VERSION ""

NS_ :

BS_:

BU_: FRM ADC CRFL CRFR CRRL CRRR AVP APA

BO_ 3221225472 VECTOR__INDEPENDENT_SIG_MSG: 0 Vector__XXX
 SG_ CRRL_KeepAwakePwrMode : 0|1@0+ (1,0) [0|1] "" Vector__XXX
 SG_ CRRL_KeepAwakeReasDiag : 0|1@0+ (1,0) [0|1] "" Vector__XXX
 SG_ CRRL_KeepAwakeReasLocalFunReq : 0|5@0+ (1,0) [0|31] "" Vector__XXX
 SG_ CRRL_KeepAwakeSta : 0|1@0+ (1,0) [0|1] "" Vector__XXX
 SG_ CRRR_WakeupReas : 0|8@0+ (1,0) [0|255] "" Vector__XXX
 SG_ CRRR_KeepAwakePwrMode : 0|1@0+ (1,0) [0|1] "" Vector__XXX
 SG_ CRRR_KeepAwakeReasDiag : 0|1@0+ (1,0) [0|1] "" Vector__XXX
 SG_ CRRR_KeepAwakeReasLocalFunReq : 0|5@0+ (1,0) [0|31] "" Vector__XXX
 SG_ CRRR_KeepAwakeSta : 0|1@0+ (1,0) [0|1] "" Vector__XXX
 SG_ AVP_WakeupReas : 0|8@0+ (1,0) [0|255] "" Vector__XXX
 SG_ AVP_KeepAwakePwrMode : 0|1@0+ (1,0) [0|1] "" Vector__XXX
 SG_ AVP_KeepAwakeReasDiag : 0|1@0+ (1,0) [0|1] "" Vector__XXX
 SG_ AVP_KeepAwakeReasLocalFunReq : 0|5@0+ (1,0) [0|31] "" Vector__XXX
 SG_ AVP_KeepAwakeSta : 0|1@0+ (1,0) [0|1] "" Vector__XXX
 SG_ Diag_PhyReq_FRM_Data0 : 0|64@0+ (1,0) [0|0] "" Vector__XXX
 SG_ Diag_PhyReq_FRM_Data1 : 0|64@0+ (1,0) [0|0] "" Vector__XXX
 SG_ Diag_PhyReq_FRM_Data2 : 0|64@0+ (1,0) [0|0] "" Vector__XXX
 SG_ Diag_PhyReq_FRM_Data3 : 0|64@0+ (1,0) [0|0] "" Vector__XXX
 SG_ Diag_PhyReq_FRM_Data4 : 0|64@0+ (1,0) [0|0] "" Vector__XXX
 SG_ Diag_PhyReq_FRM_Data5 : 0|64@0+ (1,0) [0|0] "" Vector__XXX
 SG_ Diag_PhyReq_FRM_Data6 : 0|64@0+ (1,0) [0|0] "" Vector__XXX
 SG_ Diag_PhyReq_FRM_Data7 : 0|64@0+ (1,0) [0|0] "" Vector__XXX
 SG_ Diag_PhyReq_FCM_Data0 : 0|64@0+ (1,0) [0|0] "" Vector__XXX
 SG_ Diag_PhyReq_FCM_Data1 : 0|64@0+ (1,0) [0|0] "" Vector__XXX
 SG_ Diag_PhyReq_FCM_Data2 : 0|64@0+ (1,0) [0|0] "" Vector__XXX
 SG_ Diag_PhyReq_FCM_Data3 : 0|64@0+ (1,0) [0|0] "" Vector__XXX
 SG_ Diag_PhyReq_FCM_Data4 : 0|64@0+ (1,0) [0|0] "" Vector__XXX
 SG_ Diag_PhyReq_FCM_Data5 : 0|64@0+ (1,0) [0|0] "" Vector__XXX
 SG_ Diag_PhyReq_FCM_Data6 : 0|64@0+ (1,0) [0|0] "" Vector__XXX
 SG_ Diag_PhyReq_FCM_Data7 : 0|64@0+ (1,0) [0|0] "" Vector__XXX
 SG_ Diag_PhyReq_APA_Data0 : 0|64@0+ (1,0) [0|0] "" Vector__XXX
 SG_ Diag_PhyReq_APA_Data1 : 0|64@0+ (1,0) [0|0] "" Vector__XXX
 SG_ Diag_PhyReq_APA_Data2 : 0|64@0+ (1,0) [0|0] "" Vector__XXX
 SG_ Diag_PhyReq_APA_Data3 : 0|64@0+ (1,0) [0|0] "" Vector__XXX
 SG_ Diag_PhyReq_APA_Data4 : 0|64@0+ (1,0) [0|0] "" Vector__XXX
 SG_ Diag_PhyReq_APA_Data5 : 0|64@0+ (1,0) [0|0] "" Vector__XXX
 SG_ Diag_PhyReq_APA_Data6 : 0|64@0+ (1,0) [0|0] "" Vector__XXX
 SG_ Diag_PhyReq_APA_Data7 : 0|64@0+ (1,0) [0|0] "" Vector__XXX
 SG_ Diag_PhyReq_AVP_Data0 : 0|64@0+ (1,0) [0|0] "" Vector__XXX
 SG_ Diag_PhyReq_AVP_Data1 : 0|64@0+ (1,0) [0|0] "" Vector__XXX
 SG_ Diag_PhyReq_AVP_Data2 : 0|64@0+ (1,0) [0|0] "" Vector__XXX
 SG_ Diag_PhyReq_AVP_Data3 : 0|64@0+ (1,0) [0|0] "" Vector__XXX
 SG_ Diag_PhyReq_AVP_Data4 : 0|64@0+ (1,0) [0|0] "" Vector__XXX
 SG_ Diag_PhyReq_AVP_Data5 : 0|64@0+ (1,0) [0|0] "" Vector__XXX
 SG_ Diag_PhyReq_AVP_Data6 : 0|64@0+ (1,0) [0|0] "" Vector__XXX
 SG_ Diag_PhyReq_AVP_Data7 : 0|64@0+ (1,0) [0|0] "" Vector__XXX
 SG_ Diag_PhyReq_ADC_Data0 : 0|64@0+ (1,0) [0|0] "" Vector__XXX
 SG_ Diag_PhyReq_ADC_Data1 : 0|64@0+ (1,0) [0|0] "" Vector__XXX
 SG_ Diag_PhyReq_ADC_Data2 : 0|64@0+ (1,0) [0|0] "" Vector__XXX
 SG_ Diag_PhyReq_ADC_Data3 : 0|64@0+ (1,0) [0|0] "" Vector__XXX
 SG_ Diag_PhyReq_ADC_Data4 : 0|64@0+ (1,0) [0|0] "" Vector__XXX
 SG_ Diag_PhyReq_ADC_Data5 : 0|64@0+ (1,0) [0|0] "" Vector__XXX
 SG_ Diag_PhyReq_ADC_Data6 : 0|64@0+ (1,0) [0|0] "" Vector__XXX
 SG_ Diag_PhyReq_ADC_Data7 : 0|64@0+ (1,0) [0|0] "" Vector__XXX
 SG_ Diag_PhyReq_CRFL_Data0 : 0|64@0+ (1,0) [0|0] "" Vector__XXX
 SG_ Diag_PhyReq_CRFL_Data1 : 0|64@0+ (1,0) [0|0] "" Vector__XXX
 SG_ Diag_PhyReq_CRFL_Data2 : 0|64@0+ (1,0) [0|0] "" Vector__XXX
 SG_ Diag_PhyReq_CRFL_Data3 : 0|64@0+ (1,0) [0|0] "" Vector__XXX
 SG_ Diag_PhyReq_CRFL_Data4 : 0|64@0+ (1,0) [0|0] "" Vector__XXX
 SG_ Diag_PhyReq_CRFL_Data5 : 0|64@0+ (1,0) [0|0] "" Vector__XXX
 SG_ Diag_PhyReq_CRFL_Data6 : 0|64@0+ (1,0) [0|0] "" Vector__XXX
 SG_ Diag_PhyReq_CRFL_Data7 : 0|64@0+ (1,0) [0|0] "" Vector__XXX
 SG_ Diag_PhyReq_CRFR_Data0 : 0|64@0+ (1,0) [0|0] "" Vector__XXX
 SG_ Diag_PhyReq_CRFR_Data1 : 0|64@0+ (1,0) [0|0] "" Vector__XXX
 SG_ Diag_PhyReq_CRFR_Data2 : 0|64@0+ (1,0) [0|0] "" Vector__XXX
 SG_ Diag_PhyReq_CRFR_Data3 : 0|64@0+ (1,0) [0|0] "" Vector__XXX
 SG_ Diag_PhyReq_CRFR_Data4 : 0|64@0+ (1,0) [0|0] "" Vector__XXX
 SG_ Diag_PhyReq_CRFR_Data5 : 0|64@0+ (1,0) [0|0] "" Vector__XXX
 SG_ Diag_PhyReq_CRFR_Data6 : 0|64@0+ (1,0) [0|0] "" Vector__XXX
 SG_ Diag_PhyReq_CRFR_Data7 : 0|64@0+ (1,0) [0|0] "" Vector__XXX
 SG_ Diag_PhyReq_CRRL_Data0 : 0|64@0+ (1,0) [0|0] "" Vector__XXX
 SG_ Diag_PhyReq_CRRL_Data1 : 0|64@0+ (1,0) [0|0] "" Vector__XXX
 SG_ Diag_PhyReq_CRRL_Data2 : 0|64@0+ (1,0) [0|0] "" Vector__XXX
 SG_ Diag_PhyReq_CRRL_Data3 : 0|64@0+ (1,0) [0|0] "" Vector__XXX
 SG_ Diag_PhyReq_CRRL_Data4 : 0|64@0+ (1,0) [0|0] "" Vector__XXX
 SG_ Diag_PhyReq_CRRL_Data5 : 0|64@0+ (1,0) [0|0] "" Vector__XXX
 SG_ Diag_PhyReq_CRRL_Data6 : 0|64@0+ (1,0) [0|0] "" Vector__XXX
 SG_ Diag_PhyReq_CRRL_Data7 : 0|64@0+ (1,0) [0|0] "" Vector__XXX
 SG_ Diag_PhyReq_CRRR_Data0 : 0|64@0+ (1,0) [0|0] "" Vector__XXX
 SG_ Diag_PhyReq_CRRR_Data1 : 0|64@0+ (1,0) [0|0] "" Vector__XXX
 SG_ Diag_PhyReq_CRRR_Data2 : 0|64@0+ (1,0) [0|0] "" Vector__XXX
 SG_ Diag_PhyReq_CRRR_Data3 : 0|64@0+ (1,0) [0|0] "" Vector__XXX
 SG_ Diag_PhyReq_CRRR_Data4 : 0|64@0+ (1,0) [0|0] "" Vector__XXX
 SG_ Diag_PhyReq_CRRR_Data5 : 0|64@0+ (1,0) [0|0] "" Vector__XXX
 SG_ Diag_PhyReq_CRRR_Data6 : 0|64@0+ (1,0) [0|0] "" Vector__XXX
 SG_ Diag_PhyReq_CRRR_Data7 : 0|64@0+ (1,0) [0|0] "" Vector__XXX
 SG_ Diag_Resp_FRM_Data0 : 0|64@0+ (1,0) [0|0] "" Vector__XXX
 SG_ Diag_Resp_FRM_Data1 : 0|64@0+ (1,0) [0|0] "" Vector__XXX
 SG_ Diag_Resp_FRM_Data2 : 0|64@0+ (1,0) [0|0] "" Vector__XXX
 SG_ Diag_Resp_FRM_Data3 : 0|64@0+ (1,0) [0|0] "" Vector__XXX
 SG_ Diag_Resp_FRM_Data4 : 0|64@0+ (1,0) [0|0] "" Vector__XXX
 SG_ Diag_Resp_FRM_Data5 : 0|64@0+ (1,0) [0|0] "" Vector__XXX
 SG_ Diag_Resp_FRM_Data6 : 0|64@0+ (1,0) [0|0] "" Vector__XXX
 SG_ Diag_Resp_FRM_Data7 : 0|64@0+ (1,0) [0|0] "" Vector__XXX
 SG_ Diag_Resp_FCM_Data0 : 0|64@0+ (1,0) [0|0] "" Vector__XXX
 SG_ Diag_Resp_FCM_Data1 : 0|64@0+ (1,0) [0|0] "" Vector__XXX
 SG_ Diag_Resp_FCM_Data2 : 0|64@0+ (1,0) [0|0] "" Vector__XXX
 SG_ Diag_Resp_FCM_Data3 : 0|64@0+ (1,0) [0|0] "" Vector__XXX
 SG_ Diag_Resp_FCM_Data4 : 0|64@0+ (1,0) [0|0] "" Vector__XXX
 SG_ Diag_Resp_FCM_Data5 : 0|64@0+ (1,0) [0|0] "" Vector__XXX
 SG_ Diag_Resp_FCM_Data6 : 0|64@0+ (1,0) [0|0] "" Vector__XXX
 SG_ Diag_Resp_FCM_Data7 : 0|64@0+ (1,0) [0|0] "" Vector__XXX
 SG_ Diag_Resp_APA_Data0 : 0|64@0+ (1,0) [0|0] "" Vector__XXX
 SG_ Diag_Resp_APA_Data1 : 0|64@0+ (1,0) [0|0] "" Vector__XXX
 SG_ Diag_Resp_APA_Data2 : 0|64@0+ (1,0) [0|0] "" Vector__XXX
 SG_ Diag_Resp_APA_Data3 : 0|64@0+ (1,0) [0|0] "" Vector__XXX
 SG_ Diag_Resp_APA_Data4 : 0|64@0+ (1,0) [0|0] "" Vector__XXX
 SG_ Diag_Resp_APA_Data5 : 0|64@0+ (1,0) [0|0] "" Vector__XXX
 SG_ Diag_Resp_APA_Data6 : 0|64@0+ (1,0) [0|0] "" Vector__XXX
 SG_ Diag_Resp_APA_Data7 : 0|64@0+ (1,0) [0|0] "" Vector__XXX
 SG_ Diag_Resp_ADC_Data0 : 0|64@0+ (1,0) [0|0] "" Vector__XXX
 SG_ Diag_Resp_ADC_Data1 : 0|64@0+ (1,0) [0|0] "" Vector__XXX
 SG_ Diag_Resp_ADC_Data2 : 0|64@0+ (1,0) [0|0] "" Vector__XXX
 SG_ Diag_Resp_ADC_Data3 : 0|64@0+ (1,0) [0|0] "" Vector__XXX
 SG_ Diag_Resp_ADC_Data4 : 0|64@0+ (1,0) [0|0] "" Vector__XXX
 SG_ Diag_Resp_ADC_Data5 : 0|64@0+ (1,0) [0|0] "" Vector__XXX
 SG_ Diag_Resp_ADC_Data6 : 0|64@0+ (1,0) [0|0] "" Vector__XXX
 SG_ Diag_Resp_ADC_Data7 : 0|64@0+ (1,0) [0|0] "" Vector__XXX
 SG_ Diag_Resp_CRFL_Data0 : 0|64@0+ (1,0) [0|0] "" Vector__XXX
 SG_ Diag_Resp_CRFL_Data1 : 0|64@0+ (1,0) [0|0] "" Vector__XXX
 SG_ Diag_Resp_CRFL_Data2 : 0|64@0+ (1,0) [0|0] "" Vector__XXX
 SG_ Diag_Resp_CRFL_Data3 : 0|64@0+ (1,0) [0|0] "" Vector__XXX
 SG_ Diag_Resp_CRFL_Data4 : 0|64@0+ (1,0) [0|0] "" Vector__XXX
 SG_ Diag_Resp_CRFL_Data5 : 0|64@0+ (1,0) [0|0] "" Vector__XXX
 SG_ Diag_Resp_CRFL_Data6 : 0|64@0+ (1,0) [0|0] "" Vector__XXX
 SG_ Diag_Resp_CRFL_Data7 : 0|64@0+ (1,0) [0|0] "" Vector__XXX
 SG_ Diag_Resp_CRFR_Data0 : 0|64@0+ (1,0) [0|0] "" Vector__XXX
 SG_ Diag_Resp_CRFR_Data1 : 0|64@0+ (1,0) [0|0] "" Vector__XXX
 SG_ Diag_Resp_CRFR_Data2 : 0|64@0+ (1,0) [0|0] "" Vector__XXX
 SG_ Diag_Resp_CRFR_Data3 : 0|64@0+ (1,0) [0|0] "" Vector__XXX
 SG_ Diag_Resp_CRFR_Data4 : 0|64@0+ (1,0) [0|0] "" Vector__XXX
 SG_ Diag_Resp_CRFR_Data5 : 0|64@0+ (1,0) [0|0] "" Vector__XXX
 SG_ Diag_Resp_CRFR_Data6 : 0|64@0+ (1,0) [0|0] "" Vector__XXX
 SG_ Diag_Resp_CRFR_Data7 : 0|64@0+ (1,0) [0|0] "" Vector__XXX
 SG_ Diag_Resp_CRRL_Data0 : 0|64@0+ (1,0) [0|0] "" Vector__XXX
 SG_ Diag_Resp_CRRL_Data1 : 0|64@0+ (1,0) [0|0] "" Vector__XXX
 SG_ Diag_Resp_CRRL_Data2 : 0|64@0+ (1,0) [0|0] "" Vector__XXX
 SG_ Diag_Resp_CRRL_Data3 : 0|64@0+ (1,0) [0|0] "" Vector__XXX
 SG_ Diag_Resp_CRRL_Data4 : 0|64@0+ (1,0) [0|0] "" Vector__XXX
 SG_ Diag_Resp_CRRL_Data5 : 0|64@0+ (1,0) [0|0] "" Vector__XXX
 SG_ Diag_Resp_CRRL_Data6 : 0|64@0+ (1,0) [0|0] "" Vector__XXX
 SG_ Diag_Resp_CRRL_Data7 : 0|64@0+ (1,0) [0|0] "" Vector__XXX
 SG_ Diag_Resp_CRRR_Data0 : 0|64@0+ (1,0) [0|0] "" Vector__XXX
 SG_ Diag_Resp_CRRR_Data1 : 0|64@0+ (1,0) [0|0] "" Vector__XXX
 SG_ Diag_Resp_CRRR_Data2 : 0|64@0+ (1,0) [0|0] "" Vector__XXX
 SG_ Diag_Resp_CRRR_Data3 : 0|64@0+ (1,0) [0|0] "" Vector__XXX
 SG_ Diag_Resp_CRRR_Data4 : 0|64@0+ (1,0) [0|0] "" Vector__XXX
 SG_ Diag_Resp_CRRR_Data5 : 0|64@0+ (1,0) [0|0] "" Vector__XXX
 SG_ Diag_Resp_CRRR_Data6 : 0|64@0+ (1,0) [0|0] "" Vector__XXX
 SG_ Diag_Resp_CRRR_Data7 : 0|64@0+ (1,0) [0|0] "" Vector__XXX
 SG_ Diag_Resp_AVP_Data0 : 0|64@0+ (1,0) [0|0] "" Vector__XXX
 SG_ Diag_Resp_AVP_Data1 : 0|64@0+ (1,0) [0|0] "" Vector__XXX
 SG_ Diag_Resp_AVP_Data2 : 0|64@0+ (1,0) [0|0] "" Vector__XXX
 SG_ Diag_Resp_AVP_Data3 : 0|64@0+ (1,0) [0|0] "" Vector__XXX
 SG_ Diag_Resp_AVP_Data4 : 0|64@0+ (1,0) [0|0] "" Vector__XXX
 SG_ Diag_Resp_AVP_Data5 : 0|64@0+ (1,0) [0|0] "" Vector__XXX
 SG_ Diag_Resp_AVP_Data6 : 0|64@0+ (1,0) [0|0] "" Vector__XXX
 SG_ Diag_Resp_AVP_Data7 : 0|64@0+ (1,0) [0|0] "" Vector__XXX
 SG_ Diag_FuncReq_Data0 : 0|64@0+ (1,0) [0|0] "" Vector__XXX
 SG_ Diag_FuncReq_Data1 : 0|64@0+ (1,0) [0|0] "" Vector__XXX
 SG_ Diag_FuncReq_Data2 : 0|64@0+ (1,0) [0|0] "" Vector__XXX
 SG_ Diag_FuncReq_Data3 : 0|64@0+ (1,0) [0|0] "" Vector__XXX
 SG_ Diag_FuncReq_Data4 : 0|64@0+ (1,0) [0|0] "" Vector__XXX
 SG_ Diag_FuncReq_Data5 : 0|64@0+ (1,0) [0|0] "" Vector__XXX
 SG_ Diag_FuncReq_Data6 : 0|64@0+ (1,0) [0|0] "" Vector__XXX
 SG_ Diag_FuncReq_Data7 : 0|64@0+ (1,0) [0|0] "" Vector__XXX

BO_ 464 AVP_B: 64 Vector__XXX
 SG_ AVP_B_Chksum : 63|8@0+ (1,0) [0|255] "" Vector__XXX
 SG_ AVP_B_AliveCnt : 51|4@0+ (1,0) [0|15] "" Vector__XXX

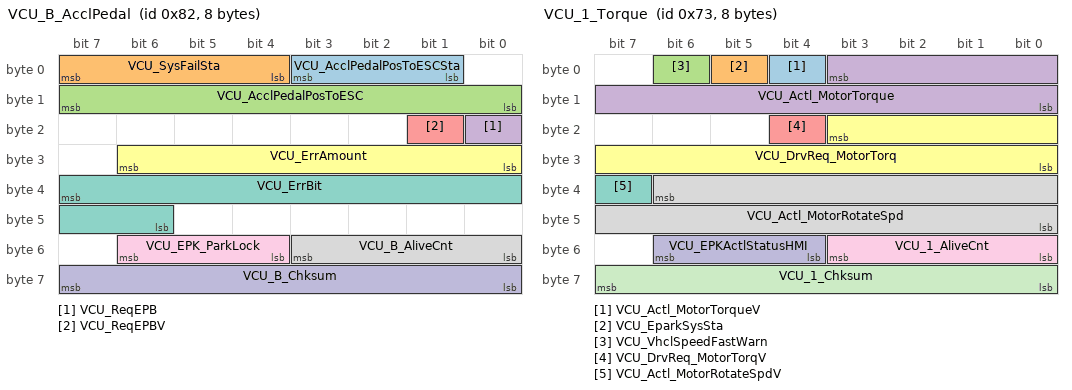
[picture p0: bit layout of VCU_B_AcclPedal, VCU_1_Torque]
BO_ 130 VCU_B_AcclPedal: 8 Vector__XXX
 SG_ VCU_AcclPedalPosToESCSta : 3|3@0+ (1,0) [0|4] "" Vector__XXX
 SG_ VCU_SysFailSta : 7|4@0+ (1,0) [0|15] "" Vector__XXX
 SG_ VCU_AcclPedalPosToESC : 15|8@0+ (0.4,0) [0|100] "%" Vector__XXX
 SG_ VCU_ReqEPB : 16|1@0+ (1,0) [0|1] "" Vector__XXX
 SG_ VCU_ReqEPBV : 17|1@0+ (1,0) [0|1] "" Vector__XXX
 SG_ VCU_ErrAmount : 30|7@0+ (1,0) [0|127] "" Vector__XXX
 SG_ VCU_ErrBit : 39|10@0+ (1,0) [0|1023] "" Vector__XXX
 SG_ VCU_B_AliveCnt : 51|4@0+ (1,0) [0|15] "" Vector__XXX
 SG_ VCU_EPK_ParkLock : 54|3@0+ (1,0) [0|7] "" Vector__XXX
 SG_ VCU_B_Chksum : 63|8@0+ (1,0) [0|255] "" Vector__XXX

BO_ 388 AVP_A: 64 Vector__XXX
 SG_ AVP_HAVP_Recover_Indication : 2|3@0+ (1,0) [0|7] "" Vector__XXX
 SG_ AVP_HAVP_Quit_Indication : 7|5@0+ (1,0) [0|31] "" Vector__XXX
 SG_ AVP_HAVP_System_Info : 11|4@0+ (1,0) [0|15] "" Vector__XXX
 SG_ AVP_VP_Info_Apply_P_EPB : 16|1@0+ (1,0) [0|1] "" Vector__XXX
 SG_ AVP_VP_Info_Stop_Charging : 17|1@0+ (1,0) [0|1] "" Vector__XXX
 SG_ AVP_VP_Info_Vechicle_PowerOff : 18|1@0+ (1,0) [0|1] "" Vector__XXX
 SG_ AVP_VP_Quit_Indication : 23|5@0+ (1,0) [0|31] "" Vector__XXX
 SG_ AVP_VP_Recover_Indication : 26|3@0+ (1,0) [0|7] "" Vector__XXX
 SG_ AVP_VP_System_Info : 31|5@0+ (1,0) [0|31] "" Vector__XXX
 SG_ AVP_Aeb_TgtAx : 39|8@0+ (0.05,-10) [-10|0] "m/s2" Vector__XXX
 SG_ AVP_AebReqEna : 52|1@0+ (1,0) [0|1] "" Vector__XXX
 SG_ AVP_decFlg : 53|1@0+ (1,0) [0|1] "" Vector__XXX
 SG_ AVP_AccReq_DrvOff : 54|1@0+ (1,0) [0|1] "" Vector__XXX
 SG_ AVP_AccReq_Standstill : 55|1@0+ (1,0) [0|1] "" Vector__XXX
 SG_ AVP_A_AliveCnt : 51|4@0+ (1,0) [0|15] "" Vector__XXX
 SG_ AVP_A_Chksum : 63|8@0+ (1,0) [0|255] "" Vector__XXX
 SG_ AVP_LogoLamp_Req : 65|2@0+ (1,0) [0|3] "" Vector__XXX
 SG_ AVP_HighBeamLamp_Req : 66|1@0+ (1,0) [0|1] "" Vector__XXX
 SG_ AVP_LowBeamLamp_Req : 67|1@0+ (1,0) [0|1] "" Vector__XXX
 SG_ AVP_HazardLamp_Req : 68|1@0+ (1,0) [0|1] "" Vector__XXX
 SG_ AVP_TurnLeftLamp_Req : 69|1@0+ (1,0) [0|1] "" Vector__XXX
 SG_ AVP_TurnRightLamp_Req : 70|1@0+ (1,0) [0|1] "" Vector__XXX
 SG_ AVP_Horn_Req : 71|1@0+ (1,0) [0|1] "" Vector__XXX
 SG_ AVP_Wiper_Req : 76|1@0+ (1,0) [0|1] "" Vector__XXX
 SG_ AVP_WaterSpray_Req : 77|1@0+ (1,0) [0|1] "" Vector__XXX
 SG_ AVP_PwrMode_Req : 79|2@0+ (1,0) [0|3] "" Vector__XXX
 SG_ AVP_Acc_MotorTorqReqValue : 75|12@0+ (0.5,-1000) [-1000|1000] "Nm" Vector__XXX
 SG_ AVP_AccTrqReqEna : 88|1@0+ (1,0) [0|1] "" Vector__XXX
 SG_ AVP_FctSts : 90|2@0+ (1,0) [0|3] "" Vector__XXX
 SG_ AVP_Runng : 91|1@0+ (1,0) [0|1] "" Vector__XXX
 SG_ AVP_Acc_TgtAxReq : 92|1@0+ (1,0) [0|1] "" Vector__XXX
 SG_ AVP_Acc_Mode : 95|3@0+ (1,0) [0|7] "" Vector__XXX
 SG_ AVP_Acc_TgtAx : 103|8@0+ (0.05,-9.5) [-9.5|3.25] "m/s2" Vector__XXX
 SG_ AVP_HAVP_Status : 106|3@0+ (1,0) [0|7] "" Vector__XXX
 SG_ AVP_VP_Status : 109|3@0+ (1,0) [0|7] "" Vector__XXX
 SG_ AVP_TrgtGearReq : 118|3@0+ (1,0) [0|7] "" Vector__XXX
 SG_ AVP_TrgtGearReqV : 119|1@0+ (1,0) [0|1] "" Vector__XXX
 SG_ AVP_HAVP_StrtgEndgPointInfo : 132|5@0+ (1,0) [0|31] "" Vector__XXX
 SG_ AVP_HAVP_Learning_Failed_Info : 139|4@0+ (1,0) [0|15] "" Vector__XXX
 SG_ AVP_Learning_PathNum1 : 143|4@0+ (1,0) [0|15] "" Vector__XXX
 SG_ AVP_HAVP_Learning_Process_Info : 148|5@0+ (1,0) [0|31] "" Vector__XXX
 SG_ AVP_Learning_PathType1 : 150|2@0+ (1,0) [0|3] "" Vector__XXX
 SG_ AVP_Learning_LotType1 : 153|2@0+ (1,0) [0|3] "" Vector__XXX
 SG_ AVP_HAVP_Path_Status1 : 155|2@0+ (1,0) [0|3] "" Vector__XXX
 SG_ AVP_HAVP_Path_Learnrate1 : 159|4@0+ (10,0) [0|90] "%" Vector__XXX
 SG_ AVP_Learning_PathNum2 : 163|4@0+ (1,0) [0|15] "" Vector__XXX
 SG_ AVP_Learning_PathType2 : 165|2@0+ (1,0) [0|3] "" Vector__XXX
 SG_ AVP_Learning_LotType2 : 167|2@0+ (1,0) [0|3] "" Vector__XXX
 SG_ AVP_HAVP_Path_Status2 : 169|2@0+ (1,0) [0|3] "" Vector__XXX
 SG_ AVP_HAVP_Path_Learnrate2 : 173|4@0+ (10,0) [0|90] "%" Vector__XXX
 SG_ AVP_Learning_PathType3 : 175|2@0+ (1,0) [0|3] "" Vector__XXX
 SG_ AVP_Learning_PathNum3 : 183|4@0+ (1,0) [0|15] "" Vector__XXX
 SG_ AVP_Learning_LotType3 : 193|2@0+ (1,0) [0|3] "" Vector__XXX
 SG_ AVP_HAVP_Path_Status3 : 195|2@0+ (1,0) [0|3] "" Vector__XXX
 SG_ AVP_HAVP_Path_Learnrate3 : 199|4@0+ (10,0) [0|90] "%" Vector__XXX
 SG_ AVP_Learning_PathNum4 : 203|4@0+ (1,0) [0|15] "" Vector__XXX
 SG_ AVP_Learning_PathType4 : 205|2@0+ (1,0) [0|3] "" Vector__XXX
 SG_ AVP_Learning_LotType4 : 207|2@0+ (1,0) [0|3] "" Vector__XXX
 SG_ AVP_HAVP_Path_Status4 : 209|2@0+ (1,0) [0|3] "" Vector__XXX
 SG_ AVP_HAVP_Path_Learnrate4 : 213|4@0+ (10,0) [0|90] "%" Vector__XXX
 SG_ AVP_Learning_PathType5 : 215|2@0+ (1,0) [0|3] "" Vector__XXX
 SG_ AVP_Learning_PathNum5 : 219|4@0+ (1,0) [0|15] "" Vector__XXX
 SG_ AVP_Learning_LotType5 : 221|2@0+ (1,0) [0|3] "" Vector__XXX
 SG_ AVP_HAVP_Path_Status5 : 223|2@0+ (1,0) [0|3] "" Vector__XXX
 SG_ AVP_HAVP_Path_Learnrate5 : 227|4@0+ (10,0) [0|90] "%" Vector__XXX
 SG_ AVP_LrngDst : 275|12@0+ (0.1,0) [0|400] "m" Vector__XXX
 SG_ AVP_HAVP_ProcRat : 295|8@0+ (1,0) [0|100] "%" Vector__XXX
 SG_ AVP_HAVP_PahDst1 : 303|12@0+ (0.1,0) [0|400] "m" Vector__XXX
 SG_ AVP_HAVP_PahDst2 : 327|12@0+ (0.1,0) [0|400] "m" Vector__XXX
 SG_ AVP_HAVP_PahDst3 : 331|12@0+ (0.1,0) [0|400] "m" Vector__XXX
 SG_ AVP_HAVP_PahDst4 : 351|12@0+ (0.1,0) [0|400] "m" Vector__XXX
 SG_ AVP_HAVP_PahDst5 : 355|12@0+ (0.1,0) [0|400] "m" Vector__XXX
 SG_ AVP_HAVP_DrvrReq : 388|5@0+ (1,0) [0|31] "" Vector__XXX
 SG_ AVP_FrntCamCalSts : 391|3@0+ (1,0) [0|7] "" Vector__XXX
 SG_ AVP_LrngDst_LeOver : 393|10@0+ (1,0) [0|1022] "m" Vector__XXX

BO_ 115 VCU_1_Torque: 8 Vector__XXX
 SG_ VCU_Actl_MotorTorqueV : 4|1@0+ (1,0) [0|1] "" Vector__XXX
 SG_ VCU_EparkSysSta : 5|1@0+ (1,0) [0|1] "" Vector__XXX
 SG_ VCU_VhclSpeedFastWarn : 6|1@0+ (1,0) [0|1] "" Vector__XXX
 SG_ VCU_Actl_MotorTorque : 3|12@0+ (0.5,-1000) [-1000|1000] "" Vector__XXX
 SG_ VCU_DrvReq_MotorTorqV : 20|1@0+ (1,0) [0|1] "" Vector__XXX
 SG_ VCU_DrvReq_MotorTorq : 19|12@0+ (0.5,-1000) [-1000|1000] "" Vector__XXX
 SG_ VCU_Actl_MotorRotateSpdV : 39|1@0+ (1,0) [0|1] "" Vector__XXX
 SG_ VCU_Actl_MotorRotateSpd : 38|15@0+ (1,-10000) [-10000|15000] "r/min" Vector__XXX
 SG_ VCU_1_AliveCnt : 51|4@0+ (1,0) [0|15] "" Vector__XXX
 SG_ VCU_EPKActlStatusHMI : 54|3@0+ (1,0) [0|7] "" Vector__XXX
 SG_ VCU_1_Chksum : 63|8@0+ (1,0) [0|255] "" Vector__XXX

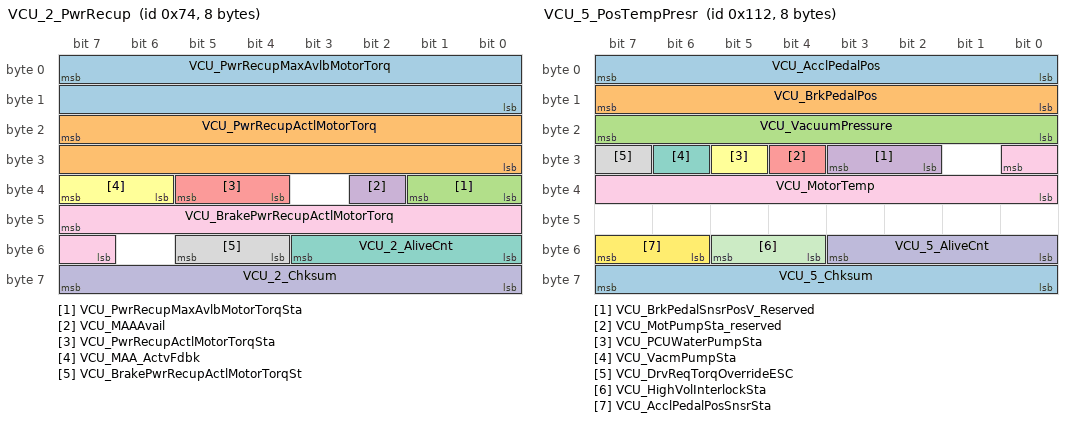
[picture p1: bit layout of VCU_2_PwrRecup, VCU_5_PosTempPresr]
BO_ 116 VCU_2_PwrRecup: 8 Vector__XXX
 SG_ VCU_PwrRecupMaxAvlbMotorTorq : 7|16@0+ (1,-32768) [-32768|0] "" Vector__XXX
 SG_ VCU_PwrRecupActlMotorTorq : 23|16@0+ (1,-32768) [-32768|32767] "" Vector__XXX
 SG_ VCU_PwrRecupMaxAvlbMotorTorqSta : 33|2@0+ (1,0) [0|3] "" Vector__XXX
 SG_ VCU_MAAAvail : 34|1@0+ (1,0) [0|1] "" Vector__XXX
 SG_ VCU_PwrRecupActlMotorTorqSta : 37|2@0+ (1,0) [0|3] "" Vector__XXX
 SG_ VCU_MAA_ActvFdbk : 39|2@0+ (1,0) [0|3] "" Vector__XXX
 SG_ VCU_2_AliveCnt : 51|4@0+ (1,0) [0|15] "" Vector__XXX
 SG_ VCU_BrakePwrRecupActlMotorTorqSt : 53|2@0+ (1,0) [0|3] "" Vector__XXX
 SG_ VCU_BrakePwrRecupActlMotorTorq : 47|9@0+ (1,-510) [-510|0] "Nm" Vector__XXX
 SG_ VCU_2_Chksum : 63|8@0+ (1,0) [0|255] "" Vector__XXX

BO_ 274 VCU_5_PosTempPresr: 8 Vector__XXX
 SG_ VCU_AcclPedalPos : 7|8@0+ (0.4,0) [0|100] "%" Vector__XXX
 SG_ VCU_BrkPedalPos : 15|8@0+ (0.4,0) [0|100] "%" Vector__XXX
 SG_ VCU_VacuumPressure : 23|8@0+ (5,0) [0|1275] "mbar" Vector__XXX
 SG_ VCU_BrkPedalSnsrPosV_Reserved : 27|2@0+ (1,0) [0|3] "" Vector__XXX
 SG_ VCU_MotPumpSta_reserved : 28|1@0+ (1,0) [0|1] "" Vector__XXX
 SG_ VCU_PCUWaterPumpSta : 29|1@0+ (1,0) [0|1] "" Vector__XXX
 SG_ VCU_VacmPumpSta : 30|1@0+ (1,0) [0|1] "" Vector__XXX
 SG_ VCU_DrvReqTorqOverrideESC : 31|1@0+ (1,0) [0|1] "" Vector__XXX
 SG_ VCU_MotorTemp : 24|9@0+ (1,-40) [-40|300] "℃" Vector__XXX
 SG_ VCU_5_AliveCnt : 51|4@0+ (1,0) [0|15] "" Vector__XXX
 SG_ VCU_HighVolInterlockSta : 53|2@0+ (1,0) [0|3] "" Vector__XXX
 SG_ VCU_AcclPedalPosSnsrSta : 55|2@0+ (1,0) [0|3] "" Vector__XXX
 SG_ VCU_5_Chksum : 63|8@0+ (1,0) [0|255] "" Vector__XXX

BO_ 281 BCM_4_CruiseSw_PM: 8 Vector__XXX
 SG_ BCM_CruiseDistanceIncre : 0|1@0+ (1,0) [0|1] "" Vector__XXX
 SG_ BCM_CruiseDistanceDecre : 1|1@0+ (1,0) [0|1] "" Vector__XXX
 SG_ BCM_CruiseModeCancel : 2|1@0+ (1,0) [0|1] "" Vector__XXX
 SG_ BCM_CruiseRES : 3|1@0+ (1,0) [0|1] "" Vector__XXX
 SG_ BCM_CruiseSET : 4|1@0+ (1,0) [0|1] "" Vector__XXX
 SG_ BCM_CruiseModeChange : 5|1@0+ (1,0) [0|1] "" Vector__XXX
 SG_ BCM_CruiseRES_Valid : 6|1@0+ (1,0) [0|1] "" Vector__XXX
 SG_ BCM_CruiseMainSwitch : 7|1@0+ (1,0) [0|1] "" Vector__XXX
 SG_ BCM_SysPwrModeV : 8|1@0+ (1,0) [0|1] "" Vector__XXX
 SG_ BCM_SysPwrMode : 10|2@0+ (1,0) [0|3] "" Vector__XXX
 SG_ BCM_Cruise_limit_reserved : 11|1@0+ (1,0) [0|1] "" Vector__XXX
 SG_ BCM_HighBeamSwSta : 14|1@0+ (1,0) [0|1] "" Vector__XXX
 SG_ BCM_HMASta : 15|1@0+ (1,0) [0|1] "" Vector__XXX
 SG_ BCM_SysPowerSts : 18|3@0+ (1,0) [0|7] "" Vector__XXX
 SG_ BCM_StartReq : 20|2@0+ (1,0) [0|3] "" Vector__XXX
 SG_ BCM_ThermRunawayWarn : 23|2@0+ (1,0) [0|3] "" Vector__XXX
 SG_ BCM_vSetDis : 30|7@0+ (1,30) [30|130] "km/h" Vector__XXX
 SG_ BCM_ThermRunawaySnsrFlt : 31|1@0+ (1,0) [0|1] "" Vector__XXX
 SG_ BCM_4_AliveCnt : 51|4@0+ (1,0) [0|15] "" Vector__XXX
 SG_ BCM_4_Chksum : 63|8@0+ (1,0) [0|255] "" Vector__XXX

BO_ 288 ESC_A: 64 Vector__XXX
 SG_ ESC_DTC_ActiveSts : 0|1@0+ (1,0) [0|1] "" Vector__XXX
 SG_ ESC_BrakeTempOverHeat : 1|1@0+ (1,0) [0|1] "" Vector__XXX
 SG_ ESC_NoBrakeForce : 2|1@0+ (1,0) [0|1] "" Vector__XXX
 SG_ ESC_ABP_AvailableSta : 4|1@0+ (1,0) [0|1] "" Vector__XXX
 SG_ ESC_ABP_ActiveSta : 5|1@0+ (1,0) [0|1] "" Vector__XXX
 SG_ ESC_AEB_ActiveSta : 6|1@0+ (1,0) [0|1] "" Vector__XXX
 SG_ ESC_AEB_AvailableSta : 7|1@0+ (1,0) [0|1] "" Vector__XXX
 SG_ ESC_AWB_ActiveSta : 10|1@0+ (1,0) [0|1] "" Vector__XXX
 SG_ ESC_AWB_AvailableSta : 11|1@0+ (1,0) [0|1] "" Vector__XXX
 SG_ ESC_ABA_ActiveSta : 12|1@0+ (1,0) [0|1] "" Vector__XXX
 SG_ ESC_ABA_AvailableSta : 13|1@0+ (1,0) [0|1] "" Vector__XXX
 SG_ ESC_VhclStandstillSta : 15|2@0+ (1,0) [0|3] "" Vector__XXX
 SG_ ESC_RCTB_AvailableSta : 18|1@0+ (1,0) [0|1] "" Vector__XXX
 SG_ ESC_RCTB_ActiveSta : 19|1@0+ (1,0) [0|1] "" Vector__XXX
 SG_ ESC_HMI_WarningOn : 25|2@0+ (1,0) [0|3] "" Vector__XXX
 SG_ ESC_ParkPawlRequest : 26|1@0+ (1,0) [0|1] "" Vector__XXX
 SG_ ESC_ParkPawlRequestV : 27|1@0+ (1,0) [0|1] "" Vector__XXX
 SG_ ESC_LSMHldActv : 34|1@0+ (1,0) [0|1] "" Vector__XXX
 SG_ ESC_LSMSSMSta : 35|1@0+ (1,0) [0|1] "" Vector__XXX
 SG_ ESC_A_AliveCnt : 51|4@0+ (1,0) [0|15] "" Vector__XXX
 SG_ ESC_A_Chksum : 63|8@0+ (1,0) [0|255] "" Vector__XXX
 SG_ YRS_YawRate : 71|16@0+ (0.01,-180) [-180|180] "°/s" Vector__XXX
 SG_ YRS_LateralSensorState : 85|2@0+ (1,0) [0|3] "" Vector__XXX
 SG_ YRS_YawRateSensorState : 87|2@0+ (1,0) [0|3] "" Vector__XXX
 SG_ YRS_LateralAcce : 83|12@0+ (0.001,-2) [-2|2] "g" Vector__XXX
 SG_ YRS_LongitSensorState : 101|2@0+ (1,0) [0|3] "" Vector__XXX
 SG_ YRS_LongitAcce : 99|12@0+ (0.001,-2) [-2|2] "g" Vector__XXX
 SG_ ESC_MotorTorqDecReqActive : 132|1@0+ (1,0) [0|1] "" Vector__XXX
 SG_ ESC_MotorTorqDecReqValue : 131|12@0+ (0.5,-1000) [-1000|1000] "Nm" Vector__XXX
 SG_ ESC_MotorTorqIncReqActive : 148|1@0+ (1,0) [0|1] "" Vector__XXX
 SG_ ESC_PwrRecupTrgtMotorTorqSta : 151|3@0+ (1,0) [0|7] "" Vector__XXX
 SG_ ESC_MotorTorqIncReqValue : 147|12@0+ (0.5,-1000) [-1000|1000] "Nm" Vector__XXX
 SG_ ESC_PwrRecupTrgtMotorTorq : 167|16@0+ (1,-32768) [-32768|32767] "" Vector__XXX
 SG_ ESC_CDDAvailable : 196|1@0+ (1,0) [0|1] "" Vector__XXX
 SG_ ESC_CDDActive : 197|1@0+ (1,0) [0|1] "" Vector__XXX
 SG_ ESC_VLCAPMotorTorqReqActive : 198|1@0+ (1,0) [0|1] "" Vector__XXX
 SG_ ESC_VLCAPMotorTorqReqValue : 195|12@0+ (0.5,-1000) [-1000|1000] "Nm" Vector__XXX
 SG_ ESC_CDDTempOff : 208|1@0+ (1,0) [0|1] "" Vector__XXX
 SG_ ESC_Cruisecontrolshutdown : 209|1@0+ (1,0) [0|1] "" Vector__XXX
 SG_ ESC_CDDInternTrgtAccValue : 231|8@0+ (0.05,-7) [-7|5.75] "m/s2" Vector__XXX
 SG_ ESC_WheelSpeedKphV_FL : 261|1@0+ (1,0) [0|1] "" Vector__XXX
 SG_ ESC_WheelDirection_FL : 263|2@0+ (1,0) [0|3] "" Vector__XXX
 SG_ ESC_WheelSpeedKph_FL : 260|13@0+ (0.05625,0) [0|460.6875] "KPH" Vector__XXX
 SG_ ESC_WheelSpeedKphV_FR : 277|1@0+ (1,0) [0|1] "" Vector__XXX
 SG_ ESC_WheelDirection_FR : 279|2@0+ (1,0) [0|3] "" Vector__XXX
 SG_ ESC_WheelSpeedKph_FR : 276|13@0+ (0.05625,0) [0|460.6875] "KPH" Vector__XXX
 SG_ ESC_MasterCylinderPresr : 295|8@0+ (1,0) [0|254] "bar" Vector__XXX
 SG_ ESC_MasterCylinderPresrV : 303|1@0+ (1,0) [0|1] "" Vector__XXX
 SG_ ESC_WheelSpeedKphV_RL : 325|1@0+ (1,0) [0|1] "" Vector__XXX
 SG_ ESC_WheelDirection_RL : 327|2@0+ (1,0) [0|3] "" Vector__XXX
 SG_ ESC_WheelSpeedKph_RL : 324|13@0+ (0.05625,0) [0|460.6875] "KPH" Vector__XXX
 SG_ ESC_WheelSpeedKphV_RR : 341|1@0+ (1,0) [0|1] "" Vector__XXX
 SG_ ESC_WheelDirection_RR : 343|2@0+ (1,0) [0|3] "" Vector__XXX
 SG_ ESC_WheelSpeedKph_RR : 340|13@0+ (0.05625,0) [0|460.6875] "KPH" Vector__XXX
 SG_ ESC_WheelSpeedRC_FL : 391|12@0+ (1,0) [0|4095] "" Vector__XXX
 SG_ ESC_WheelSpeedRC_FR : 395|12@0+ (1,0) [0|4095] "" Vector__XXX
 SG_ ESC_WheelSpeedRC_RL : 415|12@0+ (1,0) [0|4095] "" Vector__XXX
 SG_ ESC_WheelSpeedRC_RR : 419|12@0+ (1,0) [0|4095] "" Vector__XXX
 SG_ ESC_WheelSpeedRCSts_RR : 436|1@0+ (1,0) [0|1] "" Vector__XXX
 SG_ ESC_WheelSpeedRCSts_RL : 437|1@0+ (1,0) [0|1] "" Vector__XXX
 SG_ ESC_WheelSpeedRCSts_FR : 438|1@0+ (1,0) [0|1] "" Vector__XXX
 SG_ ESC_WheelSpeedRCSts_FL : 439|1@0+ (1,0) [0|1] "" Vector__XXX
 SG_ ESC_ABSActiveSta : 448|1@0+ (1,0) [0|1] "" Vector__XXX
 SG_ ESC_ESCorTCSFailed : 449|1@0+ (1,0) [0|1] "" Vector__XXX
 SG_ ESC_EBDFailed : 450|1@0+ (1,0) [0|1] "" Vector__XXX
 SG_ ESC_ABSFailed : 451|1@0+ (1,0) [0|1] "" Vector__XXX
 SG_ ESC_TCSActiveSta : 452|1@0+ (1,0) [0|1] "" Vector__XXX
 SG_ ESC_ESPActiveSta : 453|1@0+ (1,0) [0|1] "" Vector__XXX
 SG_ ESC_VehicleSpeedV : 461|1@0+ (1,0) [0|1] "" Vector__XXX
 SG_ ESC_ReqBrakeLightOn : 463|1@0+ (1,0) [0|1] "" Vector__XXX
 SG_ ESC_VehicleSpeed : 460|13@0+ (0.05625,0) [0|460.6875] "KPH" Vector__XXX
 SG_ ESC_HAZActive : 472|1@0+ (1,0) [0|1] "" Vector__XXX
 SG_ ESC_HBB_Intervention : 473|1@0+ (1,0) [0|1] "" Vector__XXX
 SG_ ESC_HBB_Sts : 475|2@0+ (1,0) [0|3] "" Vector__XXX
 SG_ ESC_AVH_Sts : 477|2@0+ (1,0) [0|3] "" Vector__XXX
 SG_ ESC_BrakePedalSwV : 478|1@0+ (1,0) [0|1] "" Vector__XXX
 SG_ ESC_BrakePedalSwSta : 479|1@0+ (1,0) [0|1] "" Vector__XXX
 SG_ ESC_PALAResponse : 481|2@0+ (1,0) [0|3] "" Vector__XXX
 SG_ ESC_AVH_ICUPrompt : 486|3@0+ (1,0) [0|7] "" Vector__XXX
 SG_ ESC_HHC_ActiveSta : 488|1@0+ (1,0) [0|1] "" Vector__XXX
 SG_ ESC_HHC_FailSta : 489|1@0+ (1,0) [0|1] "" Vector__XXX
 SG_ ESC_HDC_WorkSts : 495|2@0+ (1,0) [0|3] "" Vector__XXX
 SG_ ESC_TrgtGearReqV : 500|1@0+ (1,0) [0|1] "" Vector__XXX
 SG_ ESC_TrgtGearReq : 503|3@0+ (1,0) [0|7] "" Vector__XXX

BO_ 320 IB_A: 64 Vector__XXX
 SG_ IB_PresrRunout : 7|8@0+ (1,0) [0|250] "bar" Vector__XXX
 SG_ IB_StrokeOutputRodDriver : 15|12@0+ (0.015625,-5) [-5|47] "mm" Vector__XXX
 SG_ IB_StrokeOutputRodAct : 19|12@0+ (0.015625,-5) [-5|47] "mm" Vector__XXX
 SG_ IB_PresrRunoutQ : 33|2@0+ (1,0) [0|3] "" Vector__XXX
 SG_ IB_StrokeOutputRodDriverQ : 35|2@0+ (1,0) [0|3] "" Vector__XXX
 SG_ IB_StrokeOutputRodActQ : 37|2@0+ (1,0) [0|3] "" Vector__XXX
 SG_ IB_BrakePedalAppliedQ : 39|2@0+ (1,0) [0|3] ""  FRM,ADC,CRFL,CRFR,CRRL,CRRR,AVP,APA
 SG_ IB_BrakePedalApplied : 40|1@0+ (1,0) [0|1] ""  FRM,ADC,CRFL,CRFR,CRRL,CRRR,AVP,APA
 SG_ IB_ParkPawlRequest : 41|1@0+ (1,0) [0|1] "" Vector__XXX
 SG_ IB_ParkPawlRequestV : 42|1@0+ (1,0) [0|1] "" Vector__XXX
 SG_ IB_HBCRequest : 43|1@0+ (1,0) [0|1] "" Vector__XXX
 SG_ IB_DiagActive : 44|1@0+ (1,0) [0|1] "" Vector__XXX
 SG_ IB_BrakPedalflmodeSelect : 45|1@0+ (1,0) [0|1] "" Vector__XXX
 SG_ IB_A_AliveCnt : 51|4@0+ (1,0) [0|15] ""  FRM,ADC,CRFL,CRFR,CRRL,CRRR,AVP,APA
 SG_ IB_ESCCompatibilityIndex : 55|4@0+ (1,0) [0|15] "" Vector__XXX
 SG_ IB_A_Chksum : 63|8@0+ (1,0) [0|255] ""  FRM,ADC,CRFL,CRFR,CRRL,CRRR,AVP,APA
 SG_ IB_PresrForceBlendingPotential : 71|8@0+ (0.5,0) [0|125] "bar" Vector__XXX
 SG_ IB_PresrForceBlendingPotentialQ : 73|2@0+ (1,0) [0|3] "" Vector__XXX
 SG_ IB_RprMode : 76|3@0+ (1,0) [0|7] "" Vector__XXX
 SG_ IB_ExtReqPrio : 77|1@0+ (1,0) [0|1] "" Vector__XXX
 SG_ IB_ExtReqStatus : 79|2@0+ (1,0) [0|3] "" Vector__XXX
 SG_ IB_HMI_WarningOn : 80|1@0+ (1,0) [0|1] "" Vector__XXX
 SG_ IB_BLA : 81|1@0+ (1,0) [0|1] "" Vector__XXX
 SG_ IB_BrakPedalflmodeSFdbk : 83|2@0+ (1,0) [0|3] "" Vector__XXX
 SG_ IB_VmcActLong2ndAvailable : 85|2@0+ (1,0) [0|3] "" Vector__XXX
 SG_ IB_ESC11_usedChannel : 87|2@0+ (1,0) [0|3] "" Vector__XXX
 SG_ IB_ESC11_BrakeFxCapability : 95|2@0+ (1,0) [0|3] "" Vector__XXX
 SG_ IB_ESC_BrakeFxActual : 93|14@0+ (8,-125000) [-125000|0] "" Vector__XXX
 SG_ IB_ESC11_BrakeFxAvailability : 105|2@0+ (1,0) [0|3] "" Vector__XXX
 SG_ IB_ESC11_DecStabAvail : 107|2@0+ (1,0) [0|3] "" Vector__XXX
 SG_ IB_ESC11_DecStabAvailForDriver : 109|2@0+ (1,0) [0|3] "" Vector__XXX
 SG_ IB_ESC11_DecStabActivity : 111|2@0+ (1,0) [0|3] "" Vector__XXX
 SG_ IB_ESC11_DriveBackup2MainState : 119|4@0+ (1,0) [0|15] "" Vector__XXX
 SG_ IB_ESC11_StopBackup2MainState : 131|4@0+ (1,0) [0|15] "" Vector__XXX
 SG_ IB_ESC11_isBrkFctReqFxBrkDomin : 132|1@0+ (1,0) [0|1] "" Vector__XXX
 SG_ IB_ESC12_DrvReqTarFxBrakeAvail : 134|2@0+ (1,0) [0|3] "" Vector__XXX
 SG_ IB_ESC12_isDrvPressingBrakePedal : 135|1@0+ (1,0) [0|1] "" Vector__XXX
 SG_ IB_ESC12_DrvPressBrakePedalAvail : 143|2@0+ (1,0) [0|3] "" Vector__XXX
 SG_ IB_ESC12_DrvReqTarFxBrake : 141|14@0+ (8,-125000) [-125000|0] "" Vector__XXX
 SG_ IB_ESC12_isDrvReqFxBrakeDominant : 152|1@0+ (1,0) [0|1] "" Vector__XXX
 SG_ IB_ESC13_CompatibilityIndexAD : 156|4@0+ (1,0) [0|15] "" Vector__XXX
 SG_ IB_ESC13_ParkBrakeRequest : 159|3@0+ (1,0) [0|7] "" Vector__XXX
 SG_ IB_ESC13_FxDrvBrake : 167|16@0+ (8,-250000) [-250000|250000] "" Vector__XXX
 SG_ IB_ESC13_FxDrvBrake_Q : 177|2@0+ (1,0) [0|3] "" Vector__XXX
 SG_ IB_ESC12_DrvReqFxBrkDomAvail : 181|2@0+ (1,0) [0|3] "" Vector__XXX
 SG_ IB_ESC11_DecStabCpblty : 193|2@0+ (1,0) [0|3] "" Vector__XXX
 SG_ IB_ESC11_DecStabCpbltyForDrvr : 195|2@0+ (1,0) [0|3] "" Vector__XXX

BO_ 352 ESC_B: 64 Vector__XXX
 SG_ ESC_EPB_ParkLampSta : 1|2@0+ (1,0) [0|3] "" Vector__XXX
 SG_ ESC_EPB_WarnLampSta : 3|2@0+ (1,0) [0|3] "" Vector__XXX
 SG_ ESC_EPB_SwitchSta : 5|2@0+ (1,0) [0|3] "" Vector__XXX
 SG_ ESC_EPB_ActuatorSt_R : 12|3@0+ (1,0) [0|7] "" Vector__XXX
 SG_ ESC_EPB_ActuatorSt_L : 15|3@0+ (1,0) [0|7] "" Vector__XXX
 SG_ ESC_EPB_DynamicApplySta : 22|3@0+ (1,0) [0|7] "" Vector__XXX
 SG_ ESC_EPB_DisplayMsgID : 35|4@0+ (1,0) [0|15] "" Vector__XXX
 SG_ ESC_EPB_SystemState : 39|4@0+ (1,0) [0|15] "" Vector__XXX
 SG_ ESC_IB11_AccStabAvail : 45|2@0+ (1,0) [0|3] "" Vector__XXX
 SG_ ESC_IB11_YawRateStabAvailability : 47|2@0+ (1,0) [0|3] "" Vector__XXX
 SG_ ESC_B_AliveCnt : 51|4@0+ (1,0) [0|15] "" Vector__XXX
 SG_ ESC_IB11_DecStabCpblty : 53|2@0+ (1,0) [0|3] "" Vector__XXX
 SG_ ESC_IB11_DecStabCpbltyForDrvr : 55|2@0+ (1,0) [0|3] "" Vector__XXX
 SG_ ESC_B_Chksum : 63|8@0+ (1,0) [0|255] "" Vector__XXX
 SG_ ESC_PresrEstMax : 71|8@0+ (1,0) [0|250] "bar" Vector__XXX
 SG_ ESC_PresrMCVirtualQ : 83|2@0+ (1,0) [0|3] "" Vector__XXX
 SG_ ESC_ForceBlendingActive : 85|2@0+ (1,0) [0|3] "" Vector__XXX
 SG_ ESC_PresrMCVirtual : 79|10@0+ (0.25,0) [0|250] "bar" Vector__XXX
 SG_ ESC_PresrForceBlendingMC : 81|10@0+ (0.25,0) [0|250] "bar" Vector__XXX
 SG_ ESC_ReqTargetExternal : 103|16@0+ (0.0078125,-252) [-252|252] "ml/s" Vector__XXX
 SG_ ESC_PresrForceBlendingMCQ : 117|2@0+ (1,0) [0|3] "" Vector__XXX
 SG_ ESC_ReqTargetExternalQ : 119|2@0+ (1,0) [0|3] "" Vector__XXX
 SG_ ESC_LSMPosLongACapbl : 129|2@0+ (1,0) [0|3] "" Vector__XXX
 SG_ ESC_LSMSubMTReqAvailable : 130|1@0+ (1,0) [0|1] "" Vector__XXX
 SG_ ESC_LSMSubMTLevelEcho : 132|2@0+ (1,0) [0|3] "" Vector__XXX
 SG_ ESC_LSMSubMTLongEcho : 134|2@0+ (1,0) [0|3] "" Vector__XXX
 SG_ ESC_LSMSubMTReqEcho : 137|2@0+ (1,0) [0|3] "" Vector__XXX
 SG_ ESC_Lsm12ComfortAvl : 139|2@0+ (1,0) [0|3] "" Vector__XXX
 SG_ ESC_Lsm12EmergencyAvl : 141|2@0+ (1,0) [0|3] "" Vector__XXX
 SG_ ESC_Lsm23Avl : 143|2@0+ (1,0) [0|3] "" Vector__XXX
 SG_ ESC_EBDActiveSta : 144|1@0+ (1,0) [0|1] "" Vector__XXX
 SG_ ESC_HBC_ActiveSta : 145|1@0+ (1,0) [0|1] "" Vector__XXX
 SG_ ESC_HBC_Available : 146|1@0+ (1,0) [0|1] "" Vector__XXX
 SG_ ESC_HBAActiveSta : 147|1@0+ (1,0) [0|1] "" Vector__XXX
 SG_ ESC_HBA_Available : 148|1@0+ (1,0) [0|1] "" Vector__XXX
 SG_ ESC_DTC_Available : 149|1@0+ (1,0) [0|1] "" Vector__XXX
 SG_ ESC_CDP_ActiveSta : 150|1@0+ (1,0) [0|1] "" Vector__XXX
 SG_ ESC_CDP_Available : 151|1@0+ (1,0) [0|1] "" Vector__XXX
 SG_ WheelBrakeForce : 159|16@0+ (1,0) [0|30000] "N" Vector__XXX
 SG_ ESC_CMMotionSrvReq : 171|3@0+ (1,0) [0|7] "" Vector__XXX
 SG_ ESC_VmcActLongPrimaryAvailable : 173|2@0+ (1,0) [0|3] "" Vector__XXX
 SG_ ESC_IGNOn : 174|1@0+ (1,0) [0|1] "" Vector__XXX
 SG_ ESC_LSMabortfeedback : 183|4@0+ (1,0) [0|15] "" Vector__XXX
 SG_ ESC_VmcVseYawRateOffset : 199|16@0+ (0.005,-163.84) [-163.84|163.83] "°/s" Vector__XXX
 SG_ ESC_StabilityMarginQualifier : 215|2@0+ (1,0) [0|3] "" Vector__XXX
 SG_ ESC_VmcVseSasOffset : 213|14@0+ (0.1,-780) [-780|780] "°" Vector__XXX
 SG_ ESC_StabilityMargin : 231|16@0+ (6.103515625E-005,0) [0|1] "" Vector__XXX
 SG_ ESC_VmcVseYawRateAvlCpby : 246|3@0+ (1,0) [0|7] "-" Vector__XXX
 SG_ ESC_VmcVseAxOvrGrnd : 263|15@0+ (0.00125,-20) [-20|20] "m/s2" Vector__XXX
 SG_ ESC_VmcVsevVeh : 279|16@0+ (0.01,-100) [-100|400] "kph" Vector__XXX
 SG_ ESC_VmcVseSasAvlCpby : 293|3@0+ (1,0) [0|7] "-" Vector__XXX
 SG_ ESC_VmcVseStandstill : 294|1@0+ (1,0) [0|1] "-" Vector__XXX
 SG_ ESC_VmcVSeSlope : 290|11@0+ (0.1,-90) [-90|90] "°" Vector__XXX
 SG_ ESC_VmcVseLgtPrimSrvAvlCpby : 310|3@0+ (1,0) [0|7] "-" Vector__XXX
 SG_ ESC_IB11_usedChannel : 327|2@0+ (1,0) [0|3] "" Vector__XXX
 SG_ ESC_IB11_BrakeFxActual : 325|14@0+ (8,-125000) [-125000|0] "" Vector__XXX
 SG_ ESC_IB11_BrakeFxCapability : 337|2@0+ (1,0) [0|3] "" Vector__XXX
 SG_ ESC_IB11_BrakeFxAvailability : 339|2@0+ (1,0) [0|3] "" Vector__XXX
 SG_ ESC_IB12_BrkDiscTempStatus : 341|2@0+ (1,0) [0|3] "" Vector__XXX
 SG_ ESC_IB11_DecStabAvail : 343|2@0+ (1,0) [0|3] "" Vector__XXX
 SG_ ESC_IB11_isBrkFctReqFxBrkDomin : 344|1@0+ (1,0) [0|1] "" Vector__XXX
 SG_ ESC_IB11_DecStabAvailForDriver : 347|2@0+ (1,0) [0|3] "" Vector__XXX
 SG_ ESC_IB11_DecStabActivity : 349|2@0+ (1,0) [0|3] "" Vector__XXX
 SG_ ESC_IB11_AccStabActivity : 351|1@0+ (1,0) [0|1] "" Vector__XXX
 SG_ ESC_IB11_YawRateStabActivity : 353|1@0+ (1,0) [0|1] "" Vector__XXX
 SG_ ESC_IB11_ParkBrakeCapability : 355|2@0+ (1,0) [0|3] "" Vector__XXX
 SG_ ESC_IB11_ParkBrakeAvailability : 357|2@0+ (1,0) [0|3] "" Vector__XXX
 SG_ ESC_IB12_BrkDiscTempStatusAvail : 359|2@0+ (1,0) [0|3] "" Vector__XXX
 SG_ ESC_IB11_ParkBrakeState : 362|3@0+ (1,0) [0|7] "" Vector__XXX
 SG_ ESC_IB11_ParkBrakeSupportRequest : 363|1@0+ (1,0) [0|1] "" Vector__XXX
 SG_ ESC_IB11_DriveMain2BackupState : 367|4@0+ (1,0) [0|15] "" Vector__XXX
 SG_ ESC_IB11_StopMain2BackupState : 375|4@0+ (1,0) [0|15] "" Vector__XXX
 SG_ ESC_IB11_isBrkFctReqPrkBrkDomin : 390|1@0+ (1,0) [0|1] "" Vector__XXX
 SG_ ESC_IB12_isDrvPressingBrakePedal : 391|1@0+ (1,0) [0|1] "" Vector__XXX
 SG_ ESC_IB12_DrvReqTarFxBrake : 389|14@0+ (8,-125000) [-125000|0] "" Vector__XXX
 SG_ ESC_IB12_DrvReqTarFxBrakeAvail : 401|2@0+ (1,0) [0|3] "" Vector__XXX
 SG_ ESC_IB12_DrvPressBrakePedalAvail : 403|2@0+ (1,0) [0|3] "" Vector__XXX
 SG_ ESC_IB12_DrvReqFxBrkDomAvail : 405|2@0+ (1,0) [0|3] "" Vector__XXX
 SG_ ESC_IB12_isDrvReqFxBrakeDominant : 406|1@0+ (1,0) [0|1] "" Vector__XXX
 SG_ ESC_IB12_isDrvReqParkBrkDominant : 407|1@0+ (1,0) [0|1] "" Vector__XXX
 SG_ ESC_IB12_DrvReqParkBrakeAvail : 409|2@0+ (1,0) [0|3] "" Vector__XXX
 SG_ ESC_IB12_DriverRequestParkBrake : 411|2@0+ (1,0) [0|3] "" Vector__XXX
 SG_ ESC_VehicleSpeed2IB_Q : 413|2@0+ (1,0) [0|3] "" Vector__XXX
 SG_ ESC_pMC1_Q : 415|2@0+ (1,0) [0|3] "" Vector__XXX
 SG_ ESC_VehicleSpeed2IB : 423|8@0+ (0.39,0) [0|99.45] "m/s" Vector__XXX
 SG_ ESC_IBpMC1 : 431|10@0+ (0.3,-30) [-30|276.6] "bar" Vector__XXX
 SG_ ESC_IBAbsActive : 437|1@0+ (1,0) [0|1] "" Vector__XXX
 SG_ YRS_OriginalYawRate : 455|16@0+ (0.01,-180) [-180|180] "°/s" Vector__XXX
 SG_ YRS_OriginalLateralAcce : 471|12@0+ (0.001,-2) [-2|2] "g" Vector__XXX
 SG_ YRS_OriginalLongitAcce : 475|12@0+ (0.001,-2) [-2|2] "g" Vector__XXX
 SG_ YRS_OriginalLongitSensorState : 489|2@0+ (1,0) [0|3] "" Vector__XXX
 SG_ YRS_OriginalLateralSensorState : 491|2@0+ (1,0) [0|3] "" Vector__XXX
 SG_ YRS_OriginalYawRateSensorState : 493|2@0+ (1,0) [0|3] "" Vector__XXX

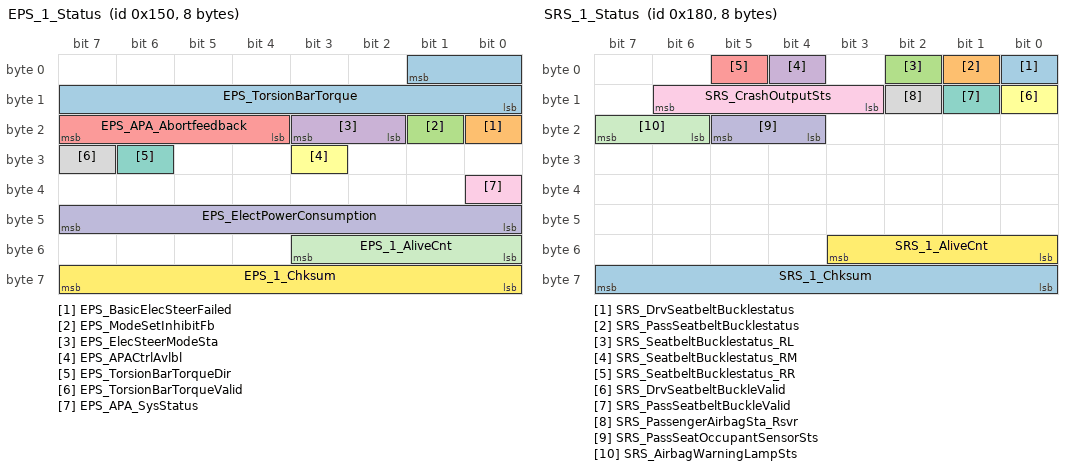
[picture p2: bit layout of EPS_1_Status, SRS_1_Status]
BO_ 336 EPS_1_Status: 8 Vector__XXX
 SG_ EPS_TorsionBarTorque : 1|10@0+ (0.01,0) [0|8] "Nm" Vector__XXX
 SG_ EPS_BasicElecSteerFailed : 16|1@0+ (1,0) [0|1] "" Vector__XXX
 SG_ EPS_ModeSetInhibitFb : 17|1@0+ (1,0) [0|1] "" Vector__XXX
 SG_ EPS_ElecSteerModeSta : 19|2@0+ (1,0) [0|3] "" Vector__XXX
 SG_ EPS_APA_Abortfeedback : 23|4@0+ (1,0) [0|15] "" Vector__XXX
 SG_ EPS_APACtrlAvlbl : 27|1@0+ (1,0) [0|1] "" Vector__XXX
 SG_ EPS_TorsionBarTorqueDir : 30|1@0+ (1,0) [0|1] "" Vector__XXX
 SG_ EPS_TorsionBarTorqueValid : 31|1@0+ (1,0) [0|1] "" Vector__XXX
 SG_ EPS_APA_SysStatus : 32|1@0+ (1,0) [0|1] "" Vector__XXX
 SG_ EPS_ElectPowerConsumption : 47|8@0+ (0.5,0) [0|127] "Amp" Vector__XXX
 SG_ EPS_1_AliveCnt : 51|4@0+ (1,0) [0|15] "" Vector__XXX
 SG_ EPS_1_Chksum : 63|8@0+ (1,0) [0|255] "" Vector__XXX

BO_ 384 SRS_1_Status: 8 Vector__XXX
 SG_ SRS_DrvSeatbeltBucklestatus : 0|1@0+ (1,0) [0|1] "" Vector__XXX
 SG_ SRS_PassSeatbeltBucklestatus : 1|1@0+ (1,0) [0|1] "" Vector__XXX
 SG_ SRS_SeatbeltBucklestatus_RL : 2|1@0+ (1,0) [0|1] "" Vector__XXX
 SG_ SRS_SeatbeltBucklestatus_RM : 4|1@0+ (1,0) [0|1] "" Vector__XXX
 SG_ SRS_SeatbeltBucklestatus_RR : 5|1@0+ (1,0) [0|1] "" Vector__XXX
 SG_ SRS_DrvSeatbeltBuckleValid : 8|1@0+ (1,0) [0|1] "" Vector__XXX
 SG_ SRS_PassSeatbeltBuckleValid : 9|1@0+ (1,0) [0|1] "" Vector__XXX
 SG_ SRS_PassengerAirbagSta_Rsvr : 10|1@0+ (1,0) [0|1] "" Vector__XXX
 SG_ SRS_CrashOutputSts : 14|4@0+ (1,0) [0|7] "" Vector__XXX
 SG_ SRS_PassSeatOccupantSensorSts : 21|2@0+ (1,0) [0|3] "" Vector__XXX
 SG_ SRS_AirbagWarningLampSts : 23|2@0+ (1,0) [0|3] "" Vector__XXX
 SG_ SRS_1_AliveCnt : 51|4@0+ (1,0) [0|15] "" Vector__XXX
 SG_ SRS_1_Chksum : 63|8@0+ (1,0) [0|255] "" Vector__XXX

BO_ 403 CRRR_A: 64 Vector__XXX
 SG_ CRRR_BSD_SetFb : 0|1@0+ (1,0) [0|1] "" Vector__XXX
 SG_ CRRR_BSD_Warn_Right : 2|2@0+ (1,0) [0|3] "" Vector__XXX
 SG_ CRRR_BSD_Warn_Left : 4|2@0+ (1,0) [0|3] "" Vector__XXX
 SG_ CRRR_RCTA_Warn_Right : 6|2@0+ (1,0) [0|3] "" Vector__XXX
 SG_ CRRR_RCTA_SetFb : 7|1@0+ (1,0) [0|1] "" Vector__XXX
 SG_ CRRR_RCTA_Warn_Left : 9|2@0+ (1,0) [0|3] "" Vector__XXX
 SG_ CRRR_DOW_Warn_Right : 13|2@0+ (1,0) [0|3] "" Vector__XXX
 SG_ CRRR_RCW_Warning : 15|2@0+ (1,0) [0|3] "" Vector__XXX
 SG_ CRRR_RCTBDecelaration : 23|8@0+ (0.05,-10) [-10|2.75] "m/s2" Vector__XXX
 SG_ CRRR_DOWSetFb : 24|1@0+ (1,0) [0|1] "" Vector__XXX
 SG_ CRRR_RCTBReq : 25|1@0+ (1,0) [0|1] "" Vector__XXX
 SG_ CRRR_RCTB_BrkgVld : 26|1@0+ (1,0) [0|1] "" Vector__XXX
 SG_ CRRR_RCW_SetFb : 27|1@0+ (1,0) [0|1] "" Vector__XXX
 SG_ CRRR_DOW_Warn_Left : 29|2@0+ (1,0) [0|3] "" Vector__XXX
 SG_ CRRR_RearCornerFailure : 31|2@0+ (1,0) [0|3] "" Vector__XXX
 SG_ CRRR_RearCornerBlindness : 39|2@0+ (1,0) [0|3] "" Vector__XXX
 SG_ CRRR_FOVChangeSetFb : 41|2@0+ (1,0) [0|3] "" Vector__XXX
 SG_ CRRR_A_AliveCnt : 51|4@0+ (1,0) [0|15] "" Vector__XXX
 SG_ CRRR_A_Chksum : 63|8@0+ (1,0) [0|255] "" Vector__XXX
 SG_ CRRR_ObjDirY_Left_00 : 71|8@0+ (0.1,-7.5) [-7.5|7.5] "m" Vector__XXX
 SG_ CRRR_ObjDirX_Left_00 : 79|8@0+ (0.4,-5) [-5|50.2] "m" Vector__XXX
 SG_ CRRR_ObjDirY_Left_01 : 87|8@0+ (0.1,-7.5) [-7.5|7.5] "m" Vector__XXX
 SG_ CRRR_ObjDirX_Left_01 : 95|8@0+ (0.4,-5) [-5|50.2] "m" Vector__XXX
 SG_ CRRR_ObjDirY_Right_00 : 103|8@0+ (0.1,-7.5) [-7.5|7.5] "m" Vector__XXX
 SG_ CRRR_ObjDirX_Right_00 : 111|8@0+ (0.4,-5) [-5|50.2] "m" Vector__XXX
 SG_ CRRR_ObjDirY_Right_01 : 135|8@0+ (0.1,-7.5) [-7.5|7.5] "m" Vector__XXX
 SG_ CRRR_ObjDirX_Right_01 : 143|8@0+ (0.4,-5) [-5|50.2] "m" Vector__XXX
 SG_ CRRR_ObjDirY_Rear_00 : 151|8@0+ (0.1,-7.5) [-7.5|7.5] "m" Vector__XXX
 SG_ CRRR_ObjDirX_Rear_00 : 159|8@0+ (0.4,-5) [-5|50.2] "m" Vector__XXX
 SG_ CRRR_ObjDirY_Rear_01 : 167|8@0+ (0.1,-7.5) [-7.5|7.5] "m" Vector__XXX
 SG_ CRRR_ObjDirX_Rear_01 : 175|8@0+ (0.4,-5) [-5|50.2] "m" Vector__XXX

BO_ 404 CRFR_A: 64 Vector__XXX
 SG_ CRFR_FCTB_AEBReqRight : 2|1@0+ (1,0) [0|1] "" Vector__XXX
 SG_ CRFR_FCTB_EBAReqRight : 3|1@0+ (1,0) [0|1] "" Vector__XXX
 SG_ CRFR_FCTB_ABALevelRight : 6|3@0+ (1,0) [0|7] "" Vector__XXX
 SG_ CRFR_FCTB_ABAReqRight : 7|1@0+ (1,0) [0|1] "" Vector__XXX
 SG_ CRFR_FCTB_AEBTgtAxRight : 1|10@0+ (0.05,-16) [-16|16] "m/s2" Vector__XXX
 SG_ CRFR_FCTB_ABPReqRight : 16|1@0+ (1,0) [0|1] "" Vector__XXX
 SG_ CRFR_FCTA_SetFb : 17|1@0+ (1,0) [0|1] "" Vector__XXX
 SG_ CRFR_FrontCornerFailure : 19|2@0+ (1,0) [0|3] "" Vector__XXX
 SG_ CRFR_FrontCornerBlindness : 21|2@0+ (1,0) [0|3] "" Vector__XXX
 SG_ CRFR_FCTA_Warn_Left : 24|1@0+ (1,0) [0|1] "" Vector__XXX
 SG_ CRFR_FCTA_Warn_Right : 27|1@0+ (1,0) [0|1] "" Vector__XXX
 SG_ CRFR_A_AliveCnt : 51|4@0+ (1,0) [0|15] "" Vector__XXX
 SG_ CRFR_A_Chksum : 63|8@0+ (1,0) [0|255] "" Vector__XXX
 SG_ CRFR_ObjDirY_Left_00 : 71|8@0+ (0.1,-7.5) [-7.5|7.5] "m" Vector__XXX
 SG_ CRFR_ObjDirX_Left_00 : 79|8@0+ (0.4,-5) [-5|50.2] "m" Vector__XXX
 SG_ CRFR_ObjDirY_Left_01 : 87|8@0+ (0.1,-7.5) [-7.5|7.5] "m" Vector__XXX
 SG_ CRFR_ObjDirX_Left_01 : 95|8@0+ (0.4,-5) [-5|50.2] "m" Vector__XXX
 SG_ CRFR_ObjDirY_Right_00 : 103|8@0+ (0.1,-7.5) [-7.5|7.5] "m" Vector__XXX
 SG_ CRFR_ObjDirX_Right_00 : 111|8@0+ (0.4,-5) [-5|50.2] "m" Vector__XXX
 SG_ CRFR_ObjDirY_Right_01 : 135|8@0+ (0.1,-7.5) [-7.5|7.5] "m" Vector__XXX
 SG_ CRFR_ObjDirX_Right_01 : 143|8@0+ (0.4,-5) [-5|50.2] "m" Vector__XXX
 SG_ CRFR_ObjDirY_Front_00 : 151|8@0+ (0.1,-7.5) [-7.5|7.5] "m" Vector__XXX
 SG_ CRFR_ObjDirX_Front_00 : 159|8@0+ (0.4,-5) [-5|50.2] "m" Vector__XXX
 SG_ CRFR_ObjDirY_Front_01 : 167|8@0+ (0.1,-7.5) [-7.5|7.5] "m" Vector__XXX
 SG_ CRFR_ObjDirX_Front_01 : 175|8@0+ (0.4,-5) [-5|50.2] "m" Vector__XXX

BO_ 416 FRM_A: 64 Vector__XXX
 SG_ FRM_A_AliveCnt : 51|4@0+ (1,0) [0|15] "" Vector__XXX
 SG_ FRM_A_Chksum : 63|8@0+ (1,0) [0|255] "" Vector__XXX
 SG_ FRM_AEB_Req : 333|1@0+ (1,0) [0|1] "" Vector__XXX
 SG_ FRM_AEB_TgtAx : 327|10@0+ (0.05,-16) [-16|16] "m/s2" Vector__XXX
 SG_ FRM_ABP_Req : 340|1@0+ (1,0) [0|1] "" Vector__XXX

BO_ 425 FRM_B: 64 Vector__XXX
 SG_ FRM_B_AliveCnt : 51|4@0+ (1,0) [0|15] "" Vector__XXX
 SG_ FRM_B_Chksum : 63|8@0+ (1,0) [0|255] "" Vector__XXX

BO_ 373 FCM_A: 64 Vector__XXX
 SG_ FCM_A_AliveCnt : 51|4@0+ (1,0) [0|15] "" Vector__XXX
 SG_ FCM_A_Chksum : 63|8@0+ (1,0) [0|255] "" Vector__XXX

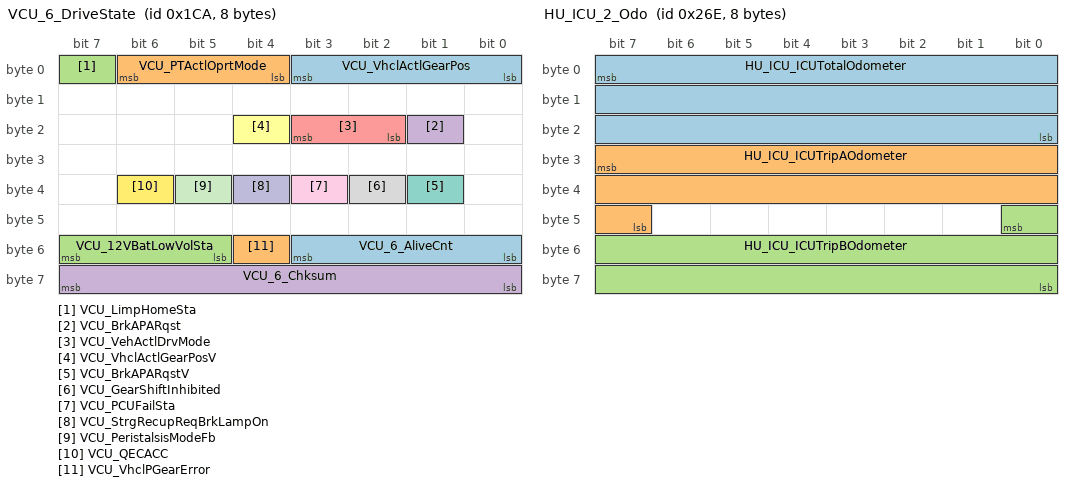
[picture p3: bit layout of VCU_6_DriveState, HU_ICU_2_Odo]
BO_ 458 VCU_6_DriveState: 8 Vector__XXX
 SG_ VCU_VhclActlGearPos : 3|4@0+ (1,0) [0|15] "" Vector__XXX
 SG_ VCU_PTActlOprtMode : 6|3@0+ (1,0) [0|7] "" Vector__XXX
 SG_ VCU_LimpHomeSta : 7|1@0+ (1,0) [0|1] "" Vector__XXX
 SG_ VCU_BrkAPARqst : 17|1@0+ (1,0) [0|1] "" Vector__XXX
 SG_ VCU_VehActlDrvMode : 19|2@0+ (1,0) [0|3] "" Vector__XXX
 SG_ VCU_VhclActlGearPosV : 20|1@0+ (1,0) [0|1] "" Vector__XXX
 SG_ VCU_BrkAPARqstV : 33|1@0+ (1,0) [0|1] "" Vector__XXX
 SG_ VCU_GearShiftInhibited : 34|1@0+ (1,0) [0|1] "" Vector__XXX
 SG_ VCU_PCUFailSta : 35|1@0+ (1,0) [0|1] "" Vector__XXX
 SG_ VCU_StrgRecupReqBrkLampOn : 36|1@0+ (1,0) [0|1] "" Vector__XXX
 SG_ VCU_PeristalsisModeFb : 37|1@0+ (1,0) [0|1] "" Vector__XXX
 SG_ VCU_QECACC : 38|1@0+ (1,0) [0|1] "" Vector__XXX
 SG_ VCU_6_AliveCnt : 51|4@0+ (1,0) [0|15] "" Vector__XXX
 SG_ VCU_VhclPGearError : 52|1@0+ (1,0) [0|1] "" Vector__XXX
 SG_ VCU_12VBatLowVolSta : 55|3@0+ (1,0) [0|3] "" Vector__XXX
 SG_ VCU_6_Chksum : 63|8@0+ (1,0) [0|255] "" Vector__XXX

BO_ 565 BCM_1_Lamp_Ajar_Lock: 8 Vector__XXX
 SG_ BCM_TurnLampSta_Left : 0|1@0+ (1,0) [0|1] "" Vector__XXX
 SG_ BCM_TurnLampSta_Right : 1|1@0+ (1,0) [0|1] "" Vector__XXX
 SG_ BCM_FogLampSta_Rear : 2|1@0+ (1,0) [0|1] "" Vector__XXX
 SG_ BCM_PosLampSta_Left : 3|1@0+ (1,0) [0|1] "" Vector__XXX
 SG_ BCM_PosLampSta_Right : 4|1@0+ (1,0) [0|1] "" Vector__XXX
 SG_ BCM_AjarSta_Hood : 5|1@0+ (1,0) [0|1] "" Vector__XXX
 SG_ BCM_AjarSta_Trunk : 6|1@0+ (1,0) [0|1] "" Vector__XXX
 SG_ BCM_DoorAjarSta_FL : 7|1@0+ (1,0) [0|1] "" Vector__XXX
 SG_ BCM_DoorAjarSta_FR : 8|1@0+ (1,0) [0|1] "" Vector__XXX
 SG_ BCM_DoorAjarSta_RL : 9|1@0+ (1,0) [0|1] "" Vector__XXX
 SG_ BCM_DoorAjarSta_RR : 10|1@0+ (1,0) [0|1] "" Vector__XXX
 SG_ BCM_ChrgAjarSta_Fast : 11|1@0+ (1,0) [0|1] "" Vector__XXX
 SG_ BCM_ChrgAjarSta_Slow : 12|1@0+ (1,0) [0|1] "" Vector__XXX
 SG_ BCM_FuelAjarSta_Reserved : 13|1@0+ (1,0) [0|1] "" Vector__XXX
 SG_ BCM_DoorsLockLatchOverHeat : 14|1@0+ (1,0) [0|1] "" Vector__XXX
 SG_ BCM_LightLeftOnRemind : 15|1@0+ (1,0) [0|1] "" Vector__XXX
 SG_ BCM_ATWSLightOnReq_PT : 16|1@0+ (1,0) [0|1] "" Vector__XXX
 SG_ BCM_ChildLockSta_RL : 17|1@0+ (1,0) [0|1] "" Vector__XXX
 SG_ BCM_DoorLockSta_FL : 18|1@0+ (1,0) [0|1] "" Vector__XXX
 SG_ BCM_DoorLockSta_FR_RL_RR : 19|1@0+ (1,0) [0|1] "" Vector__XXX
 SG_ BCM_AjarStaV_Hood : 20|1@0+ (1,0) [0|1] "" Vector__XXX
 SG_ BCM_HazardLampSts : 21|1@0+ (1,0) [0|1] "" Vector__XXX
 SG_ BCM_TrunkSwSts_Drv : 22|1@0+ (1,0) [0|1] "" Vector__XXX
 SG_ BCM_HighBeamSta : 23|1@0+ (1,0) [0|1] "" Vector__XXX
 SG_ BCM_LowBeamSta : 24|1@0+ (1,0) [0|1] "" Vector__XXX
 SG_ BCM_AutoLampStatus : 25|1@0+ (1,0) [0|1] "" Vector__XXX
 SG_ BCM_FogLampSta_Front : 26|1@0+ (1,0) [0|1] "" Vector__XXX
 SG_ BCM_TopLampModeFb : 27|1@0+ (1,0) [0|1] "" Vector__XXX
 SG_ BCM_DayRunLightReq : 28|1@0+ (1,0) [0|1] "" Vector__XXX
 SG_ BCM_BrakeLampSta : 29|1@0+ (1,0) [0|1] "" Vector__XXX
 SG_ BCM_ReverseLampSta : 30|1@0+ (1,0) [0|1] "" Vector__XXX
 SG_ BCM_NozzleHeatSta : 31|1@0+ (1,0) [0|1] "" Vector__XXX
 SG_ BCM_ChildLockSta_RR : 32|1@0+ (1,0) [0|1] "" Vector__XXX
 SG_ BCM_PDU_Forbidden : 33|1@0+ (1,0) [0|1] "" Vector__XXX
 SG_ BCM_BeamLampOpenWarn : 34|1@0+ (1,0) [0|1] "" Vector__XXX
 SG_ BCM_BrakePadelSta : 35|1@0+ (1,0) [0|1] "" Vector__XXX
 SG_ BCM_FuelLidSts : 37|2@0+ (1,0) [0|3] "" Vector__XXX
 SG_ BCM_SSBSwSta : 38|1@0+ (1,0) [0|1] "" Vector__XXX
 SG_ BCM_KeyInCarSta : 39|1@0+ (1,0) [0|1] "" Vector__XXX
 SG_ BCM_BodyWarnSts : 41|2@0+ (1,0) [0|3] "" Vector__XXX
 SG_ BCM_WiperCtrl_Rear : 43|2@0+ (1,0) [0|3] "" Vector__XXX
 SG_ BCM_HeavyRainInd : 44|1@0+ (1,0) [0|1] "" Vector__XXX
 SG_ BCM_WiperCtrl_Front : 47|3@0+ (1,0) [0|7] "" Vector__XXX
 SG_ BCM_1_AliveCnt : 51|4@0+ (1,0) [0|15] "" Vector__XXX
 SG_ BCM_PTGUnlockCmd : 55|4@0+ (1,0) [0|15] "" Vector__XXX
 SG_ BCM_1_Chksum : 63|8@0+ (1,0) [0|255] "" Vector__XXX

BO_ 601 SCM_2_SwSta: 8 Vector__XXX
 SG_ SCM_AutoLightSW_StsInvalid : 0|1@0+ (1,0) [0|1] "" Vector__XXX
 SG_ SCM_AutoLightSW_Sts : 1|1@0+ (1,0) [0|1] "" Vector__XXX
 SG_ SCM_FrontWasherSW_StsInvalid : 2|1@0+ (1,0) [0|1] "" Vector__XXX
 SG_ SCM_FrontWasherSW_Sts : 3|1@0+ (1,0) [0|1] "" Vector__XXX
 SG_ SCM_LowBeamSW_StsInvalid : 4|1@0+ (1,0) [0|1] "" Vector__XXX
 SG_ SCM_LowBeamSW_Sts : 5|1@0+ (1,0) [0|1] "" Vector__XXX
 SG_ SCM_HighBeamSW_StsInvalid : 6|1@0+ (1,0) [0|1] "" Vector__XXX
 SG_ SCM_HighBeamSW_Sts : 7|1@0+ (1,0) [0|1] "" Vector__XXX
 SG_ SCM_PositionLightSW_StsInvalid : 12|1@0+ (1,0) [0|1] "" Vector__XXX
 SG_ SCM_PositionLightSW_Sts : 13|1@0+ (1,0) [0|1] "" Vector__XXX
 SG_ SCM_FlashLightSW_StsInvalid : 14|1@0+ (1,0) [0|1] "" Vector__XXX
 SG_ SCM_FlashLightSW_Sts : 15|1@0+ (1,0) [0|1] "" Vector__XXX
 SG_ SCM_TurnLightLeverSta : 17|2@0+ (1,0) [0|3] "" Vector__XXX
 SG_ SCM_TripSW_Sts : 19|2@0+ (1,0) [0|3] "" Vector__XXX
 SG_ SCM_RearFogLightSW_StsInvalid : 20|1@0+ (1,0) [0|1] "" Vector__XXX
 SG_ SCM_RearFogLightSW_Sts : 21|1@0+ (1,0) [0|1] "" Vector__XXX
 SG_ SCM_FrontFogLightSW_StsInvalid : 22|1@0+ (1,0) [0|1] "" Vector__XXX
 SG_ SCM_FrontFogLightSW_Sts : 23|1@0+ (1,0) [0|1] "" Vector__XXX
 SG_ SCM_RearWasherSwStsV : 24|1@0+ (1,0) [0|1] "" Vector__XXX
 SG_ SCM_RearWasherSwSts : 25|1@0+ (1,0) [0|1] "" Vector__XXX
 SG_ SCM_FrontWipingIntervalSW_Sts : 28|3@0+ (1,0) [0|7] "" Vector__XXX
 SG_ SCM_FrontWipingMode : 31|3@0+ (1,0) [0|7] "" Vector__XXX
 SG_ SCM_RearWipingMode : 38|2@0+ (1,0) [0|3] "" Vector__XXX
 SG_ SCM_2_AliveCnt : 51|4@0+ (1,0) [0|15] "" Vector__XXX
 SG_ SCM_2_Chksum : 63|8@0+ (1,0) [0|255] "" Vector__XXX

BO_ 622 HU_ICU_2_Odo: 8 Vector__XXX
 SG_ HU_ICU_ICUTotalOdometer : 7|24@0+ (0.1,0) [0|1670000] "KM" Vector__XXX
 SG_ HU_ICU_ICUTripAOdometer : 31|17@0+ (0.1,0) [0|9999.9] "KM" Vector__XXX
 SG_ HU_ICU_ICUTripBOdometer : 40|17@0+ (0.1,0) [0|9999.9] "KM" Vector__XXX

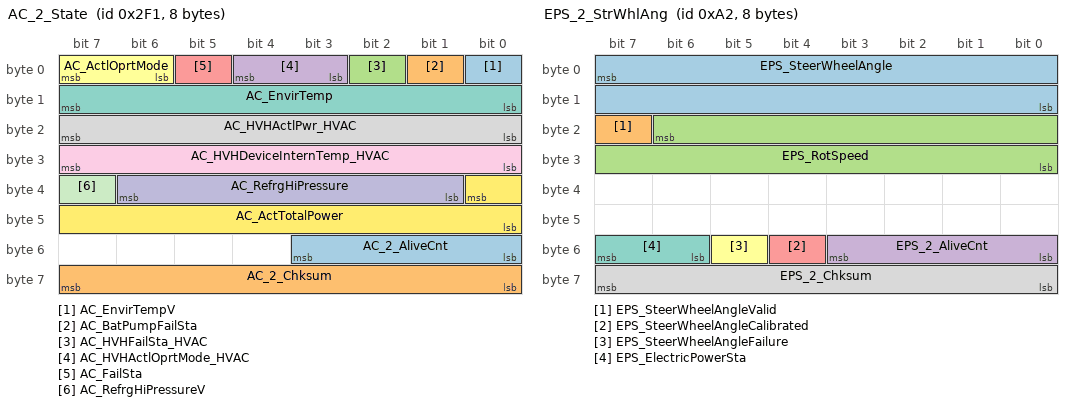
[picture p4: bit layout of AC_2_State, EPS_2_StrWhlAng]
BO_ 753 AC_2_State: 8 Vector__XXX
 SG_ AC_EnvirTempV : 0|1@0+ (1,0) [0|1] "" Vector__XXX
 SG_ AC_BatPumpFailSta : 1|1@0+ (1,0) [0|1] "" Vector__XXX
 SG_ AC_HVHFailSta_HVAC : 2|1@0+ (1,0) [0|1] "" Vector__XXX
 SG_ AC_HVHActlOprtMode_HVAC : 4|2@0+ (1,0) [0|3] "" Vector__XXX
 SG_ AC_FailSta : 5|1@0+ (1,0) [0|1] "" Vector__XXX
 SG_ AC_ActlOprtMode : 7|2@0+ (1,0) [0|3] "" Vector__XXX
 SG_ AC_EnvirTemp : 15|8@0+ (0.5,-40) [-40|87.5] "℃" Vector__XXX
 SG_ AC_HVHActlPwr_HVAC : 23|8@0+ (0.04,0) [0|10.2] "KW" Vector__XXX
 SG_ AC_HVHDeviceInternTemp_HVAC : 31|8@0+ (1,-40) [-40|215] "℃" Vector__XXX
 SG_ AC_RefrgHiPressure : 38|6@0+ (100,0) [0|6300] "kpa" Vector__XXX
 SG_ AC_RefrgHiPressureV : 39|1@0+ (1,0) [0|1] "" Vector__XXX
 SG_ AC_ActTotalPower : 32|9@0+ (0.04,0) [0|20.44] "KW" Vector__XXX
 SG_ AC_2_AliveCnt : 51|4@0+ (1,0) [0|15] "" Vector__XXX
 SG_ AC_2_Chksum : 63|8@0+ (1,0) [0|255] "" Vector__XXX

BO_ 162 EPS_2_StrWhlAng: 8 Vector__XXX
 SG_ EPS_SteerWheelAngle : 7|16@0- (0.1,0) [-780|779.9] "" Vector__XXX
 SG_ EPS_SteerWheelAngleValid : 23|1@0+ (1,0) [0|1] "" Vector__XXX
 SG_ EPS_RotSpeed : 22|15@0+ (0.1,-1024) [-1024|1024] "Deg/sec" Vector__XXX
 SG_ EPS_2_AliveCnt : 51|4@0+ (1,0) [0|15] "" Vector__XXX
 SG_ EPS_SteerWheelAngleCalibrated : 52|1@0+ (1,0) [0|1] "" Vector__XXX
 SG_ EPS_SteerWheelAngleFailure : 53|1@0+ (1,0) [0|1] "" Vector__XXX
 SG_ EPS_ElectricPowerSta : 55|2@0+ (1,0) [0|3] "" Vector__XXX
 SG_ EPS_2_Chksum : 63|8@0+ (1,0) [0|255] "" Vector__XXX

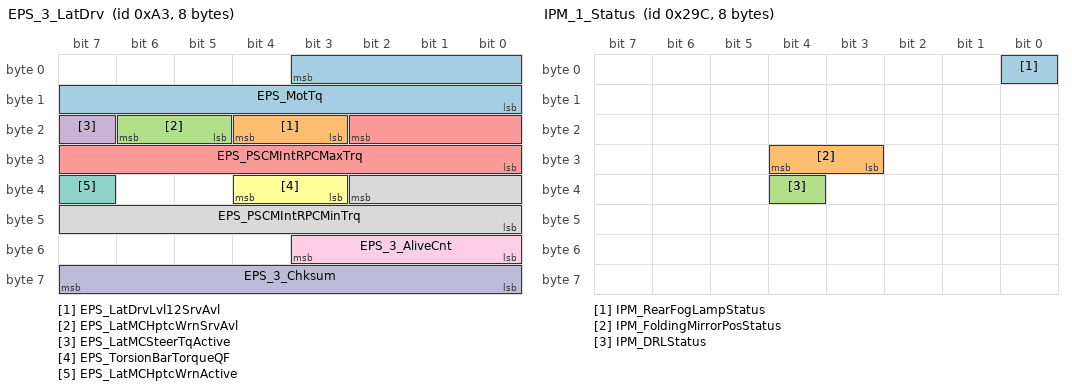
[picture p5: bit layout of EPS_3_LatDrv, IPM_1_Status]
BO_ 163 EPS_3_LatDrv: 8 Vector__XXX
 SG_ EPS_MotTq : 3|12@0+ (0.02,-20.48) [-20.48|20.44] "" Vector__XXX
 SG_ EPS_LatDrvLvl12SrvAvl : 20|2@0+ (1,0) [0|3] "" Vector__XXX
 SG_ EPS_LatMCHptcWrnSrvAvl : 22|2@0+ (1,0) [0|3] "" Vector__XXX
 SG_ EPS_LatMCSteerTqActive : 23|1@0+ (1,0) [0|1] "" Vector__XXX
 SG_ EPS_PSCMIntRPCMaxTrq : 18|11@0+ (0.02,-20.48) [-20.48|20.44] "" Vector__XXX
 SG_ EPS_TorsionBarTorqueQF : 36|2@0+ (1,0) [0|3] "" Vector__XXX
 SG_ EPS_LatMCHptcWrnActive : 39|1@0+ (1,0) [0|1] "" Vector__XXX
 SG_ EPS_PSCMIntRPCMinTrq : 34|11@0+ (0.02,-20.48) [-20.48|20.44] "" Vector__XXX
 SG_ EPS_3_AliveCnt : 51|4@0+ (1,0) [0|15] "" Vector__XXX
 SG_ EPS_3_Chksum : 63|8@0+ (1,0) [0|255] "" Vector__XXX

BO_ 668 IPM_1_Status: 8 Vector__XXX
 SG_ IPM_RearFogLampStatus : 0|1@0+ (1,0) [0|1] "" Vector__XXX
 SG_ IPM_FoldingMirrorPosStatus : 28|2@0+ (1,0) [0|3] "" Vector__XXX
 SG_ IPM_DRLStatus : 36|1@0+ (1,0) [0|1] "" Vector__XXX

BO_ 389 APA_A: 64 Vector__XXX
 SG_ APA_SafeDrvrHandoverReq : 301|1@0+ (1,0) [0|1] "" Vector__XXX
 SG_ APA_A_AliveCnt : 51|4@0+ (1,0) [0|15] "" Vector__XXX
 SG_ APA_A_Chksum : 63|8@0+ (1,0) [0|255] "" Vector__XXX
 SG_ APA_ReqReleaseEPB : 224|1@0+ (1,0) [0|1] "" Vector__XXX
 SG_ APA_ReqReleaseEPBV : 225|1@0+ (1,0) [0|1] "" Vector__XXX
 SG_ APA_LSMSubMTReq : 257|2@0+ (1,0) [0|3] "" Vector__XXX
 SG_ APA_LSMSubMTLevel : 259|2@0+ (1,0) [0|3] "" Vector__XXX
 SG_ APA_LSMSubMTLong : 261|2@0+ (1,0) [0|3] "" Vector__XXX
 SG_ APA_LSMBrakeEmgcyPrep : 262|1@0+ (1,0) [0|1] "" Vector__XXX
 SG_ APA_DrvPresenceExt : 293|1@0+ (1,0) [0|1] "" Vector__XXX
 SG_ APA_LSMComfBrakeReq : 295|2@0+ (1,0) [0|3] "" Vector__XXX
 SG_ APA_EPS_SetSteeringWheelAng : 327|16@0- (0.1,0) [-780|779.9] "deg" Vector__XXX
 SG_ APA_DrvReq : 340|5@0+ (1,0) [0|31] "" Vector__XXX
 SG_ APA_RPA_status : 341|1@0+ (1,0) [0|1] "" Vector__XXX
 SG_ APA_EPS_Control_Request : 343|2@0+ (1,0) [0|3] "" Vector__XXX
 SG_ APA_Status : 354|3@0+ (1,0) [0|7] "" Vector__XXX
 SG_ APA_RPA_AvailSts : 359|1@0+ (1,0) [0|1] "" Vector__XXX

BO_ 480 APA_B: 64 Vector__XXX
 SG_ APA_B_AliveCnt : 51|4@0+ (1,0) [0|15] "" Vector__XXX
 SG_ APA_B_Chksum : 63|8@0+ (1,0) [0|255] "" Vector__XXX

BO_ 448 ADC_A: 64 Vector__XXX
 SG_ ADC_TextInfoACCTJA : 195|4@0+ (1,0) [0|15] "" Vector__XXX
 SG_ ADC_A_AliveCnt : 51|4@0+ (1,0) [0|15] "" Vector__XXX
 SG_ ADC_A_Chksum : 63|8@0+ (1,0) [0|255] "" Vector__XXX
 SG_ ADC_Acc_MotorTorqReqValue : 75|12@0+ (0.5,-1000) [-1000|1000] "Nm" Vector__XXX
 SG_ ADC_AccTrqReqEna : 88|1@0+ (1,0) [0|1] "" Vector__XXX
 SG_ ADC_Acc_TgtAxReq : 92|1@0+ (1,0) [0|1] "" Vector__XXX
 SG_ ADC_Acc_Mode : 95|3@0+ (1,0) [0|7] "" Vector__XXX
 SG_ ADC_Acc_TgtAx : 103|8@0+ (0.05,-5) [-5|7.75] "m/s2" Vector__XXX
 SG_ ADC_AccReq_DriveOff : 110|1@0+ (1,0) [0|1] "" Vector__XXX
 SG_ ADC_AccReq_Standstill : 111|1@0+ (1,0) [0|1] "" Vector__XXX
 SG_ ADC_SteerTqReq : 135|12@0+ (0.01,-20.48) [-20.48|20.44] "Nm" Vector__XXX
 SG_ ADC_SteerTqReqActive : 145|2@0+ (1,0) [0|3] "" Vector__XXX
 SG_ ADC_ActDrvAsstSts : 154|3@0+ (1,0) [0|7] "" Vector__XXX
 SG_ ADC_DA_EPSModeReq : 182|1@0+ (1,0) [0|1] "" Vector__XXX

BO_ 309 ADC_D: 64 Vector__XXX
 SG_ ADC_D_AliveCnt1 : 51|4@0+ (1,0) [0|15] "" Vector__XXX
 SG_ ADC_D_Chksum1 : 63|8@0+ (1,0) [0|255] "" Vector__XXX

CM_ SG_ 3221225472 CRRL_KeepAwakePwrMode "保持唤醒原因1:电源模式";
CM_ SG_ 3221225472 CRRL_KeepAwakeReasDiag "保持唤醒原因2:诊断进行中";
CM_ SG_ 3221225472 CRRL_KeepAwakeReasLocalFunReq "保持唤醒原因3：控制器本地功能请求";
CM_ SG_ 3221225472 CRRL_KeepAwakeSta "保持唤醒状态位";
CM_ SG_ 3221225472 CRRR_WakeupReas "唤醒原因";
CM_ SG_ 3221225472 CRRR_KeepAwakePwrMode "保持唤醒原因1:电源模式";
CM_ SG_ 3221225472 CRRR_KeepAwakeReasDiag "保持唤醒原因2:诊断进行中";
CM_ SG_ 3221225472 CRRR_KeepAwakeReasLocalFunReq "保持唤醒原因3：控制器本地功能请求";
CM_ SG_ 3221225472 CRRR_KeepAwakeSta "保持唤醒状态位";
CM_ SG_ 3221225472 AVP_WakeupReas "唤醒原因";
CM_ SG_ 3221225472 AVP_KeepAwakePwrMode "保持唤醒原因1:电源模式";
CM_ SG_ 3221225472 AVP_KeepAwakeReasDiag "保持唤醒原因2:诊断进行中";
CM_ SG_ 3221225472 AVP_KeepAwakeReasLocalFunReq "保持唤醒原因3：控制器本地功能请求";
CM_ SG_ 3221225472 AVP_KeepAwakeSta "保持唤醒状态位";
CM_ SG_ 3221225472 Diag_PhyReq_FRM_Data0 "Diagnostic Physical Request Data to FRM";
CM_ SG_ 3221225472 Diag_PhyReq_FRM_Data1 "Diagnostic Physical Request Data to FRM";
CM_ SG_ 3221225472 Diag_PhyReq_FRM_Data2 "Diagnostic Physical Request Data to FRM";
CM_ SG_ 3221225472 Diag_PhyReq_FRM_Data3 "Diagnostic Physical Request Data to FRM";
CM_ SG_ 3221225472 Diag_PhyReq_FRM_Data4 "Diagnostic Physical Request Data to FRM";
CM_ SG_ 3221225472 Diag_PhyReq_FRM_Data5 "Diagnostic Physical Request Data to FRM";
CM_ SG_ 3221225472 Diag_PhyReq_FRM_Data6 "Diagnostic Physical Request Data to FRM";
CM_ SG_ 3221225472 Diag_PhyReq_FRM_Data7 "Diagnostic Physical Request Data to FRM";
CM_ SG_ 3221225472 Diag_PhyReq_FCM_Data0 "Diagnostic Physical Request Data to FCM";
CM_ SG_ 3221225472 Diag_PhyReq_FCM_Data1 "Diagnostic Physical Request Data to FCM";
CM_ SG_ 3221225472 Diag_PhyReq_FCM_Data2 "Diagnostic Physical Request Data to FCM";
CM_ SG_ 3221225472 Diag_PhyReq_FCM_Data3 "Diagnostic Physical Request Data to FCM";
CM_ SG_ 3221225472 Diag_PhyReq_FCM_Data4 "Diagnostic Physical Request Data to FCM";
CM_ SG_ 3221225472 Diag_PhyReq_FCM_Data5 "Diagnostic Physical Request Data to FCM";
CM_ SG_ 3221225472 Diag_PhyReq_FCM_Data6 "Diagnostic Physical Request Data to FCM";
CM_ SG_ 3221225472 Diag_PhyReq_FCM_Data7 "Diagnostic Physical Request Data to FCM";
CM_ SG_ 3221225472 Diag_PhyReq_APA_Data0 "Diagnostic Physical Request Data to APA";
CM_ SG_ 3221225472 Diag_PhyReq_APA_Data1 "Diagnostic Physical Request Data to APA";
CM_ SG_ 3221225472 Diag_PhyReq_APA_Data2 "Diagnostic Physical Request Data to APA";
CM_ SG_ 3221225472 Diag_PhyReq_APA_Data3 "Diagnostic Physical Request Data to APA";
CM_ SG_ 3221225472 Diag_PhyReq_APA_Data4 "Diagnostic Physical Request Data to APA";
CM_ SG_ 3221225472 Diag_PhyReq_APA_Data5 "Diagnostic Physical Request Data to APA";
CM_ SG_ 3221225472 Diag_PhyReq_APA_Data6 "Diagnostic Physical Request Data to APA";
CM_ SG_ 3221225472 Diag_PhyReq_APA_Data7 "Diagnostic Physical Request Data to APA";
CM_ SG_ 3221225472 Diag_PhyReq_AVP_Data0 "Diagnostic Physical Request Data to AVP";
CM_ SG_ 3221225472 Diag_PhyReq_AVP_Data1 "Diagnostic Physical Request Data to AVP";
CM_ SG_ 3221225472 Diag_PhyReq_AVP_Data2 "Diagnostic Physical Request Data to AVP";
CM_ SG_ 3221225472 Diag_PhyReq_AVP_Data3 "Diagnostic Physical Request Data to AVP";
CM_ SG_ 3221225472 Diag_PhyReq_AVP_Data4 "Diagnostic Physical Request Data to AVP";
CM_ SG_ 3221225472 Diag_PhyReq_AVP_Data5 "Diagnostic Physical Request Data to AVP";
CM_ SG_ 3221225472 Diag_PhyReq_AVP_Data6 "Diagnostic Physical Request Data to AVP";
CM_ SG_ 3221225472 Diag_PhyReq_AVP_Data7 "Diagnostic Physical Request Data to AVP";
CM_ SG_ 3221225472 Diag_PhyReq_ADC_Data0 "Diagnostic Physical Request Data to ADC";
CM_ SG_ 3221225472 Diag_PhyReq_ADC_Data1 "Diagnostic Physical Request Data to ADC";
CM_ SG_ 3221225472 Diag_PhyReq_ADC_Data2 "Diagnostic Physical Request Data to ADC";
CM_ SG_ 3221225472 Diag_PhyReq_ADC_Data3 "Diagnostic Physical Request Data to ADC";
CM_ SG_ 3221225472 Diag_PhyReq_ADC_Data4 "Diagnostic Physical Request Data to ADC";
CM_ SG_ 3221225472 Diag_PhyReq_ADC_Data5 "Diagnostic Physical Request Data to ADC";
CM_ SG_ 3221225472 Diag_PhyReq_ADC_Data6 "Diagnostic Physical Request Data to ADC";
CM_ SG_ 3221225472 Diag_PhyReq_ADC_Data7 "Diagnostic Physical Request Data to ADC";
CM_ SG_ 3221225472 Diag_PhyReq_CRFL_Data0 "Diagnostic Physical Request Data to CRFL";
CM_ SG_ 3221225472 Diag_PhyReq_CRFL_Data1 "Diagnostic Physical Request Data to CRFL";
CM_ SG_ 3221225472 Diag_PhyReq_CRFL_Data2 "Diagnostic Physical Request Data to CRFL";
CM_ SG_ 3221225472 Diag_PhyReq_CRFL_Data3 "Diagnostic Physical Request Data to CRFL";
CM_ SG_ 3221225472 Diag_PhyReq_CRFL_Data4 "Diagnostic Physical Request Data to CRFL";
CM_ SG_ 3221225472 Diag_PhyReq_CRFL_Data5 "Diagnostic Physical Request Data to CRFL";
CM_ SG_ 3221225472 Diag_PhyReq_CRFL_Data6 "Diagnostic Physical Request Data to CRFL";
CM_ SG_ 3221225472 Diag_PhyReq_CRFL_Data7 "Diagnostic Physical Request Data to CRFL";
CM_ SG_ 3221225472 Diag_PhyReq_CRFR_Data0 "Diagnostic Physical Request Data to CRFR";
CM_ SG_ 3221225472 Diag_PhyReq_CRFR_Data1 "Diagnostic Physical Request Data to CRFR";
CM_ SG_ 3221225472 Diag_PhyReq_CRFR_Data2 "Diagnostic Physical Request Data to CRFR";
CM_ SG_ 3221225472 Diag_PhyReq_CRFR_Data3 "Diagnostic Physical Request Data to CRFR";
CM_ SG_ 3221225472 Diag_PhyReq_CRFR_Data4 "Diagnostic Physical Request Data to CRFR";
CM_ SG_ 3221225472 Diag_PhyReq_CRFR_Data5 "Diagnostic Physical Request Data to CRFR";
CM_ SG_ 3221225472 Diag_PhyReq_CRFR_Data6 "Diagnostic Physical Request Data to CRFR";
CM_ SG_ 3221225472 Diag_PhyReq_CRFR_Data7 "Diagnostic Physical Request Data to CRFR";
CM_ SG_ 3221225472 Diag_PhyReq_CRRL_Data0 "Diagnostic Physical Request Data to CRRL";
CM_ SG_ 3221225472 Diag_PhyReq_CRRL_Data1 "Diagnostic Physical Request Data to CRRL";
CM_ SG_ 3221225472 Diag_PhyReq_CRRL_Data2 "Diagnostic Physical Request Data to CRRL";
CM_ SG_ 3221225472 Diag_PhyReq_CRRL_Data3 "Diagnostic Physical Request Data to CRRL";
CM_ SG_ 3221225472 Diag_PhyReq_CRRL_Data4 "Diagnostic Physical Request Data to CRRL";
CM_ SG_ 3221225472 Diag_PhyReq_CRRL_Data5 "Diagnostic Physical Request Data to CRRL";
CM_ SG_ 3221225472 Diag_PhyReq_CRRL_Data6 "Diagnostic Physical Request Data to CRRL";
CM_ SG_ 3221225472 Diag_PhyReq_CRRL_Data7 "Diagnostic Physical Request Data to CRRL";
CM_ SG_ 3221225472 Diag_PhyReq_CRRR_Data0 "Diagnostic Physical Request Data to CRRR";
CM_ SG_ 3221225472 Diag_PhyReq_CRRR_Data1 "Diagnostic Physical Request Data to CRRR";
CM_ SG_ 3221225472 Diag_PhyReq_CRRR_Data2 "Diagnostic Physical Request Data to CRRR";
CM_ SG_ 3221225472 Diag_PhyReq_CRRR_Data3 "Diagnostic Physical Request Data to CRRR";
CM_ SG_ 3221225472 Diag_PhyReq_CRRR_Data4 "Diagnostic Physical Request Data to CRRR";
CM_ SG_ 3221225472 Diag_PhyReq_CRRR_Data5 "Diagnostic Physical Request Data to CRRR";
CM_ SG_ 3221225472 Diag_PhyReq_CRRR_Data6 "Diagnostic Physical Request Data to CRRR";
CM_ SG_ 3221225472 Diag_PhyReq_CRRR_Data7 "Diagnostic Physical Request Data to CRRR";
CM_ SG_ 3221225472 Diag_Resp_FRM_Data0 "Diagnostic Response Data From FRM";
CM_ SG_ 3221225472 Diag_Resp_FRM_Data1 "Diagnostic Response Data From FRM";
CM_ SG_ 3221225472 Diag_Resp_FRM_Data2 "Diagnostic Response Data From FRM";
CM_ SG_ 3221225472 Diag_Resp_FRM_Data3 "Diagnostic Response Data From FRM";
CM_ SG_ 3221225472 Diag_Resp_FRM_Data4 "Diagnostic Response Data From FRM";
CM_ SG_ 3221225472 Diag_Resp_FRM_Data5 "Diagnostic Response Data From FRM";
CM_ SG_ 3221225472 Diag_Resp_FRM_Data6 "Diagnostic Response Data From FRM";
CM_ SG_ 3221225472 Diag_Resp_FRM_Data7 "Diagnostic Response Data From FRM";
CM_ SG_ 3221225472 Diag_Resp_FCM_Data0 "Diagnostic Response Data From FCM";
CM_ SG_ 3221225472 Diag_Resp_FCM_Data1 "Diagnostic Response Data From FCM";
CM_ SG_ 3221225472 Diag_Resp_FCM_Data2 "Diagnostic Response Data From FCM";
CM_ SG_ 3221225472 Diag_Resp_FCM_Data3 "Diagnostic Response Data From FCM";
CM_ SG_ 3221225472 Diag_Resp_FCM_Data4 "Diagnostic Response Data From FCM";
CM_ SG_ 3221225472 Diag_Resp_FCM_Data5 "Diagnostic Response Data From FCM";
CM_ SG_ 3221225472 Diag_Resp_FCM_Data6 "Diagnostic Response Data From FCM";
CM_ SG_ 3221225472 Diag_Resp_FCM_Data7 "Diagnostic Response Data From FCM";
CM_ SG_ 3221225472 Diag_Resp_APA_Data0 "Diagnostic Response Data From APA";
CM_ SG_ 3221225472 Diag_Resp_APA_Data1 "Diagnostic Response Data From APA";
CM_ SG_ 3221225472 Diag_Resp_APA_Data2 "Diagnostic Response Data From APA";
CM_ SG_ 3221225472 Diag_Resp_APA_Data3 "Diagnostic Response Data From APA";
CM_ SG_ 3221225472 Diag_Resp_APA_Data4 "Diagnostic Response Data From APA";
CM_ SG_ 3221225472 Diag_Resp_APA_Data5 "Diagnostic Response Data From APA";
CM_ SG_ 3221225472 Diag_Resp_APA_Data6 "Diagnostic Response Data From APA";
CM_ SG_ 3221225472 Diag_Resp_APA_Data7 "Diagnostic Response Data From APA";
CM_ SG_ 3221225472 Diag_Resp_ADC_Data0 "Diagnostic Response Data From ADC";
CM_ SG_ 3221225472 Diag_Resp_ADC_Data1 "Diagnostic Response Data From ADC";
CM_ SG_ 3221225472 Diag_Resp_ADC_Data2 "Diagnostic Response Data From ADC";
CM_ SG_ 3221225472 Diag_Resp_ADC_Data3 "Diagnostic Response Data From ADC";
CM_ SG_ 3221225472 Diag_Resp_ADC_Data4 "Diagnostic Response Data From ADC";
CM_ SG_ 3221225472 Diag_Resp_ADC_Data5 "Diagnostic Response Data From ADC";
CM_ SG_ 3221225472 Diag_Resp_ADC_Data6 "Diagnostic Response Data From ADC";
CM_ SG_ 3221225472 Diag_Resp_ADC_Data7 "Diagnostic Response Data From ADC";
CM_ SG_ 3221225472 Diag_Resp_CRFL_Data0 "Diagnostic Response Data From CRFL";
CM_ SG_ 3221225472 Diag_Resp_CRFL_Data1 "Diagnostic Response Data From CRFL";
CM_ SG_ 3221225472 Diag_Resp_CRFL_Data2 "Diagnostic Response Data From CRFL";
CM_ SG_ 3221225472 Diag_Resp_CRFL_Data3 "Diagnostic Response Data From CRFL";
CM_ SG_ 3221225472 Diag_Resp_CRFL_Data4 "Diagnostic Response Data From CRFL";
CM_ SG_ 3221225472 Diag_Resp_CRFL_Data5 "Diagnostic Response Data From CRFL";
CM_ SG_ 3221225472 Diag_Resp_CRFL_Data6 "Diagnostic Response Data From CRFL";
CM_ SG_ 3221225472 Diag_Resp_CRFL_Data7 "Diagnostic Response Data From CRFL";
CM_ SG_ 3221225472 Diag_Resp_CRFR_Data0 "Diagnostic Response Data From CRFR";
CM_ SG_ 3221225472 Diag_Resp_CRFR_Data1 "Diagnostic Response Data From CRFR";
CM_ SG_ 3221225472 Diag_Resp_CRFR_Data2 "Diagnostic Response Data From CRFR";
CM_ SG_ 3221225472 Diag_Resp_CRFR_Data3 "Diagnostic Response Data From CRFR";
CM_ SG_ 3221225472 Diag_Resp_CRFR_Data4 "Diagnostic Response Data From CRFR";
CM_ SG_ 3221225472 Diag_Resp_CRFR_Data5 "Diagnostic Response Data From CRFR";
CM_ SG_ 3221225472 Diag_Resp_CRFR_Data6 "Diagnostic Response Data From CRFR";
CM_ SG_ 3221225472 Diag_Resp_CRFR_Data7 "Diagnostic Response Data From CRFR";
CM_ SG_ 3221225472 Diag_Resp_CRRL_Data0 "Diagnostic Response Data From CRRL";
CM_ SG_ 3221225472 Diag_Resp_CRRL_Data1 "Diagnostic Response Data From CRRL";
CM_ SG_ 3221225472 Diag_Resp_CRRL_Data2 "Diagnostic Response Data From CRRL";
CM_ SG_ 3221225472 Diag_Resp_CRRL_Data3 "Diagnostic Response Data From CRRL";
CM_ SG_ 3221225472 Diag_Resp_CRRL_Data4 "Diagnostic Response Data From CRRL";
CM_ SG_ 3221225472 Diag_Resp_CRRL_Data5 "Diagnostic Response Data From CRRL";
CM_ SG_ 3221225472 Diag_Resp_CRRL_Data6 "Diagnostic Response Data From CRRL";
CM_ SG_ 3221225472 Diag_Resp_CRRL_Data7 "Diagnostic Response Data From CRRL";
CM_ SG_ 3221225472 Diag_Resp_CRRR_Data0 "Diagnostic Response Data From CRRR";
CM_ SG_ 3221225472 Diag_Resp_CRRR_Data1 "Diagnostic Response Data From CRRR";
CM_ SG_ 3221225472 Diag_Resp_CRRR_Data2 "Diagnostic Response Data From CRRR";
CM_ SG_ 3221225472 Diag_Resp_CRRR_Data3 "Diagnostic Response Data From CRRR";
CM_ SG_ 3221225472 Diag_Resp_CRRR_Data4 "Diagnostic Response Data From CRRR";
CM_ SG_ 3221225472 Diag_Resp_CRRR_Data5 "Diagnostic Response Data From CRRR";
CM_ SG_ 3221225472 Diag_Resp_CRRR_Data6 "Diagnostic Response Data From CRRR";
CM_ SG_ 3221225472 Diag_Resp_CRRR_Data7 "Diagnostic Response Data From CRRR";
CM_ SG_ 3221225472 Diag_Resp_AVP_Data0 "Diagnostic Response Data From AVP";
CM_ SG_ 3221225472 Diag_Resp_AVP_Data1 "Diagnostic Response Data From AVP";
CM_ SG_ 3221225472 Diag_Resp_AVP_Data2 "Diagnostic Response Data From AVP";
CM_ SG_ 3221225472 Diag_Resp_AVP_Data3 "Diagnostic Response Data From AVP";
CM_ SG_ 3221225472 Diag_Resp_AVP_Data4 "Diagnostic Response Data From AVP";
CM_ SG_ 3221225472 Diag_Resp_AVP_Data5 "Diagnostic Response Data From AVP";
CM_ SG_ 3221225472 Diag_Resp_AVP_Data6 "Diagnostic Response Data From AVP";
CM_ SG_ 3221225472 Diag_Resp_AVP_Data7 "Diagnostic Response Data From AVP";
CM_ SG_ 3221225472 Diag_FuncReq_Data0 "Diagnostic Functional Request Data";
CM_ SG_ 3221225472 Diag_FuncReq_Data1 "Diagnostic Functional Request Data";
CM_ SG_ 3221225472 Diag_FuncReq_Data2 "Diagnostic Functional Request Data";
CM_ SG_ 3221225472 Diag_FuncReq_Data3 "Diagnostic Functional Request Data";
CM_ SG_ 3221225472 Diag_FuncReq_Data4 "Diagnostic Functional Request Data";
CM_ SG_ 3221225472 Diag_FuncReq_Data5 "Diagnostic Functional Request Data";
CM_ SG_ 3221225472 Diag_FuncReq_Data6 "Diagnostic Functional Request Data";
CM_ SG_ 3221225472 Diag_FuncReq_Data7 "Diagnostic Functional Request Data";
CM_ SG_ 464 AVP_B_Chksum "Message Checksum";
CM_ SG_ 464 AVP_B_AliveCnt "Message Alive Counter";
CM_ BO_ 130 "VCU Tx and AcclPedal related";
CM_ SG_ 130 VCU_AcclPedalPosToESCSta "Accelerator Pedal Position Value Status（ESC special）
加速踏板位置状态（ESC专用）";
CM_ SG_ 130 VCU_SysFailSta "VCU  System Failure Status
VCU系统失效状态";
CM_ SG_ 130 VCU_AcclPedalPosToESC "Accelerator Pedal Position（ESC special）
加速踏板位置（ESC专用）";
CM_ SG_ 130 VCU_ReqEPB "VCU请求EPB驻车";
CM_ SG_ 130 VCU_ReqEPBV "VCU请求EPB驻车信号有效性";
CM_ SG_ 130 VCU_ErrAmount "Error Amount
故障总数";
CM_ SG_ 130 VCU_ErrBit "VCU故障码";
CM_ SG_ 130 VCU_B_AliveCnt "Message Alive Counter";
CM_ SG_ 130 VCU_EPK_ParkLock "EPARK换档电机棘爪状态
Status of the park pawl.";
CM_ SG_ 130 VCU_B_Chksum "Message Checksum";
CM_ BO_ 388 "AVP Tx";
CM_ SG_ 388 AVP_HAVP_Recover_Indication "可恢复中断原因";
CM_ SG_ 388 AVP_HAVP_Quit_Indication "HAVP HRVP退出原因";
CM_ SG_ 388 AVP_HAVP_System_Info "HAVP系统执行状态指示信息";
CM_ SG_ 388 AVP_VP_Info_Apply_P_EPB "上电条件提醒，拉起P+EPB";
CM_ SG_ 388 AVP_VP_Info_Stop_Charging "非充电模式提醒";
CM_ SG_ 388 AVP_VP_Info_Vechicle_PowerOff "整车OFF电模式提醒";
CM_ SG_ 388 AVP_VP_Quit_Indication "AVP退出原因";
CM_ SG_ 388 AVP_VP_Recover_Indication "可恢复中断原因";
CM_ SG_ 388 AVP_VP_System_Info "用于与用户交互的过程";
CM_ SG_ 388 AVP_Aeb_TgtAx "AEB target deceleration";
CM_ SG_ 388 AVP_AebReqEna "Enable flag for AEB of target accleration";
CM_ SG_ 388 AVP_decFlg "AVP's deceleration controll flag";
CM_ SG_ 388 AVP_AccReq_DrvOff "AVP request the VLC to drive off";
CM_ SG_ 388 AVP_AccReq_Standstill "AVP request the VLC to decelerate to stop";
CM_ SG_ 388 AVP_A_AliveCnt "Message Alive Counter";
CM_ SG_ 388 AVP_A_Chksum "Message Checksum";
CM_ SG_ 388 AVP_LogoLamp_Req "Logo灯点亮请求（预留两个状态，颜色待定），与HAVP共用，发送节点王工补充";
CM_ SG_ 388 AVP_HighBeamLamp_Req "远光灯点亮请求，与HAVP共用";
CM_ SG_ 388 AVP_LowBeamLamp_Req "近光灯点亮请求，与HAVP共用";
CM_ SG_ 388 AVP_HazardLamp_Req "危险报警灯点亮请求，与HAVP共用";
CM_ SG_ 388 AVP_TurnLeftLamp_Req "左转向灯点亮请求,闪的频率是BCM控制，与HAVP共用";
CM_ SG_ 388 AVP_TurnRightLamp_Req "右转向灯点亮请求,闪的频率是BCM控制，与HAVP共用";
CM_ SG_ 388 AVP_Horn_Req "喇叭控制请求，与HAVP共用";
CM_ SG_ 388 AVP_Wiper_Req "雨刮请求，与HAVP共用";
CM_ SG_ 388 AVP_WaterSpray_Req "喷水请求，与HAVP共用";
CM_ SG_ 388 AVP_PwrMode_Req "系统的电源模式请求";
CM_ SG_ 388 AVP_Acc_MotorTorqReqValue "The signal specifies the VLC target motor torque at motor output side above driver requested torque";
CM_ SG_ 388 AVP_AccTrqReqEna "Enable flag for EMS for realization of target torque AccTrqReq";
CM_ SG_ 388 AVP_FctSts "AVP working functions' inaication signal";
CM_ SG_ 388 AVP_Runng "AVP controller will send this command to let BCM change power mode from local ON to RPA ON when the vehicle speed is lower 1 or 2 km/h.在到达下车点并且车速小于1或者2的时候发出这个信号，提醒BCM不能下电，因为用户要关闭车门，并且上锁，此时AVP发出上电请求，电源模式能够直接从本地ON切到ＲＰＡＯＮ";
CM_ SG_ 388 AVP_Acc_TgtAxReq "Whether the signal ACC_TgtAx should be considered or not";
CM_ SG_ 388 AVP_Acc_Mode "The status of the ACC control unitThe ACC mode should be contained in every message sent by ACC";
CM_ SG_ 388 AVP_Acc_TgtAx "ACC target deceleration";
CM_ SG_ 388 AVP_HAVP_Status "HAVP工作状态";
CM_ SG_ 388 AVP_VP_Status "自动泊车功能状态";
CM_ SG_ 388 AVP_TrgtGearReq "档位请求";
CM_ SG_ 388 AVP_TrgtGearReqV "档位请求有效性";
CM_ SG_ 388 AVP_HAVP_StrtgEndgPointInfo "This signal indicates the reasons for invalid starting and ending point 该信号用于学习过程中发给HU提示起点或者终点设置无效的原因";
CM_ SG_ 388 AVP_HAVP_Learning_Failed_Info "Learning failed reasons for HAVP learning results.";
CM_ SG_ 388 AVP_Learning_PathNum1 "AVP发给HU的学习路线信息，第一部分：路线序号，0x0表示无路线";
CM_ SG_ 388 AVP_HAVP_Learning_Process_Info "AVP controller will send this singal to show indications through HU to driver during learning process.";
CM_ SG_ 388 AVP_Learning_PathType1 "AVP发给HU的学习路线信息，第二部分：路线类型，0x0表示无效路线";
CM_ SG_ 388 AVP_Learning_LotType1 "AVP发给HU的学习路线信息，第三部分：车位类型，0x0表示无效路线";
CM_ SG_ 388 AVP_HAVP_Path_Status1 "AVP发出的路线1的状态信号";
CM_ SG_ 388 AVP_HAVP_Path_Learnrate1 "HAVP模式下，路线1学习进度显示信号";
CM_ SG_ 388 AVP_Learning_PathNum2 "AVP发给HU的学习路线信息，第一部分：路线序号，0x0表示无路线";
CM_ SG_ 388 AVP_Learning_PathType2 "AVP发给HU的学习路线信息，第二部分：路线类型，0x0表示无效路线";
CM_ SG_ 388 AVP_Learning_LotType2 "AVP发给HU的学习路线信息，第三部分：车位类型，0x0表示无效路线";
CM_ SG_ 388 AVP_HAVP_Path_Status2 "AVP发出的路线2的状态信号";
CM_ SG_ 388 AVP_HAVP_Path_Learnrate2 "HAVP模式下，路线2学习进度显示信号";
CM_ SG_ 388 AVP_Learning_PathType3 "AVP发给HU的学习路线信息，第二部分：路线类型，0x0表示无效路线";
CM_ SG_ 388 AVP_Learning_PathNum3 "AVP发给HU的学习路线信息，第一部分：路线序号，0x0表示无路线";
CM_ SG_ 388 AVP_Learning_LotType3 "AVP发给HU的学习路线信息，第三部分：车位类型，0x0表示无效路线";
CM_ SG_ 388 AVP_HAVP_Path_Status3 "AVP发出的路线3的状态信号";
CM_ SG_ 388 AVP_HAVP_Path_Learnrate3 "HAVP模式下，路线3学习进度显示信号";
CM_ SG_ 388 AVP_Learning_PathNum4 "AVP发给HU的学习路线信息，第一部分：路线序号，0x0表示无路线";
CM_ SG_ 388 AVP_Learning_PathType4 "AVP发给HU的学习路线信息，第二部分：路线类型，0x0表示无效路线";
CM_ SG_ 388 AVP_Learning_LotType4 "AVP发给HU的学习路线信息，第三部分：车位类型，0x0表示无效路线";
CM_ SG_ 388 AVP_HAVP_Path_Status4 "AVP发出的路线4的状态信号";
CM_ SG_ 388 AVP_HAVP_Path_Learnrate4 "HAVP模式下，路线4学习进度显示信号";
CM_ SG_ 388 AVP_Learning_PathType5 "AVP发给HU的学习路线信息，第二部分：路线类型，0x0表示无效路线";
CM_ SG_ 388 AVP_Learning_PathNum5 "AVP发给HU的学习路线信息，第一部分：路线序号，0x0表示无路线";
CM_ SG_ 388 AVP_Learning_LotType5 "AVP发给HU的学习路线信息，第三部分：车位类型，0x0表示无效路线";
CM_ SG_ 388 AVP_HAVP_Path_Status5 "AVP发出的路线5的状态信号";
CM_ SG_ 388 AVP_HAVP_Path_Learnrate5 "HAVP模式下，路线5学习进度显示信号";
CM_ SG_ 388 AVP_LrngDst "Learning distance calculated by AVP controller;";
CM_ SG_ 388 AVP_HAVP_ProcRat "HAVP drving process ratio;用户选择的路线的执行进度";
CM_ SG_ 388 AVP_HAVP_PahDst1 "Learned path distance;有效路线的长度";
CM_ SG_ 388 AVP_HAVP_PahDst2 "Learned path distance;有效路线的长度";
CM_ SG_ 388 AVP_HAVP_PahDst3 "Learned path distance;有效路线的长度";
CM_ SG_ 388 AVP_HAVP_PahDst4 "Learned path distance;有效路线的长度";
CM_ SG_ 388 AVP_HAVP_PahDst5 "Learned path distance;有效路线的长度";
CM_ SG_ 388 AVP_HAVP_DrvrReq "HAVP Driver Request HAVP使用驾驶员提示信息";
CM_ SG_ 388 AVP_FrntCamCalSts "前广角摄像头标定状态
Fornt camera calibration status";
CM_ SG_ 388 AVP_LrngDst_LeOver "剩余可学习路线长度 AVP learning distance left over";
CM_ BO_ 115 "VCU Tx and Torque related";
CM_ SG_ 115 VCU_Actl_MotorTorqueV "Actual Motor Torque Validity
实际电机端扭矩有效性";
CM_ SG_ 115 VCU_EparkSysSta "EPARK System Status
EPARK系统状态";
CM_ SG_ 115 VCU_VhclSpeedFastWarn "Vehicle Speed too Fast Warning
车辆速度过快提醒";
CM_ SG_ 115 VCU_Actl_MotorTorque "Actual Motor Torque
实际电机端扭矩（单电机前驱，电机端输出净扭矩，传递到轮端的效率为0.95*0.95=0.9025）";
CM_ SG_ 115 VCU_DrvReq_MotorTorqV "Driver Requeste Motor Torque Validity
驾驶员请求电机端扭矩有效性";
CM_ SG_ 115 VCU_DrvReq_MotorTorq "Driver Requeste Motor Torque
驾驶员请求电机端扭矩（单电机前驱，电机端输出净扭矩，传递到轮端的效率为0.95*0.95=0.9025）";
CM_ SG_ 115 VCU_Actl_MotorRotateSpdV "Actual Motor Rotate Speed Validity
实际电机端转速有效性";
CM_ SG_ 115 VCU_Actl_MotorRotateSpd "Actual Motor Rotate Speed
实际电机端转速";
CM_ SG_ 115 VCU_1_AliveCnt "Message Alive Counter";
CM_ SG_ 115 VCU_EPKActlStatusHMI "EPARK换档电机实际状态显示
EPARK actual Status to HMI.";
CM_ SG_ 115 VCU_1_Chksum "Message Checksum";
CM_ BO_ 116 "VCU Tx and Power Recuperation related";
CM_ SG_ 116 VCU_PwrRecupMaxAvlbMotorTorq "Power Recuperation Max Availabe Motor Torque（单电机前驱，电机端输出净扭矩，传递到轮端的效率为0.95*0.95=0.9025）";
CM_ SG_ 116 VCU_PwrRecupActlMotorTorq "Power Recuperation Actual Motor Torque";
CM_ SG_ 116 VCU_PwrRecupMaxAvlbMotorTorqSta "Power Recuperation Max Availabe Motor Torque Status";
CM_ SG_ 116 VCU_MAAAvail "MAA可支持标志位";
CM_ SG_ 116 VCU_PwrRecupActlMotorTorqSta "Power Recuperation Actual Motor Torque Status";
CM_ SG_ 116 VCU_MAA_ActvFdbk "MAA执行反馈";
CM_ SG_ 116 VCU_2_AliveCnt "Message Alive Counter";
CM_ SG_ 116 VCU_BrakePwrRecupActlMotorTorqSt "Brake Power Recuperation Actual Motor Torque Status";
CM_ SG_ 116 VCU_BrakePwrRecupActlMotorTorq "Brake Power Recuperation Actual Motor Torque";
CM_ SG_ 116 VCU_2_Chksum "Message Checksum";
CM_ BO_ 274 "VCU Tx and Position Temperature Pressure related";
CM_ SG_ 274 VCU_AcclPedalPos "Accelerator Pedal Position
加速踏板位置";
CM_ SG_ 274 VCU_BrkPedalPos "Brake Pedal Position
制动踏板位置";
CM_ SG_ 274 VCU_VacuumPressure "Vacuum Pressure Relateive Value
真空度压力";
CM_ SG_ 274 VCU_BrkPedalSnsrPosV_Reserved "Brake Pedal Position Sensor Status_ Reserved
制动踏板位置传感器状态_Reserved";
CM_ SG_ 274 VCU_MotPumpSta_reserved "Motor Pump Work Status reserved";
CM_ SG_ 274 VCU_PCUWaterPumpSta "PCU Water Pump Work Status
PCU水泵工作状态";
CM_ SG_ 274 VCU_VacmPumpSta "Vacuum Pump Work Status
真空泵工作状态";
CM_ SG_ 274 VCU_DrvReqTorqOverrideESC "Driver Request Torque Override ESC
驾驶员请求扭矩大于ESC请求扭矩";
CM_ SG_ 274 VCU_MotorTemp "Motor Temperature";
CM_ SG_ 274 VCU_5_AliveCnt "Message Alive Counter";
CM_ SG_ 274 VCU_HighVolInterlockSta "High Voltage Interlock State at VCU End
VCU端高压互锁状态";
CM_ SG_ 274 VCU_AcclPedalPosSnsrSta "Accelerator Pedal Position Sensor Status
加速踏板位置传感器状态";
CM_ SG_ 274 VCU_5_Chksum "Message Checksum";
CM_ BO_ 281 "BCM Tx and CruiseSw + Power Mode related";
CM_ SG_ 281 BCM_CruiseDistanceIncre "Cruise Distance Increment / +";
CM_ SG_ 281 BCM_CruiseDistanceDecre "Cruise Distance Decrement /-";
CM_ SG_ 281 BCM_CruiseModeCancel "Cruise Mode Cancel";
CM_ SG_ 281 BCM_CruiseRES "Cruise Resume / Speed Up";
CM_ SG_ 281 BCM_CruiseSET "Cruise Set / Speed Down";
CM_ SG_ 281 BCM_CruiseModeChange "Cruise Mode Change";
CM_ SG_ 281 BCM_CruiseRES_Valid "Cruise Resume / Speed Up Validity";
CM_ SG_ 281 BCM_CruiseMainSwitch "Cruise Main Switch
巡航主开关";
CM_ SG_ 281 BCM_SysPwrModeV "System Power Mode Validity
系统电源模式有效性";
CM_ SG_ 281 BCM_SysPwrMode "System Power Mode
系统电源模式";
CM_ SG_ 281 BCM_Cruise_limit_reserved "speed limit sw";
CM_ SG_ 281 BCM_HighBeamSwSta "High beam switch status";
CM_ SG_ 281 BCM_HMASta "HMA status to display";
CM_ SG_ 281 BCM_SysPowerSts "整车电源状态";
CM_ SG_ 281 BCM_StartReq "Start Request
启动请求";
CM_ SG_ 281 BCM_ThermRunawayWarn "Battery Pack thermal runaway warning
电池包热失控报警信号";
CM_ SG_ 281 BCM_vSetDis "The set speed from driver, should be available as long as ACC is active";
CM_ SG_ 281 BCM_ThermRunawaySnsrFlt "thermal runaway sensor fault
热失控传感器故障";
CM_ SG_ 281 BCM_4_AliveCnt "Message Alive Counter";
CM_ SG_ 281 BCM_4_Chksum "Message checksum";
CM_ BO_ 288 "ESC Tx";
CM_ SG_ 288 ESC_DTC_ActiveSts "Drag Torque Control Active Status";
CM_ SG_ 288 ESC_BrakeTempOverHeat "Brake Disk Temperature Over Heat";
CM_ SG_ 288 ESC_NoBrakeForce "No Brake Force";
CM_ SG_ 288 ESC_ABP_AvailableSta "Prefill  Automatic Brake Parking Available Status";
CM_ SG_ 288 ESC_ABP_ActiveSta "Prefill Automatic Brake Parking Active Status";
CM_ SG_ 288 ESC_AEB_ActiveSta "Automatic Emergency Brake Active Status";
CM_ SG_ 288 ESC_AEB_AvailableSta "Automatic Emergency Brake Available Status";
CM_ SG_ 288 ESC_AWB_ActiveSta "Automatic Warning Brake Active Status";
CM_ SG_ 288 ESC_AWB_AvailableSta "Automatic Warning Brake Available Status";
CM_ SG_ 288 ESC_ABA_ActiveSta "Adaptive Brake Assist Active Status";
CM_ SG_ 288 ESC_ABA_AvailableSta "Adaptive Brake Assist Available Status";
CM_ SG_ 288 ESC_VhclStandstillSta "Vehicle Standstill Status";
CM_ SG_ 288 ESC_RCTB_AvailableSta "RCTB Available Status";
CM_ SG_ 288 ESC_RCTB_ActiveSta "RCTB Active Status";
CM_ SG_ 288 ESC_HMI_WarningOn "ESC请求点亮故障灯";
CM_ SG_ 288 ESC_ParkPawlRequest "P Gear request";
CM_ SG_ 288 ESC_ParkPawlRequestV "P Gear request Validity";
CM_ SG_ 288 ESC_LSMHldActv "Indicate hold function for parking active or not";
CM_ SG_ 288 ESC_LSMSSMSta "Indicate vehicle is standstill or not during parking";
CM_ SG_ 288 ESC_A_AliveCnt "Message Alive Counter";
CM_ SG_ 288 ESC_A_Chksum "Message checksum";
CM_ SG_ 288 YRS_YawRate "Indicates Yaw Rate Compensated

 0x8CA1~0xFFFF:Invalid";
CM_ SG_ 288 YRS_LateralSensorState "Indicates Lateral Sensor State";
CM_ SG_ 288 YRS_YawRateSensorState "Indicates YawRate Sensor State";
CM_ SG_ 288 YRS_LateralAcce "Indicates Lateral Acceleration Compensated

 0x0FA1~0xFFFF:Invalid";
CM_ SG_ 288 YRS_LongitSensorState "Indicates Longitudinal Sensor State";
CM_ SG_ 288 YRS_LongitAcce "Indicates Longitudinal Acceleration Compensated

 0x0FA1~0xFFFF:Invalid";
CM_ SG_ 288 ESC_MotorTorqDecReqActive "Motor Torque Decrease Request Active";
CM_ SG_ 288 ESC_MotorTorqDecReqValue "ESC request to Decrease Motor Torque at motor output side to Requested Value";
CM_ SG_ 288 ESC_MotorTorqIncReqActive "Motor Torque Increase Request Active";
CM_ SG_ 288 ESC_PwrRecupTrgtMotorTorqSta "Power Recuperation Target Motor Torque Status";
CM_ SG_ 288 ESC_MotorTorqIncReqValue "ESC request to Increase Motor Torque at motor output side to Requested Value";
CM_ SG_ 288 ESC_PwrRecupTrgtMotorTorq "Power Recuperation Target Motor Torque at motor output side";
CM_ SG_ 288 ESC_CDDAvailable "Vehicle Longitudinal Control Deceleration Interface Available When Cruise Control";
CM_ SG_ 288 ESC_CDDActive "This signal indicates the cruise control system an active CDD control";
CM_ SG_ 288 ESC_VLCAPMotorTorqReqActive "if VLC_AP target Motor torque requested torque active";
CM_ SG_ 288 ESC_VLCAPMotorTorqReqValue "The signal specifies the VLC_AP target motor torque at motor output side above driver requested torque";
CM_ SG_ 288 ESC_CDDTempOff "Indicating brake temperature too high or not";
CM_ SG_ 288 ESC_Cruisecontrolshutdown "Switch off of the cruise control (ON/OFF)";
CM_ SG_ 288 ESC_CDDInternTrgtAccValue "Internal CDD Target Acceleration Value";
CM_ SG_ 288 ESC_WheelSpeedKphV_FL "ESC Front Left Wheel Speed KPH Validity";
CM_ SG_ 288 ESC_WheelDirection_FL "ESC Front Left Wheel Direction";
CM_ SG_ 288 ESC_WheelSpeedKph_FL "ESC Front Left Wheel Speed KPH";
CM_ SG_ 288 ESC_WheelSpeedKphV_FR "ESC Front Right Wheel Speed KPH Validity";
CM_ SG_ 288 ESC_WheelDirection_FR "ESC Front Right Wheel Direction";
CM_ SG_ 288 ESC_WheelSpeedKph_FR "ESC Front Right Wheel Speed KPH";
CM_ SG_ 288 ESC_MasterCylinderPresr "Master Cylinder Pressure  Compensated";
CM_ SG_ 288 ESC_MasterCylinderPresrV "Master Cylinder Pressure Validity";
CM_ SG_ 288 ESC_WheelSpeedKphV_RL "ESC Rear Left Wheel Speed KPH Validity";
CM_ SG_ 288 ESC_WheelDirection_RL "ESC Rear Left Wheel Direction";
CM_ SG_ 288 ESC_WheelSpeedKph_RL "ESC Rear Left Wheel Speed KPH";
CM_ SG_ 288 ESC_WheelSpeedKphV_RR "ESC Rear Right Wheel Speed KPH Validity";
CM_ SG_ 288 ESC_WheelDirection_RR "ESC Rear Right Wheel Direction";
CM_ SG_ 288 ESC_WheelSpeedKph_RR "ESC Rear Right Wheel Speed KPH";
CM_ SG_ 288 ESC_WheelSpeedRC_FL "ESC Front Left Wheel Speed Pulse";
CM_ SG_ 288 ESC_WheelSpeedRC_FR "ESC Front Right Wheel Speed Pulse";
CM_ SG_ 288 ESC_WheelSpeedRC_RL "ESC Rear Left Wheel Speed Pulse";
CM_ SG_ 288 ESC_WheelSpeedRC_RR "ESC Rear Right Wheel Speed Pulse";
CM_ SG_ 288 ESC_WheelSpeedRCSts_RR "ESC Rear Right Wheel Speed Pulse Status";
CM_ SG_ 288 ESC_WheelSpeedRCSts_RL "ESC Rear Left Wheel Speed Pulse Status";
CM_ SG_ 288 ESC_WheelSpeedRCSts_FR "ESC Front Right Wheel Speed Pulse Status";
CM_ SG_ 288 ESC_WheelSpeedRCSts_FL "ESC Front Left Wheel Speed Pulse Status";
CM_ SG_ 288 ESC_ABSActiveSta "ABS Active Status";
CM_ SG_ 288 ESC_ESCorTCSFailed "ESC/TCS Failure for driver";
CM_ SG_ 288 ESC_EBDFailed "EBD Failure for driver";
CM_ SG_ 288 ESC_ABSFailed "ABS Failure/Normal Sate of Current Running";
CM_ SG_ 288 ESC_TCSActiveSta "TCS Active Status";
CM_ SG_ 288 ESC_ESPActiveSta "ESP Active Status";
CM_ SG_ 288 ESC_VehicleSpeedV "Vehicle Speed Validity";
CM_ SG_ 288 ESC_ReqBrakeLightOn "Request Brake Light On
请求点亮刹车灯";
CM_ SG_ 288 ESC_VehicleSpeed "Vehicle Speed";
CM_ SG_ 288 ESC_HAZActive "Emergency Stop Active";
CM_ SG_ 288 ESC_HBB_Intervention "Hydraulic Brake Boost  Intervention";
CM_ SG_ 288 ESC_HBB_Sts "Hydraulic Brake Boost Status";
CM_ SG_ 288 ESC_AVH_Sts "Auto Vehicle Hold Status";
CM_ SG_ 288 ESC_BrakePedalSwV "Brake Pedal Switch Validity";
CM_ SG_ 288 ESC_BrakePedalSwSta "Brake Pedal Switch Status";
CM_ SG_ 288 ESC_PALAResponse "PALA Request has been Treated";
CM_ SG_ 288 ESC_AVH_ICUPrompt "ICU prompt when pressing AVH switch";
CM_ SG_ 288 ESC_HHC_ActiveSta "Hill Hold Control Active Status
上坡辅助激活状态";
CM_ SG_ 288 ESC_HHC_FailSta "Hill Hold Control Failure Status
上坡辅助失效状态";
CM_ SG_ 288 ESC_HDC_WorkSts "Hill Descent Control Work Status
下坡辅助状态";
CM_ SG_ 288 ESC_TrgtGearReqV "Target Gear Request  Validity";
CM_ SG_ 288 ESC_TrgtGearReq "Target Gear Request";
CM_ BO_ 352 "ESC Tx";
CM_ SG_ 352 ESC_EPB_ParkLampSta "Park Lamp State
驻车灯状态";
CM_ SG_ 352 ESC_EPB_WarnLampSta "EPB Warning Lamp State
EPB故障灯状态";
CM_ SG_ 352 ESC_EPB_SwitchSta "EPB Switch State 
EPB开关状态";
CM_ SG_ 352 ESC_EPB_ActuatorSt_R "Right EPB Actuator State
右Moc状态";
CM_ SG_ 352 ESC_EPB_ActuatorSt_L "Left EPB Actuator State
左Moc状态";
CM_ SG_ 352 ESC_EPB_DynamicApplySta "Dynamic Apply Status
动态制动状态";
CM_ SG_ 352 ESC_EPB_DisplayMsgID "Display  Message ID Requested by EPB to ICU   仪表文字提示信息优先级（ESC ONLY）：0x4>0x1>0x2>0x3>0x0";
CM_ SG_ 352 ESC_EPB_SystemState "EPB执行机构统一状态";
CM_ SG_ 352 ESC_IB11_AccStabAvail "The signal indicates whether acceleration stabilization like TCS function is available (no DTC considered)";
CM_ SG_ 352 ESC_IB11_YawRateStabAvailability "Yawrate stabilization function on brake (VDC,…) are available";
CM_ SG_ 352 ESC_B_AliveCnt "Message Alive Counter";
CM_ SG_ 352 ESC_IB11_DecStabCpblty "Deceleration Stabilization Capability";
CM_ SG_ 352 ESC_IB11_DecStabCpbltyForDrvr "Deceleration Stabilization Capability";
CM_ SG_ 352 ESC_B_Chksum "Message checksum";
CM_ SG_ 352 ESC_PresrEstMax "Maximum of the estimated wheels pressure";
CM_ SG_ 352 ESC_PresrMCVirtualQ "Qualifier for Virtual master cylinder pressure";
CM_ SG_ 352 ESC_ForceBlendingActive "ESC ForceBlendingActive";
CM_ SG_ 352 ESC_PresrMCVirtual "Virtual master cylinder pressure caluclated in ESP based on sOutputRodDriver";
CM_ SG_ 352 ESC_PresrForceBlendingMC "Target value of master cylinder pressure used by force blending function";
CM_ SG_ 352 ESC_ReqTargetExternal "Average value of target volume flow (ml/s) in master cylinder via external brake request (EBR) applied by iBooster";
CM_ SG_ 352 ESC_PresrForceBlendingMCQ "Qualifier for PressurepForceBlendingMc";
CM_ SG_ 352 ESC_ReqTargetExternalQ "Qualifier for ReqTargetExternal";
CM_ SG_ 352 ESC_LSMPosLongACapbl "ESC当前制动能力";
CM_ SG_ 352 ESC_LSMSubMTReqAvailable "LSM系统是否可用";
CM_ SG_ 352 ESC_LSMSubMTLevelEcho "反馈当前LSM执行制动的功能";
CM_ SG_ 352 ESC_LSMSubMTLongEcho "反馈当前LSM执行制动的舒适紧急类型";
CM_ SG_ 352 ESC_LSMSubMTReqEcho "反馈当前LSM模式";
CM_ SG_ 352 ESC_Lsm12ComfortAvl "APA功能舒适制动类型";
CM_ SG_ 352 ESC_Lsm12EmergencyAvl "APA功能紧急制动类型";
CM_ SG_ 352 ESC_Lsm23Avl "RPA功能制动类型";
CM_ SG_ 352 ESC_EBDActiveSta "EBD Active Status";
CM_ SG_ 352 ESC_HBC_ActiveSta "HBC Active Status";
CM_ SG_ 352 ESC_HBC_Available "HBC Available Status";
CM_ SG_ 352 ESC_HBAActiveSta "HBA Active Status";
CM_ SG_ 352 ESC_HBA_Available "HBA Available Status";
CM_ SG_ 352 ESC_DTC_Available "DTC Available Status";
CM_ SG_ 352 ESC_CDP_ActiveSta "CDPActive Status";
CM_ SG_ 352 ESC_CDP_Available "CDP Available Status";
CM_ SG_ 352 WheelBrakeForce "Estimated sum of vehicle brake forces acting on each wheel";
CM_ SG_ 352 ESC_CMMotionSrvReq "Valid motion service request after plausibility check in main ECU，校验过的Motion Service请求，指示LSM 激活";
CM_ SG_ 352 ESC_VmcActLongPrimaryAvailable "Availability information of VMC in primary actuator/ECU主VMC可用标志位";
CM_ SG_ 352 ESC_IGNOn "ESC_IGNOn";
CM_ SG_ 352 ESC_LSMabortfeedback "LSM降级反馈";
CM_ SG_ 352 ESC_VmcVseYawRateOffset "Offset to be applied on raw YawRate signal PSIP1";
CM_ SG_ 352 ESC_StabilityMarginQualifier "StabilityMargin validtion";
CM_ SG_ 352 ESC_VmcVseSasOffset "Steering wheel angle sensor offset (for signal SteeringWheelAngle)";
CM_ SG_ 352 ESC_StabilityMargin "StabilityMargin(用于能量回收滤波)";
CM_ SG_ 352 ESC_VmcVseYawRateAvlCpby "Availability and capability of raw yawrate signal and offset which has to be applied on raw yawrate signal PSIP2";
CM_ SG_ 352 ESC_VmcVseAxOvrGrnd "Vehicle longitudinal acceleration estimation (over Ground)
Availability of information is in signal VmcVseLgtPrimSrvAvlCpby";
CM_ SG_ 352 ESC_VmcVsevVeh "Vehicle velocity estimation
Availability of information is in signal VmcVseLgtPrimSrvAvlCpby";
CM_ SG_ 352 ESC_VmcVseSasAvlCpby "Availability and capability of raw steering wheel angle and offset which has to be applied on raw steering angle signal";
CM_ SG_ 352 ESC_VmcVseStandstill "Standstill information
Availability of information is in signal VmcVseLgtPrimSrvAvlCpby";
CM_ SG_ 352 ESC_VmcVSeSlope "Longitudinal slope estimation
Availability of information is in signal VmcVseLgtPrimSrvAvlCpby";
CM_ SG_ 352 ESC_VmcVseLgtPrimSrvAvlCpby "Availability and capability of longitudinal primary service for signals:, VmcVseAxOvrGrndCOG, VmcVseSlope, VmcVseStandstill, VmcVsevVeh";
CM_ SG_ 352 ESC_IB11_usedChannel "The brake system serves an information about the current used brake force channel from VMC";
CM_ SG_ 352 ESC_IB11_BrakeFxActual "The interface indicates actual longitudinal brake force which is handled by the brake actuator";
CM_ SG_ 352 ESC_IB11_BrakeFxCapability "The signal describes the capability of the brake system how the longitudinal brake force can be realized";
CM_ SG_ 352 ESC_IB11_BrakeFxAvailability "The signal describes the availability of the brake Fx interface which are realized by the hydraulic actuator The park brake actuator is not considered";
CM_ SG_ 352 ESC_IB12_BrkDiscTempStatus "The brake system provide information representing the thermal usage of the base brake foundation (brake disc)";
CM_ SG_ 352 ESC_IB11_DecStabAvail "The signal indicates whether a deceleration stabilization functions, mainly working in longitudinal direction, are available for a Fx request from VMC";
CM_ SG_ 352 ESC_IB11_isBrkFctReqFxBrkDomin "The signal describes whether the external requested brake force was overridden by a brake internal function which requested a higher longitudinal brake force";
CM_ SG_ 352 ESC_IB11_DecStabAvailForDriver "The signal indicates whether a deceleration stabilization functions, mainly working in longitudinal direction, are available also for the driver";
CM_ SG_ 352 ESC_IB11_DecStabActivity "The deceleration stabilization indicates whether all wheels or at least on wheel is in control";
CM_ SG_ 352 ESC_IB11_AccStabActivity "The signal indicates whether acceleration stabilization like TCS function is active (no DTC considered)";
CM_ SG_ 352 ESC_IB11_YawRateStabActivity "The interface indicates safety relevant activations of yawrate stabilization like VDC,  But not comfort functions like SideWindAssist";
CM_ SG_ 352 ESC_IB11_ParkBrakeCapability "The signal describes the capability of the park brake actuator how brake force can be realized";
CM_ SG_ 352 ESC_IB11_ParkBrakeAvailability "The interface describes the availablity information of the park brake actuators";
CM_ SG_ 352 ESC_IB12_BrkDiscTempStatusAvail "The brake systm provide an availability information for the thermal information of the base brake function (brake disc)";
CM_ SG_ 352 ESC_IB11_ParkBrakeState "The interface describe the state of the park brake actuators";
CM_ SG_ 352 ESC_IB11_ParkBrakeSupportRequest "With this signal the park brake actuator can request a park support from an external system eg gearbox";
CM_ SG_ 352 ESC_IB11_DriveMain2BackupState "State of the primary actuator for the EMC";
CM_ SG_ 352 ESC_IB11_StopMain2BackupState "State of the primary actuator for the EMC";
CM_ SG_ 352 ESC_IB11_isBrkFctReqPrkBrkDomin "The signal indicates whether the Driver interacts and pressed the brake pedal";
CM_ SG_ 352 ESC_IB12_isDrvPressingBrakePedal "The signal indicates whether the Driver interacts and pressed the brake pedal";
CM_ SG_ 352 ESC_IB12_DrvReqTarFxBrake "The signal describes the target requested brake force of the vehicle driver";
CM_ SG_ 352 ESC_IB12_DrvReqTarFxBrakeAvail "This signal describes the availability information of drivers brake pedal information";
CM_ SG_ 352 ESC_IB12_DrvPressBrakePedalAvail "This signal describes the availability information of drivers brake pedal information";
CM_ SG_ 352 ESC_IB12_DrvReqFxBrkDomAvail "This interface describes the signal qualifier information for Driver FxRequest dominant";
CM_ SG_ 352 ESC_IB12_isDrvReqFxBrakeDominant "The signal indicates that the vehicle driver request a higher longitudinal brake force than a driving or brake function is requesting";
CM_ SG_ 352 ESC_IB12_isDrvReqParkBrkDominant "The interface indicates whether the driver has exclusively access to the park brake The driver overrules requests from any other function";
CM_ SG_ 352 ESC_IB12_DrvReqParkBrakeAvail "The interface describes an availability for a signal whether the driver actuates the button auxiliary/park brake";
CM_ SG_ 352 ESC_IB12_DriverRequestParkBrake "The signal indicates whether the driver actuates the button auxiliary/park brake";
CM_ SG_ 352 ESC_VehicleSpeed2IB_Q "VehicleSpeed Qulifier to IB";
CM_ SG_ 352 ESC_pMC1_Q "The Qulifier of the current measured pressure in the primary circuit of the brake master cylinder";
CM_ SG_ 352 ESC_VehicleSpeed2IB "VehicleSpeed to IB and unit is m/s";
CM_ SG_ 352 ESC_IBpMC1 "The current measured pressure in the primary circuit of the brake master cylinder";
CM_ SG_ 352 ESC_IBAbsActive "Indicates whether ABS is currently active in the ESP";
CM_ SG_ 352 YRS_OriginalYawRate "Indicates Yaw Rate for Original value

 0x8CA1~0xFFFF:Invalid";
CM_ SG_ 352 YRS_OriginalLateralAcce "Indicates Lateral Acceleration for Original value

 0x0FA1~0xFFFF:Invalid";
CM_ SG_ 352 YRS_OriginalLongitAcce "Indicates Longitudinal Acceleration for Original value

 0x0FA1~0xFFFF:Invalid";
CM_ SG_ 352 YRS_OriginalLongitSensorState "Indicates Longitudinal Sensor Original State";
CM_ SG_ 352 YRS_OriginalLateralSensorState "Indicates Lateral Sensor Original State";
CM_ SG_ 352 YRS_OriginalYawRateSensorState "Indicates YawRate Sensor Original  State";
CM_ BO_ 336 "EPS Tx and its status related";
CM_ SG_ 336 EPS_TorsionBarTorque "Measired torsion bar torque";
CM_ SG_ 336 EPS_BasicElecSteerFailed "Basic Electrical Steering Failed
基本助力功能发生故障";
CM_ SG_ 336 EPS_ModeSetInhibitFb "EPS Mode Set Inhibit Feedback
EPS模式设置抑制反馈";
CM_ SG_ 336 EPS_ElecSteerModeSta "Electrical Steering Mode Status
电动助力模式状态";
CM_ SG_ 336 EPS_APA_Abortfeedback "Abortfeedback";
CM_ SG_ 336 EPS_APACtrlAvlbl "EPS control availble status";
CM_ SG_ 336 EPS_TorsionBarTorqueDir "Direction of measured torsion bar torque";
CM_ SG_ 336 EPS_TorsionBarTorqueValid "Validation bit of measured torsion bar torque";
CM_ SG_ 336 EPS_APA_SysStatus "EPS system available status";
CM_ SG_ 336 EPS_ElectPowerConsumption "EPS助力电流信号";
CM_ SG_ 336 EPS_1_AliveCnt "Message Alive Counter";
CM_ SG_ 336 EPS_1_Chksum "Message checksum";
CM_ BO_ 384 "SRS Tx and its status related";
CM_ SG_ 384 SRS_DrvSeatbeltBucklestatus "Signal from ACU for Driver seat belt warning indicator display on ICU";
CM_ SG_ 384 SRS_PassSeatbeltBucklestatus "Signal from ACU for Passenger seat belt warning indicator display on ICU";
CM_ SG_ 384 SRS_SeatbeltBucklestatus_RL "Signal from ACU for Rear Left seat belt warning indicator display on ICU";
CM_ SG_ 384 SRS_SeatbeltBucklestatus_RM "Signal from ACU for  Rear Middle seat belt warning indicator display on ICU";
CM_ SG_ 384 SRS_SeatbeltBucklestatus_RR "Signal from ACU for  Rear Right  seat belt warning indicator display on ICU";
CM_ SG_ 384 SRS_DrvSeatbeltBuckleValid "Signal from ACU for Driver seat belt warning  is Invalid";
CM_ SG_ 384 SRS_PassSeatbeltBuckleValid "Signal from ACU for Passenger seat belt warning  is Invalid";
CM_ SG_ 384 SRS_PassengerAirbagSta_Rsvr "Signal from ACU for PassengerAirbag inhibition switch status indicator display on ICU _Reserved";
CM_ SG_ 384 SRS_CrashOutputSts "Crash output status";
CM_ SG_ 384 SRS_PassSeatOccupantSensorSts "Signal from ACU for passager seat belt warning indicator display on ICU";
CM_ SG_ 384 SRS_AirbagWarningLampSts "Signal from ACU for Airbag Controll Unit Warning LED status displaying on ICU";
CM_ SG_ 384 SRS_1_AliveCnt "Message Alive Counter";
CM_ SG_ 384 SRS_1_Chksum "Message checksum";
CM_ BO_ 403 "CRRR Tx";
CM_ SG_ 403 CRRR_BSD_SetFb "LCA and BSD Set Feedback";
CM_ SG_ 403 CRRR_BSD_Warn_Right "BSD Lane Change Alarm Right Warning";
CM_ SG_ 403 CRRR_BSD_Warn_Left "BSD Lane Change Alarm Left Warning";
CM_ SG_ 403 CRRR_RCTA_Warn_Right "BSD Rear Cross Traffic Alarm Right Warning";
CM_ SG_ 403 CRRR_RCTA_SetFb "RCTA Set Feedback";
CM_ SG_ 403 CRRR_RCTA_Warn_Left "BSD Rear Cross Traffic Alarm Left Warning";
CM_ SG_ 403 CRRR_DOW_Warn_Right "DOW warning right";
CM_ SG_ 403 CRRR_RCW_Warning "RCW Warning";
CM_ SG_ 403 CRRR_RCTBDecelaration "RCTB  Decelaration Request value";
CM_ SG_ 403 CRRR_DOWSetFb "DOW Set Feedback";
CM_ SG_ 403 CRRR_RCTBReq "RCTB Request";
CM_ SG_ 403 CRRR_RCTB_BrkgVld "RCTB Brake request valid";
CM_ SG_ 403 CRRR_RCW_SetFb "RCW Set Feedback";
CM_ SG_ 403 CRRR_DOW_Warn_Left "DOW warning left";
CM_ SG_ 403 CRRR_RearCornerFailure "Rear Left/right Radar Failure";
CM_ SG_ 403 CRRR_RearCornerBlindness "Rear Left/right Radar Blindness";
CM_ SG_ 403 CRRR_FOVChangeSetFb "CR field of view mode change  set feedback";
CM_ SG_ 403 CRRR_A_AliveCnt "Message Alive Counter";
CM_ SG_ 403 CRRR_A_Chksum "Message Checksum";
CM_ SG_ 403 CRRR_ObjDirY_Left_00 "Position of left target object vehicle in y-direction 0 [m]";
CM_ SG_ 403 CRRR_ObjDirX_Left_00 "Position of left target object vehicle in x-direction 0 [m]";
CM_ SG_ 403 CRRR_ObjDirY_Left_01 "Position of left target object vehicle in y-direction 1 [m]";
CM_ SG_ 403 CRRR_ObjDirX_Left_01 "Position of left target object vehicle in x-direction 1 [m]";
CM_ SG_ 403 CRRR_ObjDirY_Right_00 "Position of right target object vehicle in y-direction 0 [m]";
CM_ SG_ 403 CRRR_ObjDirX_Right_00 "Position of right target object vehicle in x-direction 0 [m]";
CM_ SG_ 403 CRRR_ObjDirY_Right_01 "Position of right target object vehicle in y-direction  1 [m]";
CM_ SG_ 403 CRRR_ObjDirX_Right_01 "Position of right target object vehicle in x-direction  1 [m]";
CM_ SG_ 403 CRRR_ObjDirY_Rear_00 "Position of rear target object vehicle in y-direction  0 [m]";
CM_ SG_ 403 CRRR_ObjDirX_Rear_00 "Position of rear target object vehicle in x-direction  0 [m]";
CM_ SG_ 403 CRRR_ObjDirY_Rear_01 "Position of rear target object vehicle in y-direction 1 [m]";
CM_ SG_ 403 CRRR_ObjDirX_Rear_01 "Position of rear target object vehicle in x-direction 1 [m]";
CM_ BO_ 404 "CRFR Tx";
CM_ SG_ 404 CRFR_FCTB_AEBReqRight "Request of the AEB/EBA/AEB-VRU deceleration control for right";
CM_ SG_ 404 CRFR_FCTB_EBAReqRight "Request of the EBA only deceleration control for right";
CM_ SG_ 404 CRFR_FCTB_ABALevelRight "ABA level to the ESP HBA for right";
CM_ SG_ 404 CRFR_FCTB_ABAReqRight "Request of the ABA support from ESP for right";
CM_ SG_ 404 CRFR_FCTB_AEBTgtAxRight "Target deceleration value from AEB/EBA/AEB-VRU for right";
CM_ SG_ 404 CRFR_FCTB_ABPReqRight "Request of the Prefill to ESP for right";
CM_ SG_ 404 CRFR_FCTA_SetFb "FCTA Set Feedback";
CM_ SG_ 404 CRFR_FrontCornerFailure "Front Left/right Radar Failure";
CM_ SG_ 404 CRFR_FrontCornerBlindness "Front Left/right Radar Blindness";
CM_ SG_ 404 CRFR_FCTA_Warn_Left "acoustic Latent warningUsed with FCTA_Enable signal";
CM_ SG_ 404 CRFR_FCTA_Warn_Right "acoustic Latent warningUsed with FCTA_Enable signal";
CM_ SG_ 404 CRFR_A_AliveCnt "Message Alive Counter";
CM_ SG_ 404 CRFR_A_Chksum "Message Checksum";
CM_ SG_ 404 CRFR_ObjDirY_Left_00 "Position of left target object vehicle in y-direction 0 [m]";
CM_ SG_ 404 CRFR_ObjDirX_Left_00 "Position of left target object vehicle in x-direction 0 [m]";
CM_ SG_ 404 CRFR_ObjDirY_Left_01 "Position of left target object vehicle in y-direction 1 [m]";
CM_ SG_ 404 CRFR_ObjDirX_Left_01 "Position of left target object vehicle in x-direction 1 [m]";
CM_ SG_ 404 CRFR_ObjDirY_Right_00 "Position of right target object vehicle in y-direction 0 [m]";
CM_ SG_ 404 CRFR_ObjDirX_Right_00 "Position of right target object vehicle in x-direction 0 [m]";
CM_ SG_ 404 CRFR_ObjDirY_Right_01 "Position of right target object vehicle in y-direction  1 [m]";
CM_ SG_ 404 CRFR_ObjDirX_Right_01 "Position of right target object vehicle in x-direction  1 [m]";
CM_ SG_ 404 CRFR_ObjDirY_Front_00 "Position of front target object vehicle in y-direction  0 [m]";
CM_ SG_ 404 CRFR_ObjDirX_Front_00 "Position of front target object vehicle in x-direction  0 [m]";
CM_ SG_ 404 CRFR_ObjDirY_Front_01 "Position of front target object vehicle in y-direction 1 [m]";
CM_ SG_ 404 CRFR_ObjDirX_Front_01 "Position of front target object vehicle in x-direction 1 [m]";
CM_ BO_ 416 "FRM Tx and Target Distance related";
CM_ SG_ 416 FRM_A_AliveCnt "Message Alive Counter";
CM_ SG_ 416 FRM_A_Chksum "Message checksum";
CM_ SG_ 416 FRM_AEB_Req "Request of the AEB/EBA/AEB-VRU deceleration control";
CM_ SG_ 416 FRM_AEB_TgtAx "Target deceleration value from AEB/EBA/AEB-VRU";
CM_ SG_ 416 FRM_ABP_Req "Request of the Prefill to ESP";
CM_ BO_ 425 "FRM Tx and Target Distance&Type related";
CM_ SG_ 425 FRM_B_AliveCnt "Message Alive Counter";
CM_ SG_ 425 FRM_B_Chksum "Message checksum";
CM_ BO_ 373 "FCM Tx and Road Line related";
CM_ SG_ 373 FCM_A_AliveCnt "Message Alive Counter";
CM_ SG_ 373 FCM_A_Chksum "Message checksum";
CM_ BO_ 458 "VCU Tx and Drive State related";
CM_ SG_ 458 VCU_VhclActlGearPos "Vehicle Actual Gear Position
车辆实际档位";
CM_ SG_ 458 VCU_PTActlOprtMode "Power Train Actual Operating Mode
动力总成运行模式";
CM_ SG_ 458 VCU_LimpHomeSta "Vehicle Limp Home Status";
CM_ SG_ 458 VCU_BrkAPARqst "中断APA请求";
CM_ SG_ 458 VCU_VehActlDrvMode "Vehicle Actual Driving Mode
车辆实际驾驶模式";
CM_ SG_ 458 VCU_VhclActlGearPosV "Vehicle Actual Gear Position  Validity";
CM_ SG_ 458 VCU_BrkAPARqstV "中断APA请求有效性";
CM_ SG_ 458 VCU_GearShiftInhibited "Gear Shift Inhibited
换档禁止命令";
CM_ SG_ 458 VCU_PCUFailSta "Powertrain Control Unit Failure State
PCU失效状态";
CM_ SG_ 458 VCU_StrgRecupReqBrkLampOn "Strong Recuperation Reqest Brake Light On 强力回收时请求点亮制动指示灯";
CM_ SG_ 458 VCU_PeristalsisModeFb "Peristalsis Operation Mode Feedback
蠕动运行模式状态反馈";
CM_ SG_ 458 VCU_QECACC "When VCU detected Communication Fault  with ESC,FRM should be informed
当VCU检测到与ESC通信故障时，通知FRM";
CM_ SG_ 458 VCU_6_AliveCnt "Message Alive Counter";
CM_ SG_ 458 VCU_VhclPGearError "故障P档显示";
CM_ SG_ 458 VCU_12VBatLowVolSta "12V Battery Low Voltage Status
12V电池低压状态";
CM_ SG_ 458 VCU_6_Chksum "Message Checksum";
CM_ BO_ 565 "BCM Tx and Lamp Ajar Lock related";
CM_ SG_ 565 BCM_TurnLampSta_Left "Turn Left Lamp Status
左转向灯状态";
CM_ SG_ 565 BCM_TurnLampSta_Right "Turn Right Lamp Status
右转向灯状态";
CM_ SG_ 565 BCM_FogLampSta_Rear "Rear Fog Lamp Status
后雾灯状态";
CM_ SG_ 565 BCM_PosLampSta_Left "Left Position Lamp Status
左位置灯状态";
CM_ SG_ 565 BCM_PosLampSta_Right "Right Position Lamp Status
右位置灯状态";
CM_ SG_ 565 BCM_AjarSta_Hood "Hood Ajar Status
前舱盖微动开关状态";
CM_ SG_ 565 BCM_AjarSta_Trunk "Trunk Ajar Status
行李箱开关状态";
CM_ SG_ 565 BCM_DoorAjarSta_FL "Front Left Door Ajar Status
左前门开关状态";
CM_ SG_ 565 BCM_DoorAjarSta_FR "Front Right Door Ajar Status
右前门开关状态";
CM_ SG_ 565 BCM_DoorAjarSta_RL "Rear Left Door Ajar Status
左后门开关状态";
CM_ SG_ 565 BCM_DoorAjarSta_RR "Rear Right Door Ajar Status
右后门开关状态";
CM_ SG_ 565 BCM_ChrgAjarSta_Fast "Fast Charge Ajar Status
快充口盖子状态";
CM_ SG_ 565 BCM_ChrgAjarSta_Slow "Slow Charge Ajar Status
慢充口盖子状态";
CM_ SG_ 565 BCM_FuelAjarSta_Reserved "Fuel Ajar Status Reserved
燃油口盖子状态 预留";
CM_ SG_ 565 BCM_DoorsLockLatchOverHeat "Doors Lock Latch Over Heat
门闩过热";
CM_ SG_ 565 BCM_LightLeftOnRemind "Position Light Left On Indicator
位置灯未关提醒";
CM_ SG_ 565 BCM_ATWSLightOnReq_PT "Power Train Anti Theft Warning Status Light On Request
动力防盗指示灯点亮请求";
CM_ SG_ 565 BCM_ChildLockSta_RL "Child Lock Status RL
儿童锁状态左后";
CM_ SG_ 565 BCM_DoorLockSta_FL "Front Left Door Lock Status
左前门锁状态";
CM_ SG_ 565 BCM_DoorLockSta_FR_RL_RR "Front Right Door and Rear Left Door and Rear Right Door Lock Status
右前、左后、右后门锁状态";
CM_ SG_ 565 BCM_AjarStaV_Hood "Hood Ajar Status Validity
前舱盖微动开关状态有效性";
CM_ SG_ 565 BCM_HazardLampSts "Hazard Lamp Status
警示灯状态";
CM_ SG_ 565 BCM_TrunkSwSts_Drv "Driver Side Trunk Switch Status 
驾驶侧行李箱开关状态";
CM_ SG_ 565 BCM_HighBeamSta "High Beam Lamp Status
远光灯状态";
CM_ SG_ 565 BCM_LowBeamSta "Low Beam Lamp Status
近光灯状态";
CM_ SG_ 565 BCM_AutoLampStatus "Auto Lamp Function Status
自动大灯功能状态";
CM_ SG_ 565 BCM_FogLampSta_Front "Front Fog Lamp Status
前雾灯状态";
CM_ SG_ 565 BCM_TopLampModeFb "Top Lamp Mode Feedback(Relate to Door Ajar and Lock Status)
顶灯点亮模式反馈";
CM_ SG_ 565 BCM_DayRunLightReq "Day Running Light Request
日间行车灯请求";
CM_ SG_ 565 BCM_BrakeLampSta "Brake Lamp Status
制动灯状态";
CM_ SG_ 565 BCM_ReverseLampSta "ReverseLamp Status
倒车灯状态";
CM_ SG_ 565 BCM_NozzleHeatSta "Nozzle Heating Status
喷嘴加热状态";
CM_ SG_ 565 BCM_ChildLockSta_RR "Child Lock Status RL
儿童锁状态右后";
CM_ SG_ 565 BCM_PDU_Forbidden "PDU Forbidden
电源切换被禁止";
CM_ SG_ 565 BCM_BeamLampOpenWarn "Beam Lamp Open Warning
灯光打开提醒";
CM_ SG_ 565 BCM_BrakePadelSta "BCM Brake Pedal Status 
制动踏板状态_BCM采集并驱动制动灯";
CM_ SG_ 565 BCM_FuelLidSts "Fuel Lid Control Status reserved
燃油口状态";
CM_ SG_ 565 BCM_SSBSwSta "SSB开关状态信号";
CM_ SG_ 565 BCM_KeyInCarSta "钥匙在车内状态";
CM_ SG_ 565 BCM_BodyWarnSts "Body Warning Status";
CM_ SG_ 565 BCM_WiperCtrl_Rear "Rear Wiper Control
后雨刮控制状态";
CM_ SG_ 565 BCM_HeavyRainInd "Heavy Rain Indication";
CM_ SG_ 565 BCM_WiperCtrl_Front "Front Wiper Control
前雨刮控制状态";
CM_ SG_ 565 BCM_1_AliveCnt "Message Alive Counter";
CM_ SG_ 565 BCM_PTGUnlockCmd "Power Tailgate Unlock Command";
CM_ SG_ 565 BCM_1_Chksum "Message checksum";
CM_ BO_ 601 "SCM Tx and Steering Wheel Switch related";
CM_ SG_ 601 SCM_AutoLightSW_StsInvalid "Indicating the SCM_SW_AutoLight is valid or invalid
提示自动灯开关状态信号是否有效";
CM_ SG_ 601 SCM_AutoLightSW_Sts "Signal from SCM to Indicate auto light swith Switch status
提示自动灯开关状态";
CM_ SG_ 601 SCM_FrontWasherSW_StsInvalid "Indicating the SCM_FW_WashSW_Sts is valid or invalid
SCM指示前洗涤器开关状态信号是否有效";
CM_ SG_ 601 SCM_FrontWasherSW_Sts "Signal from SCM to indicate the front window washer Switch status
SCM指示前洗涤器开关状态";
CM_ SG_ 601 SCM_LowBeamSW_StsInvalid "Indicating the SCM_SW_LowBeam is valid or invalid
SCM指示近光灯开关信号是否有效";
CM_ SG_ 601 SCM_LowBeamSW_Sts "Signal from SCM to Indicate low beam swith Switch status
SCM指示近光灯开关状态";
CM_ SG_ 601 SCM_HighBeamSW_StsInvalid "Indicating the SCM_SW_HighBeam is valid or invalid
SCM指示远光灯开关状态信号是否有效";
CM_ SG_ 601 SCM_HighBeamSW_Sts "Signal from SCM to Indicate high beam swith Switch status
SCM指示远光灯开关状态";
CM_ SG_ 601 SCM_PositionLightSW_StsInvalid "Indicating the SCM_SW_PositionLight is valid or invalid
提示位置灯开关状态信号是否有效";
CM_ SG_ 601 SCM_PositionLightSW_Sts "Signal from SCM to Indicate position light swith Switch status
提示位置灯开关状态";
CM_ SG_ 601 SCM_FlashLightSW_StsInvalid "Indicating the SCM_SW_FlashLightSW_Sts is valid or invalid
提示超车灯开关状态信号是否有效";
CM_ SG_ 601 SCM_FlashLightSW_Sts "Signal from SCM to Indicate flash light swith Switch status
SCM提示超车灯开关状态";
CM_ SG_ 601 SCM_TurnLightLeverSta "Turn Light Lever Status
转向灯拨杆状态";
CM_ SG_ 601 SCM_TripSW_Sts "Trip to page up/down
仪表页面切换";
CM_ SG_ 601 SCM_RearFogLightSW_StsInvalid "Indicating the SCM_SW_RearFogLight is valid or invalid
提示后雾灯开关状态信号是否有效";
CM_ SG_ 601 SCM_RearFogLightSW_Sts "Signal from SCM to Indicate rear fog light swith Switch status
提示后雾灯开关状态";
CM_ SG_ 601 SCM_FrontFogLightSW_StsInvalid "Indicating the SCM_SW_FrontFogLight is valid or invalid
提示前雾灯状态信号是否有效";
CM_ SG_ 601 SCM_FrontFogLightSW_Sts "Signal from SCM to Indicate front fog light swith Switch status
指示前雾灯开关状态";
CM_ SG_ 601 SCM_RearWasherSwStsV "Rear Washer Switch Status Validity";
CM_ SG_ 601 SCM_RearWasherSwSts "Rear Washer Switch Status";
CM_ SG_ 601 SCM_FrontWipingIntervalSW_Sts "The signal indicates the stage preselection of the wiper interval function
该信号提示雨刮间歇灵敏度";
CM_ SG_ 601 SCM_FrontWipingMode "Signal from SCM to request front wiping mode
SCM提示前雨刮功能模式";
CM_ SG_ 601 SCM_RearWipingMode "Signal from SCM to request Rear wiping mode
指示后雨刮模式";
CM_ SG_ 601 SCM_2_AliveCnt "Message Alive Counter";
CM_ SG_ 601 SCM_2_Chksum "Message checksum";
CM_ BO_ 622 "HU Tx and total odometer related";
CM_ SG_ 622 HU_ICU_ICUTotalOdometer "The total odometer displayed in ICU";
CM_ SG_ 622 HU_ICU_ICUTripAOdometer "The total odometer displayed in ICU";
CM_ SG_ 622 HU_ICU_ICUTripBOdometer "The total odometer displayed in ICU";
CM_ BO_ 753 "AC Tx and Heating/Cooling related";
CM_ SG_ 753 AC_EnvirTempV "Environment Temperature Validity
环境温度有效性";
CM_ SG_ 753 AC_BatPumpFailSta "Battery pump fail state
电池水泵故障信号";
CM_ SG_ 753 AC_HVHFailSta_HVAC "High Voltage Heating for HVAC Failure Status
空调用高压加热失效状态";
CM_ SG_ 753 AC_HVHActlOprtMode_HVAC "High Voltage Heating Operating Mode for HVAC Actual 
空调用高压加热运行模式";
CM_ SG_ 753 AC_FailSta "Air Conditioning Failure State
空调失效状态";
CM_ SG_ 753 AC_ActlOprtMode "Air Conditioning Actual Operating Mode
空调实际运行模式";
CM_ SG_ 753 AC_EnvirTemp "Environment Temperature
环境温度";
CM_ SG_ 753 AC_HVHActlPwr_HVAC "High Voltage Heating for HVAC Actual Input Power
空调用高压加热实际输入功率";
CM_ SG_ 753 AC_HVHDeviceInternTemp_HVAC "High Voltage Heating for HVAC Device Internal Temperature
空调用高压加热内部温度";
CM_ SG_ 753 AC_RefrgHiPressure "Refrigerant HiPressure
冷媒高压侧压力";
CM_ SG_ 753 AC_RefrgHiPressureV "Refrigerant HiPressure Validity
冷媒高压侧压力有效性";
CM_ SG_ 753 AC_ActTotalPower "Actual Total Power from HV DC";
CM_ SG_ 753 AC_2_AliveCnt "Message Alive Counter";
CM_ SG_ 753 AC_2_Chksum "Message Checksum";
CM_ BO_ 162 "EPS Tx and SteerWheelAngle related";
CM_ SG_ 162 EPS_SteerWheelAngle "steering wheel angle";
CM_ SG_ 162 EPS_SteerWheelAngleValid "The validation of steering wheel angle";
CM_ SG_ 162 EPS_RotSpeed "Steering wheel rotational speed
方向盘转角速度";
CM_ SG_ 162 EPS_2_AliveCnt "Message Alive Counter";
CM_ SG_ 162 EPS_SteerWheelAngleCalibrated "SteerWheelAngle is calibrated or not";
CM_ SG_ 162 EPS_SteerWheelAngleFailure "SteerWheelAngle is failed or not";
CM_ SG_ 162 EPS_ElectricPowerSta "EPS Electric Power Status";
CM_ SG_ 162 EPS_2_Chksum "Message checksum";
CM_ BO_ 163 "EPS Tx and Lateral related";
CM_ SG_ 163 EPS_MotTq "Actual torque  output at  EPS motor";
CM_ SG_ 163 EPS_LatDrvLvl12SrvAvl "Lateral level 12 driving service availability";
CM_ SG_ 163 EPS_LatMCHptcWrnSrvAvl "Describes the availability of the Haptic Warning Service, availability to respond to a haptic request";
CM_ SG_ 163 EPS_LatMCSteerTqActive "Lateral Motion Control feedback signal for the Steering Torque service activation";
CM_ SG_ 163 EPS_PSCMIntRPCMaxTrq "Maximum internally allowed RPC torque for Level 2 (safety limit)(TBT level)";
CM_ SG_ 163 EPS_TorsionBarTorqueQF "Indicates the validity of Torsion Bar Torque sensor measurement";
CM_ SG_ 163 EPS_LatMCHptcWrnActive "Lateral Motion Control feedback signal for the Haptic Warning service activation";
CM_ SG_ 163 EPS_PSCMIntRPCMinTrq "Minimum internally allowed RPC torque for Level 2 (safety limit)(TBT level)";
CM_ SG_ 163 EPS_3_AliveCnt "Message Alive Counter";
CM_ SG_ 163 EPS_3_Chksum "Message checksum";
CM_ BO_ 668 "IPM Tx";
CM_ SG_ 668 IPM_RearFogLampStatus "Rear Fog Light Statue
后雾灯运行状态";
CM_ SG_ 668 IPM_FoldingMirrorPosStatus "Folding Mirror Status 
后视镜折叠/展开状态";
CM_ SG_ 668 IPM_DRLStatus "daytime running lights Status
日间行车灯运行状态";
CM_ BO_ 389 "APA Tx";
CM_ SG_ 389 APA_SafeDrvrHandoverReq "驾驶员请求接管标志位";
CM_ SG_ 389 APA_A_AliveCnt "Message Alive Counter";
CM_ SG_ 389 APA_A_Chksum "Message Checksum";
CM_ SG_ 389 APA_ReqReleaseEPB "APA release EPB request";
CM_ SG_ 389 APA_ReqReleaseEPBV "APA release EPB request validity";
CM_ SG_ 389 APA_LSMSubMTReq "实现动态功能";
CM_ SG_ 389 APA_LSMSubMTLevel "实现泊车功能类型";
CM_ SG_ 389 APA_LSMSubMTLong "实现纵向控制制动类型";
CM_ SG_ 389 APA_LSMBrakeEmgcyPrep "是否需要预制动消除制动系统间隙";
CM_ SG_ 389 APA_DrvPresenceExt "驾驶员是否在车上";
CM_ SG_ 389 APA_LSMComfBrakeReq "舒适制动要求";
CM_ SG_ 389 APA_EPS_SetSteeringWheelAng "请求转角";
CM_ SG_ 389 APA_DrvReq "驾驶员操作提示信息";
CM_ SG_ 389 APA_RPA_status "RPA system status";
CM_ SG_ 389 APA_EPS_Control_Request "EPS控制请求和控制激活指示";
CM_ SG_ 389 APA_Status "自动泊车功能状态";
CM_ SG_ 389 APA_RPA_AvailSts "RPA可用状态";
CM_ BO_ 480 "APA Tx";
CM_ SG_ 480 APA_B_AliveCnt "Message Alive Counter";
CM_ SG_ 480 APA_B_Chksum "Message Checksum";
CM_ BO_ 448 "ADC Tx";
CM_ SG_ 448 ADC_TextInfoACCTJA "Textinfo for Driver which is displayed in Dashboard for ADC";
CM_ SG_ 448 ADC_A_AliveCnt "Message Alive Counter";
CM_ SG_ 448 ADC_A_Chksum "Message Checksum";
CM_ SG_ 448 ADC_Acc_MotorTorqReqValue "The signal specifies the VLC target motor torque at motor output side above driver requested torque";
CM_ SG_ 448 ADC_AccTrqReqEna "Enable flag for EMS for realization of target torque AccTrqReq";
CM_ SG_ 448 ADC_Acc_TgtAxReq "Whether the signal ACC_TgtAx should be considered or not";
CM_ SG_ 448 ADC_Acc_Mode "The status of the ACC control unit
The ACC mode should be contained in every message sent by ACC";
CM_ SG_ 448 ADC_Acc_TgtAx "ACC target deceleration";
CM_ SG_ 448 ADC_AccReq_DriveOff "ACC request the VLC to drive off";
CM_ SG_ 448 ADC_AccReq_Standstill "ACC request the VLC to decelerate to stop";
CM_ SG_ 448 ADC_SteerTqReq "LKA or TJA or ICA torque request  to EPS";
CM_ SG_ 448 ADC_SteerTqReqActive "LKA or TJA or ICA Torque request staus to EPS";
CM_ SG_ 448 ADC_ActDrvAsstSts "TJA or ICA Actual Drive Assistant Status";
CM_ SG_ 448 ADC_DA_EPSModeReq "ADC DA EPS mode request";
CM_ BO_ 309 "ADC Tx";
CM_ SG_ 309 ADC_D_AliveCnt1 "Message alive counter";
CM_ SG_ 309 ADC_D_Chksum1 "Message Checksum
Calculated data range starts from bit 0 to bit 55.";
BA_DEF_ BO_  "GenMsgSendType" ENUM  "Cyclic","Event","NotUsed","CE","CA","NotUsed","NotUsed","IfActive","NoMsgSendType";
BA_DEF_ BO_  "GenMsgCycleTime" INT 0 0;
BA_DEF_ SG_  "GenSigSendType" ENUM  "Cyclic","OnWrite","OnWriteWithRepetition","OnChange","OnChangeWithRepetition","IfActive","IfActiveWithRepetition","NoSigSendType","OnChangeAndIfActive","OnChangeAndIfActiveWithRepetition";
BA_DEF_ SG_  "GenSigStartValue" INT 0 0;
BA_DEF_ BO_  "GenMsgCycleTimeFast" INT 0 0;
BA_DEF_ BO_  "GenMsgNrOfRepetition" INT 0 0;
BA_DEF_ BO_  "CANFD_BRS" ENUM  "0","1";
BA_DEF_ BO_  "VFrameFormat" ENUM  "StandardCAN","ExtendedCAN","reserved","reserved","reserved","reserved","reserved","reserved","reserved","reserved","reserved","reserved","reserved","reserved","StandardCAN_FD","ExtendedCAN_FD";
BA_DEF_ BO_  "vFrameFormat" ENUM  "StandardCAN","ExtendedCAN","StandardCAN_FD","ExtendedCAN_FD";
BA_DEF_ BO_  "MsgType" ENUM  "Normal","NM","Diag";
BA_DEF_ SG_  "GenSigInvalidValue" INT 0 0;
BA_DEF_DEF_  "GenMsgSendType" "Cyclic";
BA_DEF_DEF_  "GenMsgCycleTime" 0;
BA_DEF_DEF_  "GenSigSendType" "Cyclic";
BA_DEF_DEF_  "GenSigStartValue" 0;
BA_DEF_DEF_  "GenMsgCycleTimeFast" 0;
BA_DEF_DEF_  "GenMsgNrOfRepetition" 0;
BA_DEF_DEF_  "CANFD_BRS" "1";
BA_DEF_DEF_  "VFrameFormat" "StandardCAN_FD";
BA_DEF_DEF_  "vFrameFormat" "StandardCAN_FD";
BA_DEF_DEF_  "MsgType" "Normal";
BA_DEF_DEF_  "GenSigInvalidValue" 0;
BA_ "GenMsgCycleTime" BO_ 464 100;
BA_ "GenMsgCycleTime" BO_ 130 20;
BA_ "GenMsgCycleTime" BO_ 388 20;
BA_ "GenMsgCycleTime" BO_ 115 10;
BA_ "GenMsgCycleTime" BO_ 116 20;
BA_ "GenMsgCycleTime" BO_ 274 20;
BA_ "GenMsgNrOfRepetition" BO_ 281 5;
BA_ "GenMsgCycleTimeFast" BO_ 281 20;
BA_ "GenMsgCycleTime" BO_ 281 50;
BA_ "GenMsgSendType" BO_ 281 3;
BA_ "VFrameFormat" BO_ 281 0;
BA_ "GenMsgCycleTime" BO_ 288 20;
BA_ "GenMsgCycleTime" BO_ 352 10;
BA_ "GenMsgCycleTime" BO_ 336 20;
BA_ "GenMsgNrOfRepetition" BO_ 384 150;
BA_ "GenMsgCycleTimeFast" BO_ 384 20;
BA_ "GenMsgCycleTime" BO_ 384 50;
BA_ "GenMsgSendType" BO_ 384 4;
BA_ "GenMsgCycleTime" BO_ 403 20;
BA_ "GenMsgCycleTime" BO_ 404 20;
BA_ "GenMsgCycleTime" BO_ 416 20;
BA_ "GenMsgCycleTime" BO_ 425 20;
BA_ "GenMsgCycleTime" BO_ 373 100;
BA_ "VFrameFormat" BO_ 458 0;
BA_ "GenMsgCycleTime" BO_ 458 20;
BA_ "GenMsgNrOfRepetition" BO_ 565 5;
BA_ "GenMsgCycleTimeFast" BO_ 565 20;
BA_ "GenMsgCycleTime" BO_ 565 50;
BA_ "GenMsgSendType" BO_ 565 3;
BA_ "GenMsgCycleTime" BO_ 601 100;
BA_ "GenMsgCycleTime" BO_ 622 100;
BA_ "GenMsgCycleTime" BO_ 753 100;
BA_ "GenMsgCycleTime" BO_ 162 10;
BA_ "GenMsgCycleTime" BO_ 163 10;
BA_ "GenMsgCycleTime" BO_ 668 100;
BA_ "GenMsgCycleTime" BO_ 389 20;
BA_ "GenMsgCycleTime" BO_ 480 50;
BA_ "GenMsgCycleTime" BO_ 448 20;
BA_ "GenMsgCycleTime" BO_ 309 100;
BA_ "GenSigSendType" SG_ 3221225472 CRRL_KeepAwakePwrMode 1;
BA_ "GenSigSendType" SG_ 3221225472 CRRL_KeepAwakeReasDiag 1;
BA_ "GenSigSendType" SG_ 3221225472 CRRL_KeepAwakeReasLocalFunReq 1;
BA_ "GenSigSendType" SG_ 3221225472 CRRL_KeepAwakeSta 1;
BA_ "GenSigSendType" SG_ 3221225472 CRRR_WakeupReas 1;
BA_ "GenSigSendType" SG_ 3221225472 CRRR_KeepAwakePwrMode 1;
BA_ "GenSigSendType" SG_ 3221225472 CRRR_KeepAwakeReasDiag 1;
BA_ "GenSigSendType" SG_ 3221225472 CRRR_KeepAwakeReasLocalFunReq 1;
BA_ "GenSigSendType" SG_ 3221225472 CRRR_KeepAwakeSta 1;
BA_ "GenSigSendType" SG_ 3221225472 AVP_WakeupReas 1;
BA_ "GenSigSendType" SG_ 3221225472 AVP_KeepAwakePwrMode 1;
BA_ "GenSigSendType" SG_ 3221225472 AVP_KeepAwakeReasDiag 1;
BA_ "GenSigSendType" SG_ 3221225472 AVP_KeepAwakeReasLocalFunReq 1;
BA_ "GenSigSendType" SG_ 3221225472 AVP_KeepAwakeSta 1;
BA_ "GenSigSendType" SG_ 3221225472 Diag_PhyReq_FRM_Data0 1;
BA_ "GenSigSendType" SG_ 3221225472 Diag_PhyReq_FRM_Data1 1;
BA_ "GenSigSendType" SG_ 3221225472 Diag_PhyReq_FRM_Data2 1;
BA_ "GenSigSendType" SG_ 3221225472 Diag_PhyReq_FRM_Data3 1;
BA_ "GenSigSendType" SG_ 3221225472 Diag_PhyReq_FRM_Data4 1;
BA_ "GenSigSendType" SG_ 3221225472 Diag_PhyReq_FRM_Data5 1;
BA_ "GenSigSendType" SG_ 3221225472 Diag_PhyReq_FRM_Data6 1;
BA_ "GenSigSendType" SG_ 3221225472 Diag_PhyReq_FRM_Data7 1;
BA_ "GenSigSendType" SG_ 3221225472 Diag_PhyReq_FCM_Data0 1;
BA_ "GenSigSendType" SG_ 3221225472 Diag_PhyReq_FCM_Data1 1;
BA_ "GenSigSendType" SG_ 3221225472 Diag_PhyReq_FCM_Data2 1;
BA_ "GenSigSendType" SG_ 3221225472 Diag_PhyReq_FCM_Data3 1;
BA_ "GenSigSendType" SG_ 3221225472 Diag_PhyReq_FCM_Data4 1;
BA_ "GenSigSendType" SG_ 3221225472 Diag_PhyReq_FCM_Data5 1;
BA_ "GenSigSendType" SG_ 3221225472 Diag_PhyReq_FCM_Data6 1;
BA_ "GenSigSendType" SG_ 3221225472 Diag_PhyReq_FCM_Data7 1;
BA_ "GenSigSendType" SG_ 3221225472 Diag_PhyReq_APA_Data0 1;
BA_ "GenSigSendType" SG_ 3221225472 Diag_PhyReq_APA_Data1 1;
BA_ "GenSigSendType" SG_ 3221225472 Diag_PhyReq_APA_Data2 1;
BA_ "GenSigSendType" SG_ 3221225472 Diag_PhyReq_APA_Data3 1;
BA_ "GenSigSendType" SG_ 3221225472 Diag_PhyReq_APA_Data4 1;
BA_ "GenSigSendType" SG_ 3221225472 Diag_PhyReq_APA_Data5 1;
BA_ "GenSigSendType" SG_ 3221225472 Diag_PhyReq_APA_Data6 1;
BA_ "GenSigSendType" SG_ 3221225472 Diag_PhyReq_APA_Data7 1;
BA_ "GenSigSendType" SG_ 3221225472 Diag_PhyReq_AVP_Data0 1;
BA_ "GenSigSendType" SG_ 3221225472 Diag_PhyReq_AVP_Data1 1;
BA_ "GenSigSendType" SG_ 3221225472 Diag_PhyReq_AVP_Data2 1;
BA_ "GenSigSendType" SG_ 3221225472 Diag_PhyReq_AVP_Data3 1;
BA_ "GenSigSendType" SG_ 3221225472 Diag_PhyReq_AVP_Data4 1;
BA_ "GenSigSendType" SG_ 3221225472 Diag_PhyReq_AVP_Data5 1;
BA_ "GenSigSendType" SG_ 3221225472 Diag_PhyReq_AVP_Data6 1;
BA_ "GenSigSendType" SG_ 3221225472 Diag_PhyReq_AVP_Data7 1;
BA_ "GenSigSendType" SG_ 3221225472 Diag_PhyReq_ADC_Data0 1;
BA_ "GenSigSendType" SG_ 3221225472 Diag_PhyReq_ADC_Data1 1;
BA_ "GenSigSendType" SG_ 3221225472 Diag_PhyReq_ADC_Data2 1;
BA_ "GenSigSendType" SG_ 3221225472 Diag_PhyReq_ADC_Data3 1;
BA_ "GenSigSendType" SG_ 3221225472 Diag_PhyReq_ADC_Data4 1;
BA_ "GenSigSendType" SG_ 3221225472 Diag_PhyReq_ADC_Data5 1;
BA_ "GenSigSendType" SG_ 3221225472 Diag_PhyReq_ADC_Data6 1;
BA_ "GenSigSendType" SG_ 3221225472 Diag_PhyReq_ADC_Data7 1;
BA_ "GenSigSendType" SG_ 3221225472 Diag_PhyReq_CRFL_Data0 1;
BA_ "GenSigSendType" SG_ 3221225472 Diag_PhyReq_CRFL_Data1 1;
BA_ "GenSigSendType" SG_ 3221225472 Diag_PhyReq_CRFL_Data2 1;
BA_ "GenSigSendType" SG_ 3221225472 Diag_PhyReq_CRFL_Data3 1;
BA_ "GenSigSendType" SG_ 3221225472 Diag_PhyReq_CRFL_Data4 1;
BA_ "GenSigSendType" SG_ 3221225472 Diag_PhyReq_CRFL_Data5 1;
BA_ "GenSigSendType" SG_ 3221225472 Diag_PhyReq_CRFL_Data6 1;
BA_ "GenSigSendType" SG_ 3221225472 Diag_PhyReq_CRFL_Data7 1;
BA_ "GenSigSendType" SG_ 3221225472 Diag_PhyReq_CRFR_Data0 1;
BA_ "GenSigSendType" SG_ 3221225472 Diag_PhyReq_CRFR_Data1 1;
BA_ "GenSigSendType" SG_ 3221225472 Diag_PhyReq_CRFR_Data2 1;
BA_ "GenSigSendType" SG_ 3221225472 Diag_PhyReq_CRFR_Data3 1;
BA_ "GenSigSendType" SG_ 3221225472 Diag_PhyReq_CRFR_Data4 1;
BA_ "GenSigSendType" SG_ 3221225472 Diag_PhyReq_CRFR_Data5 1;
BA_ "GenSigSendType" SG_ 3221225472 Diag_PhyReq_CRFR_Data6 1;
BA_ "GenSigSendType" SG_ 3221225472 Diag_PhyReq_CRFR_Data7 1;
BA_ "GenSigSendType" SG_ 3221225472 Diag_PhyReq_CRRL_Data0 1;
BA_ "GenSigSendType" SG_ 3221225472 Diag_PhyReq_CRRL_Data1 1;
BA_ "GenSigSendType" SG_ 3221225472 Diag_PhyReq_CRRL_Data2 1;
BA_ "GenSigSendType" SG_ 3221225472 Diag_PhyReq_CRRL_Data3 1;
BA_ "GenSigSendType" SG_ 3221225472 Diag_PhyReq_CRRL_Data4 1;
BA_ "GenSigSendType" SG_ 3221225472 Diag_PhyReq_CRRL_Data5 1;
BA_ "GenSigSendType" SG_ 3221225472 Diag_PhyReq_CRRL_Data6 1;
BA_ "GenSigSendType" SG_ 3221225472 Diag_PhyReq_CRRL_Data7 1;
BA_ "GenSigSendType" SG_ 3221225472 Diag_PhyReq_CRRR_Data0 1;
BA_ "GenSigSendType" SG_ 3221225472 Diag_PhyReq_CRRR_Data1 1;
BA_ "GenSigSendType" SG_ 3221225472 Diag_PhyReq_CRRR_Data2 1;
BA_ "GenSigSendType" SG_ 3221225472 Diag_PhyReq_CRRR_Data3 1;
BA_ "GenSigSendType" SG_ 3221225472 Diag_PhyReq_CRRR_Data4 1;
BA_ "GenSigSendType" SG_ 3221225472 Diag_PhyReq_CRRR_Data5 1;
BA_ "GenSigSendType" SG_ 3221225472 Diag_PhyReq_CRRR_Data6 1;
BA_ "GenSigSendType" SG_ 3221225472 Diag_PhyReq_CRRR_Data7 1;
BA_ "GenSigSendType" SG_ 3221225472 Diag_Resp_FRM_Data0 1;
BA_ "GenSigSendType" SG_ 3221225472 Diag_Resp_FRM_Data1 1;
BA_ "GenSigSendType" SG_ 3221225472 Diag_Resp_FRM_Data2 1;
BA_ "GenSigSendType" SG_ 3221225472 Diag_Resp_FRM_Data3 1;
BA_ "GenSigSendType" SG_ 3221225472 Diag_Resp_FRM_Data4 1;
BA_ "GenSigSendType" SG_ 3221225472 Diag_Resp_FRM_Data5 1;
BA_ "GenSigSendType" SG_ 3221225472 Diag_Resp_FRM_Data6 1;
BA_ "GenSigSendType" SG_ 3221225472 Diag_Resp_FRM_Data7 1;
BA_ "GenSigSendType" SG_ 3221225472 Diag_Resp_FCM_Data0 1;
BA_ "GenSigSendType" SG_ 3221225472 Diag_Resp_FCM_Data1 1;
BA_ "GenSigSendType" SG_ 3221225472 Diag_Resp_FCM_Data2 1;
BA_ "GenSigSendType" SG_ 3221225472 Diag_Resp_FCM_Data3 1;
BA_ "GenSigSendType" SG_ 3221225472 Diag_Resp_FCM_Data4 1;
BA_ "GenSigSendType" SG_ 3221225472 Diag_Resp_FCM_Data5 1;
BA_ "GenSigSendType" SG_ 3221225472 Diag_Resp_FCM_Data6 1;
BA_ "GenSigSendType" SG_ 3221225472 Diag_Resp_FCM_Data7 1;
BA_ "GenSigSendType" SG_ 3221225472 Diag_Resp_APA_Data0 1;
BA_ "GenSigSendType" SG_ 3221225472 Diag_Resp_APA_Data1 1;
BA_ "GenSigSendType" SG_ 3221225472 Diag_Resp_APA_Data2 1;
BA_ "GenSigSendType" SG_ 3221225472 Diag_Resp_APA_Data3 1;
BA_ "GenSigSendType" SG_ 3221225472 Diag_Resp_APA_Data4 1;
BA_ "GenSigSendType" SG_ 3221225472 Diag_Resp_APA_Data5 1;
BA_ "GenSigSendType" SG_ 3221225472 Diag_Resp_APA_Data6 1;
BA_ "GenSigSendType" SG_ 3221225472 Diag_Resp_APA_Data7 1;
BA_ "GenSigSendType" SG_ 3221225472 Diag_Resp_ADC_Data0 1;
BA_ "GenSigSendType" SG_ 3221225472 Diag_Resp_ADC_Data1 1;
BA_ "GenSigSendType" SG_ 3221225472 Diag_Resp_ADC_Data2 1;
BA_ "GenSigSendType" SG_ 3221225472 Diag_Resp_ADC_Data3 1;
BA_ "GenSigSendType" SG_ 3221225472 Diag_Resp_ADC_Data4 1;
BA_ "GenSigSendType" SG_ 3221225472 Diag_Resp_ADC_Data5 1;
BA_ "GenSigSendType" SG_ 3221225472 Diag_Resp_ADC_Data6 1;
BA_ "GenSigSendType" SG_ 3221225472 Diag_Resp_ADC_Data7 1;
BA_ "GenSigSendType" SG_ 3221225472 Diag_Resp_CRFL_Data0 1;
BA_ "GenSigSendType" SG_ 3221225472 Diag_Resp_CRFL_Data1 1;
BA_ "GenSigSendType" SG_ 3221225472 Diag_Resp_CRFL_Data2 1;
BA_ "GenSigSendType" SG_ 3221225472 Diag_Resp_CRFL_Data3 1;
BA_ "GenSigSendType" SG_ 3221225472 Diag_Resp_CRFL_Data4 1;
BA_ "GenSigSendType" SG_ 3221225472 Diag_Resp_CRFL_Data5 1;
BA_ "GenSigSendType" SG_ 3221225472 Diag_Resp_CRFL_Data6 1;
BA_ "GenSigSendType" SG_ 3221225472 Diag_Resp_CRFL_Data7 1;
BA_ "GenSigSendType" SG_ 3221225472 Diag_Resp_CRFR_Data0 1;
BA_ "GenSigSendType" SG_ 3221225472 Diag_Resp_CRFR_Data1 1;
BA_ "GenSigSendType" SG_ 3221225472 Diag_Resp_CRFR_Data2 1;
BA_ "GenSigSendType" SG_ 3221225472 Diag_Resp_CRFR_Data3 1;
BA_ "GenSigSendType" SG_ 3221225472 Diag_Resp_CRFR_Data4 1;
BA_ "GenSigSendType" SG_ 3221225472 Diag_Resp_CRFR_Data5 1;
BA_ "GenSigSendType" SG_ 3221225472 Diag_Resp_CRFR_Data6 1;
BA_ "GenSigSendType" SG_ 3221225472 Diag_Resp_CRFR_Data7 1;
BA_ "GenSigSendType" SG_ 3221225472 Diag_Resp_CRRL_Data0 1;
BA_ "GenSigSendType" SG_ 3221225472 Diag_Resp_CRRL_Data1 1;
BA_ "GenSigSendType" SG_ 3221225472 Diag_Resp_CRRL_Data2 1;
BA_ "GenSigSendType" SG_ 3221225472 Diag_Resp_CRRL_Data3 1;
BA_ "GenSigSendType" SG_ 3221225472 Diag_Resp_CRRL_Data4 1;
BA_ "GenSigSendType" SG_ 3221225472 Diag_Resp_CRRL_Data5 1;
BA_ "GenSigSendType" SG_ 3221225472 Diag_Resp_CRRL_Data6 1;
BA_ "GenSigSendType" SG_ 3221225472 Diag_Resp_CRRL_Data7 1;
BA_ "GenSigSendType" SG_ 3221225472 Diag_Resp_CRRR_Data0 1;
BA_ "GenSigSendType" SG_ 3221225472 Diag_Resp_CRRR_Data1 1;
BA_ "GenSigSendType" SG_ 3221225472 Diag_Resp_CRRR_Data2 1;
BA_ "GenSigSendType" SG_ 3221225472 Diag_Resp_CRRR_Data3 1;
BA_ "GenSigSendType" SG_ 3221225472 Diag_Resp_CRRR_Data4 1;
BA_ "GenSigSendType" SG_ 3221225472 Diag_Resp_CRRR_Data5 1;
BA_ "GenSigSendType" SG_ 3221225472 Diag_Resp_CRRR_Data6 1;
BA_ "GenSigSendType" SG_ 3221225472 Diag_Resp_CRRR_Data7 1;
BA_ "GenSigSendType" SG_ 3221225472 Diag_Resp_AVP_Data0 1;
BA_ "GenSigSendType" SG_ 3221225472 Diag_Resp_AVP_Data1 1;
BA_ "GenSigSendType" SG_ 3221225472 Diag_Resp_AVP_Data2 1;
BA_ "GenSigSendType" SG_ 3221225472 Diag_Resp_AVP_Data3 1;
BA_ "GenSigSendType" SG_ 3221225472 Diag_Resp_AVP_Data4 1;
BA_ "GenSigSendType" SG_ 3221225472 Diag_Resp_AVP_Data5 1;
BA_ "GenSigSendType" SG_ 3221225472 Diag_Resp_AVP_Data6 1;
BA_ "GenSigSendType" SG_ 3221225472 Diag_Resp_AVP_Data7 1;
BA_ "GenSigSendType" SG_ 3221225472 Diag_FuncReq_Data0 1;
BA_ "GenSigSendType" SG_ 3221225472 Diag_FuncReq_Data1 1;
BA_ "GenSigSendType" SG_ 3221225472 Diag_FuncReq_Data2 1;
BA_ "GenSigSendType" SG_ 3221225472 Diag_FuncReq_Data3 1;
BA_ "GenSigSendType" SG_ 3221225472 Diag_FuncReq_Data4 1;
BA_ "GenSigSendType" SG_ 3221225472 Diag_FuncReq_Data5 1;
BA_ "GenSigSendType" SG_ 3221225472 Diag_FuncReq_Data6 1;
BA_ "GenSigSendType" SG_ 3221225472 Diag_FuncReq_Data7 1;
BA_ "GenSigInvalidValue" SG_ 130 VCU_AcclPedalPosToESCSta 4;
BA_ "GenSigStartValue" SG_ 130 VCU_ReqEPBV 1;
BA_ "GenSigInvalidValue" SG_ 130 VCU_ErrAmount 127;
BA_ "GenSigInvalidValue" SG_ 130 VCU_ErrBit 1023;
BA_ "GenSigStartValue" SG_ 388 AVP_Aeb_TgtAx 200;
BA_ "GenSigStartValue" SG_ 388 AVP_Acc_MotorTorqReqValue 2000;
BA_ "GenSigInvalidValue" SG_ 388 AVP_LrngDst_LeOver 1023;
BA_ "GenSigStartValue" SG_ 115 VCU_Actl_MotorTorque 2000;
BA_ "GenSigStartValue" SG_ 115 VCU_DrvReq_MotorTorq 2000;
BA_ "GenSigStartValue" SG_ 116 VCU_PwrRecupMaxAvlbMotorTorq 32768;
BA_ "GenSigStartValue" SG_ 116 VCU_PwrRecupActlMotorTorq 32768;
BA_ "GenSigInvalidValue" SG_ 281 BCM_SysPowerSts 7;
BA_ "GenSigSendType" SG_ 281 BCM_StartReq 4;
BA_ "GenSigStartValue" SG_ 281 BCM_vSetDis 127;
BA_ "GenSigInvalidValue" SG_ 288 ESC_VhclStandstillSta 2;
BA_ "GenSigStartValue" SG_ 288 ESC_VhclStandstillSta 2;
BA_ "GenSigStartValue" SG_ 288 YRS_YawRate 18000;
BA_ "GenSigInvalidValue" SG_ 288 YRS_LateralSensorState 1;
BA_ "GenSigStartValue" SG_ 288 YRS_LateralSensorState 3;
BA_ "GenSigInvalidValue" SG_ 288 YRS_YawRateSensorState 1;
BA_ "GenSigStartValue" SG_ 288 YRS_YawRateSensorState 3;
BA_ "GenSigStartValue" SG_ 288 YRS_LateralAcce 2000;
BA_ "GenSigInvalidValue" SG_ 288 YRS_LongitSensorState 1;
BA_ "GenSigStartValue" SG_ 288 YRS_LongitSensorState 3;
BA_ "GenSigStartValue" SG_ 288 YRS_LongitAcce 2000;
BA_ "GenSigStartValue" SG_ 288 ESC_MotorTorqDecReqValue 4000;
BA_ "GenSigStartValue" SG_ 288 ESC_MotorTorqIncReqValue 4000;
BA_ "GenSigStartValue" SG_ 288 ESC_VLCAPMotorTorqReqValue 2000;
BA_ "GenSigStartValue" SG_ 288 ESC_CDDInternTrgtAccValue 140;
BA_ "GenSigStartValue" SG_ 288 ESC_WheelSpeedKphV_FL 1;
BA_ "GenSigInvalidValue" SG_ 288 ESC_WheelDirection_FL 3;
BA_ "GenSigInvalidValue" SG_ 288 ESC_WheelSpeedKph_FL 8191;
BA_ "GenSigStartValue" SG_ 288 ESC_WheelSpeedKphV_FR 1;
BA_ "GenSigInvalidValue" SG_ 288 ESC_WheelDirection_FR 3;
BA_ "GenSigInvalidValue" SG_ 288 ESC_WheelSpeedKph_FR 8191;
BA_ "GenSigStartValue" SG_ 288 ESC_MasterCylinderPresrV 1;
BA_ "GenSigStartValue" SG_ 288 ESC_WheelSpeedKphV_RL 1;
BA_ "GenSigInvalidValue" SG_ 288 ESC_WheelDirection_RL 3;
BA_ "GenSigInvalidValue" SG_ 288 ESC_WheelSpeedKph_RL 8191;
BA_ "GenSigStartValue" SG_ 288 ESC_WheelSpeedKphV_RR 1;
BA_ "GenSigInvalidValue" SG_ 288 ESC_WheelDirection_RR 3;
BA_ "GenSigInvalidValue" SG_ 288 ESC_WheelSpeedKph_RR 8191;
BA_ "GenSigStartValue" SG_ 288 ESC_ESCorTCSFailed 1;
BA_ "GenSigStartValue" SG_ 288 ESC_EBDFailed 1;
BA_ "GenSigStartValue" SG_ 288 ESC_ABSFailed 1;
BA_ "GenSigInvalidValue" SG_ 288 ESC_VehicleSpeed 8191;
BA_ "GenSigStartValue" SG_ 288 ESC_HBB_Sts 3;
BA_ "GenSigStartValue" SG_ 288 ESC_BrakePedalSwV 1;
BA_ "GenSigStartValue" SG_ 288 ESC_HHC_FailSta 1;
BA_ "GenSigInvalidValue" SG_ 288 ESC_HDC_WorkSts 3;
BA_ "GenSigStartValue" SG_ 288 ESC_TrgtGearReqV 1;
BA_ "GenSigInvalidValue" SG_ 288 ESC_TrgtGearReq 7;
BA_ "GenSigInvalidValue" SG_ 352 ESC_EPB_SwitchSta 3;
BA_ "GenSigStartValue" SG_ 352 ESC_ReqTargetExternal 32256;
BA_ "GenSigStartValue" SG_ 352 ESC_EBDActiveSta 1;
BA_ "GenSigInvalidValue" SG_ 352 ESC_VmcVseYawRateOffset 65535;
BA_ "GenSigStartValue" SG_ 352 ESC_StabilityMarginQualifier 1;
BA_ "GenSigInvalidValue" SG_ 352 ESC_VmcVseSasOffset 16383;
BA_ "GenSigInvalidValue" SG_ 352 ESC_VmcVseAxOvrGrnd 32767;
BA_ "GenSigInvalidValue" SG_ 352 ESC_VmcVsevVeh 65535;
BA_ "GenSigInvalidValue" SG_ 352 ESC_VmcVSeSlope 2047;
BA_ "GenSigStartValue" SG_ 352 YRS_OriginalYawRate 18000;
BA_ "GenSigStartValue" SG_ 352 YRS_OriginalLateralAcce 2000;
BA_ "GenSigStartValue" SG_ 352 YRS_OriginalLongitAcce 2000;
BA_ "GenSigStartValue" SG_ 352 YRS_OriginalLongitSensorState 3;
BA_ "GenSigStartValue" SG_ 352 YRS_OriginalLateralSensorState 3;
BA_ "GenSigStartValue" SG_ 352 YRS_OriginalYawRateSensorState 3;
BA_ "GenSigStartValue" SG_ 336 EPS_ElecSteerModeSta 1;
BA_ "GenSigInvalidValue" SG_ 336 EPS_ElectPowerConsumption 255;
BA_ "GenSigStartValue" SG_ 384 SRS_PassSeatbeltBucklestatus 1;
BA_ "GenSigStartValue" SG_ 384 SRS_SeatbeltBucklestatus_RL 1;
BA_ "GenSigStartValue" SG_ 384 SRS_SeatbeltBucklestatus_RM 1;
BA_ "GenSigStartValue" SG_ 384 SRS_SeatbeltBucklestatus_RR 1;
BA_ "GenSigStartValue" SG_ 384 SRS_PassSeatbeltBuckleValid 1;
BA_ "GenSigSendType" SG_ 384 SRS_CrashOutputSts 6;
BA_ "GenSigStartValue" SG_ 384 SRS_PassSeatOccupantSensorSts 2;
BA_ "GenSigInvalidValue" SG_ 403 CRRR_RCTB_BrkgVld 1;
BA_ "GenSigInvalidValue" SG_ 403 CRRR_ObjDirY_Left_00 255;
BA_ "GenSigInvalidValue" SG_ 403 CRRR_ObjDirX_Left_00 255;
BA_ "GenSigInvalidValue" SG_ 403 CRRR_ObjDirY_Left_01 255;
BA_ "GenSigInvalidValue" SG_ 403 CRRR_ObjDirX_Left_01 255;
BA_ "GenSigInvalidValue" SG_ 403 CRRR_ObjDirY_Right_00 255;
BA_ "GenSigInvalidValue" SG_ 403 CRRR_ObjDirX_Right_00 255;
BA_ "GenSigInvalidValue" SG_ 403 CRRR_ObjDirY_Right_01 255;
BA_ "GenSigInvalidValue" SG_ 403 CRRR_ObjDirX_Right_01 255;
BA_ "GenSigInvalidValue" SG_ 403 CRRR_ObjDirY_Rear_00 255;
BA_ "GenSigInvalidValue" SG_ 403 CRRR_ObjDirX_Rear_00 255;
BA_ "GenSigInvalidValue" SG_ 403 CRRR_ObjDirY_Rear_01 255;
BA_ "GenSigInvalidValue" SG_ 403 CRRR_ObjDirX_Rear_01 255;
BA_ "GenSigInvalidValue" SG_ 404 CRFR_ObjDirY_Left_00 255;
BA_ "GenSigInvalidValue" SG_ 404 CRFR_ObjDirX_Left_00 255;
BA_ "GenSigInvalidValue" SG_ 404 CRFR_ObjDirY_Left_01 255;
BA_ "GenSigInvalidValue" SG_ 404 CRFR_ObjDirX_Left_01 255;
BA_ "GenSigInvalidValue" SG_ 404 CRFR_ObjDirY_Right_00 255;
BA_ "GenSigInvalidValue" SG_ 404 CRFR_ObjDirX_Right_00 255;
BA_ "GenSigInvalidValue" SG_ 404 CRFR_ObjDirY_Right_01 255;
BA_ "GenSigInvalidValue" SG_ 404 CRFR_ObjDirX_Right_01 255;
BA_ "GenSigInvalidValue" SG_ 404 CRFR_ObjDirY_Front_00 255;
BA_ "GenSigInvalidValue" SG_ 404 CRFR_ObjDirX_Front_00 255;
BA_ "GenSigInvalidValue" SG_ 404 CRFR_ObjDirY_Front_01 255;
BA_ "GenSigInvalidValue" SG_ 404 CRFR_ObjDirX_Front_01 255;
BA_ "GenSigInvalidValue" SG_ 458 VCU_VhclActlGearPos 7;
BA_ "GenSigInvalidValue" SG_ 458 VCU_VehActlDrvMode 3;
BA_ "GenSigStartValue" SG_ 458 VCU_GearShiftInhibited 1;
BA_ "GenSigStartValue" SG_ 565 BCM_DoorLockSta_FL 1;
BA_ "GenSigStartValue" SG_ 565 BCM_DoorLockSta_FR_RL_RR 1;
BA_ "GenSigSendType" SG_ 565 BCM_PDU_Forbidden 2;
BA_ "GenSigSendType" SG_ 565 BCM_SSBSwSta 4;
BA_ "GenSigInvalidValue" SG_ 601 SCM_TurnLightLeverSta 3;
BA_ "GenSigInvalidValue" SG_ 601 SCM_TripSW_Sts 3;
BA_ "GenSigInvalidValue" SG_ 601 SCM_FrontWipingMode 7;
BA_ "GenSigInvalidValue" SG_ 601 SCM_RearWipingMode 3;
BA_ "GenSigInvalidValue" SG_ 622 HU_ICU_ICUTotalOdometer 16777215;
BA_ "GenSigInvalidValue" SG_ 162 EPS_SteerWheelAngle 7800;
BA_ "GenSigInvalidValue" SG_ 162 EPS_RotSpeed 32767;
BA_ "GenSigStartValue" SG_ 162 EPS_RotSpeed 10240;
BA_ "GenSigInvalidValue" SG_ 163 EPS_PSCMIntRPCMaxTrq 2047;
BA_ "GenSigStartValue" SG_ 163 EPS_PSCMIntRPCMaxTrq 1024;
BA_ "GenSigInvalidValue" SG_ 163 EPS_PSCMIntRPCMinTrq 2047;
BA_ "GenSigStartValue" SG_ 163 EPS_PSCMIntRPCMinTrq 1024;
BA_ "GenSigInvalidValue" SG_ 389 APA_EPS_SetSteeringWheelAng 7800;
BA_ "GenSigStartValue" SG_ 389 APA_RPA_AvailSts 1;
BA_ "GenSigStartValue" SG_ 448 ADC_Acc_MotorTorqReqValue 2000;
BA_ "GenSigInvalidValue" SG_ 448 ADC_SteerTqReq 4095;
VAL_ 3221225472 CRRL_KeepAwakePwrMode 1 "Power ON" 0 "Power OFF" ;
VAL_ 3221225472 CRRL_KeepAwakeReasDiag 1 "Diagnosis is in progress" 0 "Diagnosis not in Progress" ;
VAL_ 3221225472 CRRL_KeepAwakeReasLocalFunReq 31 "Local Function Not Request" 30 "Reserved" 29 "Reserved" 28 "Reserved" 27 "Reserved" 26 "Reserved" 25 "Reserved" 24 "Reserved" 23 "Reserved" 22 "Reserved" 21 "Reserved" 20 "Reserved" 19 "Reserved" 18 "Reserved" 17 "Reserved" 16 "Reserved" 15 "Reserved" 14 "Reserved" 13 "Reserved" 12 "Reserved" 11 "Reserved" 10 "Reserved" 9 "Reserved" 8 "Reserved" 7 "Reserved" 6 "Reserved" 5 "Reserved" 4 "Reserved" 3 "Reserved" 2 "Reserved" 1 "Sending network management messages" 0 "SysPwrMode = ON" ;
VAL_ 3221225472 CRRL_KeepAwakeSta 1 "Keep Awake Reasons Occurred；" 0 "No Keep Awake Reasons；" ;
VAL_ 3221225472 CRRR_WakeupReas 255 "Reserved" 254 "Reserved" 253 "Reserved" 252 "Reserved" 251 "Reserved" 250 "Reserved" 249 "Reserved" 248 "Reserved" 247 "Reserved" 246 "Reserved" 245 "Reserved" 244 "Reserved" 243 "Reserved" 242 "Reserved" 241 "Reserved" 240 "Reserved" 239 "Reserved" 238 "Reserved" 237 "Reserved" 236 "Reserved" 235 "Reserved" 234 "Reserved" 233 "Reserved" 232 "Reserved" 231 "Reserved" 230 "Reserved" 229 "Reserved" 228 "Reserved" 227 "Reserved" 226 "Reserved" 225 "Reserved" 224 "Reserved" 223 "Reserved" 222 "Reserved" 221 "Reserved" 220 "Reserved" 219 "Reserved" 218 "Reserved" 217 "Reserved" 216 "Reserved" 215 "Reserved" 214 "Reserved" 213 "Reserved" 212 "Reserved" 211 "Reserved" 210 "Reserved" 209 "Reserved" 208 "Reserved" 207 "Reserved" 206 "Reserved" 205 "Reserved" 204 "Reserved" 203 "Reserved" 202 "Reserved" 201 "Reserved" 200 "Reserved" 199 "Reserved" 198 "Reserved" 197 "Reserved" 196 "Reserved" 195 "Reserved" 194 "Reserved" 193 "Reserved" 192 "Reserved" 191 "Reserved" 190 "Reserved" 189 "Reserved" 188 "Reserved" 187 "Reserved" 186 "Reserved" 185 "Reserved" 184 "Reserved" 183 "Reserved" 182 "Reserved" 181 "Reserved" 180 "Reserved" 179 "Reserved" 178 "Reserved" 177 "Reserved" 176 "Reserved" 175 "Reserved" 174 "Reserved" 173 "Reserved" 172 "Reserved" 171 "Reserved" 170 "Reserved" 169 "Reserved" 168 "Reserved" 167 "Reserved" 166 "Reserved" 165 "Reserved" 164 "Reserved" 163 "Reserved" 162 "Reserved" 161 "Reserved" 160 "Reserved" 159 "Reserved" 158 "Reserved" 157 "Reserved" 156 "Reserved" 155 "Reserved" 154 "Reserved" 153 "Reserved" 152 "Reserved" 151 "Reserved" 150 "Reserved" 149 "Reserved" 148 "Reserved" 147 "Reserved" 146 "Reserved" 145 "Reserved" 144 "Reserved" 143 "Reserved" 142 "Reserved" 141 "Reserved" 140 "Reserved" 139 "Reserved" 138 "Reserved" 137 "Reserved" 136 "Reserved" 135 "Reserved" 134 "Reserved" 133 "Reserved" 132 "Reserved" 131 "Reserved" 130 "Reserved" 129 "Reserved" 128 "Reserved" 127 "Reserved" 126 "Reserved" 125 "Reserved" 124 "Reserved" 123 "Reserved" 122 "Reserved" 121 "Reserved" 120 "Reserved" 119 "Reserved" 118 "Reserved" 117 "Reserved" 116 "Reserved" 115 "Reserved" 114 "Reserved" 113 "Reserved" 112 "Reserved" 111 "Reserved" 110 "Reserved" 109 "Reserved" 108 "Reserved" 107 "Reserved" 106 "Reserved" 105 "Reserved" 104 "Reserved" 103 "Reserved" 102 "Reserved" 101 "Reserved" 100 "Reserved" 99 "Reserved" 98 "Reserved" 97 "Reserved" 96 "Reserved" 95 "Reserved" 94 "Reserved" 93 "Reserved" 92 "Reserved" 91 "Reserved" 90 "Reserved" 89 "Reserved" 88 "Reserved" 87 "Reserved" 86 "Reserved" 85 "Reserved" 84 "Reserved" 83 "Reserved" 82 "Reserved" 81 "Reserved" 80 "Reserved" 79 "Reserved" 78 "Reserved" 77 "Reserved" 76 "Reserved" 75 "Reserved" 74 "Reserved" 73 "Reserved" 72 "Reserved" 71 "Reserved" 70 "Reserved" 69 "Reserved" 68 "Reserved" 67 "Reserved" 66 "Reserved" 65 "Reserved" 64 "Reserved" 63 "Reserved" 62 "Reserved" 61 "Reserved" 60 "Reserved" 59 "Reserved" 58 "Reserved" 57 "Reserved" 56 "Reserved" 55 "Reserved" 54 "Reserved" 53 "Reserved" 52 "Reserved" 51 "Reserved" 50 "Reserved" 49 "Reserved" 48 "Reserved" 47 "Reserved" 46 "Reserved" 45 "Reserved" 44 "Reserved" 43 "Reserved" 42 "Reserved" 41 "Reserved" 40 "Reserved" 39 "Reserved" 38 "Reserved" 37 "Reserved" 36 "Reserved" 35 "Reserved" 34 "Reserved" 33 "Reserved" 32 "Reserved" 31 "Reserved" 30 "Reserved" 29 "Reserved" 28 "Reserved" 27 "Reserved" 26 "Reserved" 25 "Reserved" 24 "Reserved" 23 "Reserved" 22 "Reserved" 21 "Reserved" 20 "Reserved" 19 "Reserved" 18 "Reserved" 17 "Reserved" 16 "Reserved" 15 "Reserved" 14 "Reserved" 13 "Reserved" 12 "Reserved" 11 "Reserved" 10 "Reserved" 9 "Reserved" 8 "Reserved" 7 "Reserved" 6 "Reserved" 5 "Reserved" 4 "Reserved" 3 "Reserved" 2 "Reserved" 1 "Reserved" 0 "remote awaken" ;
VAL_ 3221225472 CRRR_KeepAwakePwrMode 1 "Power ON" 0 "Power OFF" ;
VAL_ 3221225472 CRRR_KeepAwakeReasDiag 1 "Diagnosis is in progress" 0 "Diagnosis not in Progress" ;
VAL_ 3221225472 CRRR_KeepAwakeReasLocalFunReq 31 "Local Function Not Request" 30 "Reserved" 29 "Reserved" 28 "Reserved" 27 "Reserved" 26 "Reserved" 25 "Reserved" 24 "Reserved" 23 "Reserved" 22 "Reserved" 21 "Reserved" 20 "Reserved" 19 "Reserved" 18 "Reserved" 17 "Reserved" 16 "Reserved" 15 "Reserved" 14 "Reserved" 13 "Reserved" 12 "Reserved" 11 "Reserved" 10 "Reserved" 9 "Reserved" 8 "Reserved" 7 "Reserved" 6 "Reserved" 5 "Reserved" 4 "Reserved" 3 "Reserved" 2 "Reserved" 1 "Sending network management messages" 0 "SysPwrMode = ON" ;
VAL_ 3221225472 CRRR_KeepAwakeSta 1 "Keep Awake Reasons Occurred；" 0 "No Keep Awake Reasons；" ;
VAL_ 3221225472 AVP_WakeupReas 255 "Reserved" 254 "Reserved" 253 "Reserved" 252 "Reserved" 251 "Reserved" 250 "Reserved" 249 "Reserved" 248 "Reserved" 247 "Reserved" 246 "Reserved" 245 "Reserved" 244 "Reserved" 243 "Reserved" 242 "Reserved" 241 "Reserved" 240 "Reserved" 239 "Reserved" 238 "Reserved" 237 "Reserved" 236 "Reserved" 235 "Reserved" 234 "Reserved" 233 "Reserved" 232 "Reserved" 231 "Reserved" 230 "Reserved" 229 "Reserved" 228 "Reserved" 227 "Reserved" 226 "Reserved" 225 "Reserved" 224 "Reserved" 223 "Reserved" 222 "Reserved" 221 "Reserved" 220 "Reserved" 219 "Reserved" 218 "Reserved" 217 "Reserved" 216 "Reserved" 215 "Reserved" 214 "Reserved" 213 "Reserved" 212 "Reserved" 211 "Reserved" 210 "Reserved" 209 "Reserved" 208 "Reserved" 207 "Reserved" 206 "Reserved" 205 "Reserved" 204 "Reserved" 203 "Reserved" 202 "Reserved" 201 "Reserved" 200 "Reserved" 199 "Reserved" 198 "Reserved" 197 "Reserved" 196 "Reserved" 195 "Reserved" 194 "Reserved" 193 "Reserved" 192 "Reserved" 191 "Reserved" 190 "Reserved" 189 "Reserved" 188 "Reserved" 187 "Reserved" 186 "Reserved" 185 "Reserved" 184 "Reserved" 183 "Reserved" 182 "Reserved" 181 "Reserved" 180 "Reserved" 179 "Reserved" 178 "Reserved" 177 "Reserved" 176 "Reserved" 175 "Reserved" 174 "Reserved" 173 "Reserved" 172 "Reserved" 171 "Reserved" 170 "Reserved" 169 "Reserved" 168 "Reserved" 167 "Reserved" 166 "Reserved" 165 "Reserved" 164 "Reserved" 163 "Reserved" 162 "Reserved" 161 "Reserved" 160 "Reserved" 159 "Reserved" 158 "Reserved" 157 "Reserved" 156 "Reserved" 155 "Reserved" 154 "Reserved" 153 "Reserved" 152 "Reserved" 151 "Reserved" 150 "Reserved" 149 "Reserved" 148 "Reserved" 147 "Reserved" 146 "Reserved" 145 "Reserved" 144 "Reserved" 143 "Reserved" 142 "Reserved" 141 "Reserved" 140 "Reserved" 139 "Reserved" 138 "Reserved" 137 "Reserved" 136 "Reserved" 135 "Reserved" 134 "Reserved" 133 "Reserved" 132 "Reserved" 131 "Reserved" 130 "Reserved" 129 "Reserved" 128 "Reserved" 127 "Reserved" 126 "Reserved" 125 "Reserved" 124 "Reserved" 123 "Reserved" 122 "Reserved" 121 "Reserved" 120 "Reserved" 119 "Reserved" 118 "Reserved" 117 "Reserved" 116 "Reserved" 115 "Reserved" 114 "Reserved" 113 "Reserved" 112 "Reserved" 111 "Reserved" 110 "Reserved" 109 "Reserved" 108 "Reserved" 107 "Reserved" 106 "Reserved" 105 "Reserved" 104 "Reserved" 103 "Reserved" 102 "Reserved" 101 "Reserved" 100 "Reserved" 99 "Reserved" 98 "Reserved" 97 "Reserved" 96 "Reserved" 95 "Reserved" 94 "Reserved" 93 "Reserved" 92 "Reserved" 91 "Reserved" 90 "Reserved" 89 "Reserved" 88 "Reserved" 87 "Reserved" 86 "Reserved" 85 "Reserved" 84 "Reserved" 83 "Reserved" 82 "Reserved" 81 "Reserved" 80 "Reserved" 79 "Reserved" 78 "Reserved" 77 "Reserved" 76 "Reserved" 75 "Reserved" 74 "Reserved" 73 "Reserved" 72 "Reserved" 71 "Reserved" 70 "Reserved" 69 "Reserved" 68 "Reserved" 67 "Reserved" 66 "Reserved" 65 "Reserved" 64 "Reserved" 63 "Reserved" 62 "Reserved" 61 "Reserved" 60 "Reserved" 59 "Reserved" 58 "Reserved" 57 "Reserved" 56 "Reserved" 55 "Reserved" 54 "Reserved" 53 "Reserved" 52 "Reserved" 51 "Reserved" 50 "Reserved" 49 "Reserved" 48 "Reserved" 47 "Reserved" 46 "Reserved" 45 "Reserved" 44 "Reserved" 43 "Reserved" 42 "Reserved" 41 "Reserved" 40 "Reserved" 39 "Reserved" 38 "Reserved" 37 "Reserved" 36 "Reserved" 35 "Reserved" 34 "Reserved" 33 "Reserved" 32 "Reserved" 31 "Reserved" 30 "Reserved" 29 "Reserved" 28 "Reserved" 27 "Reserved" 26 "Reserved" 25 "Reserved" 24 "Reserved" 23 "Reserved" 22 "Reserved" 21 "Reserved" 20 "Reserved" 19 "Reserved" 18 "Reserved" 17 "Reserved" 16 "Reserved" 15 "Reserved" 14 "Reserved" 13 "Reserved" 12 "Reserved" 11 "Reserved" 10 "Reserved" 9 "Reserved" 8 "Reserved" 7 "Reserved" 6 "Reserved" 5 "Reserved" 4 "Reserved" 3 "Reserved" 2 "Reserved" 1 "Reserved" 0 "remote awaken" ;
VAL_ 3221225472 AVP_KeepAwakePwrMode 1 "Power ON" 0 "Power OFF" ;
VAL_ 3221225472 AVP_KeepAwakeReasDiag 1 "Diagnosis is in progress" 0 "Diagnosis not in Progress" ;
VAL_ 3221225472 AVP_KeepAwakeReasLocalFunReq 31 "Local Function Not Request" 30 "Reserved" 29 "Reserved" 28 "Reserved" 27 "Reserved" 26 "Reserved" 25 "Reserved" 24 "Reserved" 23 "Reserved" 22 "Reserved" 21 "Reserved" 20 "Reserved" 19 "Reserved" 18 "Reserved" 17 "Reserved" 16 "Reserved" 15 "Reserved" 14 "Reserved" 13 "Reserved" 12 "Reserved" 11 "Reserved" 10 "Reserved" 9 "Reserved" 8 "Reserved" 7 "Reserved" 6 "Reserved" 5 "Reserved" 4 "Reserved" 3 "Send network management messages" 2 "Charging" 1 "Ignition Relay active" 0 "SysPwrMode = ON" ;
VAL_ 3221225472 AVP_KeepAwakeSta 1 "Keep Awake Reasons Occurred" 0 "No Keep Awake Reasons" ;
VAL_ 130 VCU_AcclPedalPosToESCSta 4 "invalid" 3 "Virtual Value for APA&CC&ACC" 2 "Value estimated" 1 "Value ok" 0 "Value not availabe" ;
VAL_ 130 VCU_SysFailSta 7 "Reserved" 6 "Leve6_Err" 5 "Leve5_Err" 4 "Leve4_Err" 3 "Leve3_Err" 2 "Leve2_Err" 1 "Leve1_Err" 0 "NO Err" ;
VAL_ 130 VCU_ReqEPB 1 "request to apply" 0 "No request" ;
VAL_ 130 VCU_ReqEPBV 1 "valid" 0 "invalid" ;
VAL_ 130 VCU_ErrAmount 127 "Invalid" 0 "No Err" ;
VAL_ 130 VCU_ErrBit 1023 "Invalid" 0 "No Err" ;
VAL_ 130 VCU_EPK_ParkLock 7 "Unknown" 6 "UnParked Stalled" 5 "UnParked" 4 "UnParking" 3 "Park Stalled" 2 "Parked" 1 "Parking" 0 "Off" ;
VAL_ 388 AVP_HAVP_Recover_Indication 7 "Reserved" 6 "Req_Recover_Seat_Belt Not Fastened" 5 "Req_Recover_Mobile Connection" 4 "Req_Recover_Found Obstacle In Trajectory" 3 "Req_Recover_Door_Closed (all doors)" 2 "Req_Recover_Mobile out of Range" 1 "Req_Recover_Press_Interrupt Device Switch" 0 "No Request" ;
VAL_ 388 AVP_HAVP_Quit_Indication 31 "Req_Quit_Brake_pedal" 30 "Req_Quit_Interrupt time-out" 29 "Req_Quit_Remote Device error_HAVP" 28 "Req_Quit_TBOX_failure_HAVP" 27 "Req_Quit_Unsafe_Behavior" 26 "Req_Quit_No_parkinglot_HRVP(和APARPA不同)" 25 "Req_Quit_Phone_Disconnected_HRVP" 24 "Req_Quit_EPS failure" 23 "Req_Quit_ESP failure" 22 "Req_Quit_VCU failure" 21 "Req_Quit_External ECU failure" 20 "Req_Quit_Sys_Failure(和APARPA不同)" 19 "Req_Quit_Steering Wheel Intervention" 18 "Req_Quit_External ECU actvie" 17 "Req_Quit_Vehicle Block" 16 "Req_Quit_EPB_Apply" 15 "Req_Quit_Gear Interrupt" 14 "Req_Quit_Gear Intervention" 13 "Req_Quit_Terminate_Button_Pressed_HMI_Cancel_RD_Cancel" 12 "Req_Quit_Luggage Door Open_Reserved" 11 "Req_Quit_Door Open_all Doors_HAVP" 10 "Req_Quit_Seat belt unbuckle_HAVP" 9 "Req_Quit_TJA" 8 "Req_Quit_ACC" 7 "Req_Quit_Gas pedal" 6 "Req_Quit_Speed high" 5 "Req_Quit_Space limit" 4 "0x4: Req_Quit_Insufficient brightness" 3 "Req_Quit_Recover_Interrupt_Times_Overflow" 2 "Req_Quit_Move times overflow" 1 "Req_Quit_Timing overflow" 0 "No Request" ;
VAL_ 388 AVP_HAVP_System_Info 15 "Reserved" 14 "Reserved" 13 "Reserved" 12 "Power OFF failed" 11 "Power On failed" 10 "Task failed" 9 "Path Match failed" 8 "Parking completed" 7 "Parking out" 6 "Path Tracking" 5 "Parking in random lot" 4 "Parking in fixed lot" 3 "Path Matched and Disclaimer" 2 "ODD Selfcheck" 1 "Path Matching" 0 "No text" ;
VAL_ 388 AVP_VP_Info_Apply_P_EPB 1 "Request" 0 "No text" ;
VAL_ 388 AVP_VP_Info_Stop_Charging 1 "Request" 0 "No text" ;
VAL_ 388 AVP_VP_Info_Vechicle_PowerOff 1 "Request" 0 "No text" ;
VAL_ 388 AVP_VP_Quit_Indication 31 "Req_Quit_Brake_pedal(和APARPA不同)" 30 "Req_Quit_No_parkinglot_VP(和APARPA不同)" 29 "Req_Quit_Remote Device error_VP" 28 "Req_Quit_TBOX_failure_VP" 27 "Req_Quit_Unsafe_Behavior" 26 "Reserved" 25 "Reserved" 24 "Req_Quit_EPS failure" 23 "Req_Quit_ESP failure" 22 "Req_Quit_VCU failure" 21 "Req_Quit_External ECU failure" 20 "Req_Quit_Sys_Failure(和APARPA不同)" 19 "Req_Quit_Steering Wheel Intervention" 18 "Req_Quit_External ECU actvie" 17 "Req_Quit_Vehicle Block" 16 "Req_Quit_EPB_Apply" 15 "Req_Quit_Gear Interrupt" 14 "Req_Quit_Gear Intervention" 13 "Req_Quit_Terminate_Button_Pressed_HMI_Cancel_RD_Cancel" 12 "Req_Quit_Luggage Door Open_Reserved" 11 "Req_Quit_Door Open_all Doors_VP" 10 "Reserved" 9 "Req_Quit_TJA" 8 "Req_Quit_ACC" 7 "Req_Quit_Gas pedal" 6 "Req_Quit_Speed high" 5 "Req_Quit_Space limit" 4 "Req_Quit_Trajectory" 3 "Req_Quit_Recover_Interrupt_Times_Overflow" 2 "Req_Quit_Move times overflow" 1 "Req_Quit_Timing overflow" 0 "No Request" ;
VAL_ 388 AVP_VP_Recover_Indication 7 "Reserved" 6 "Reserved" 5 "Reserved" 4 "Reserved" 3 "Reserved" 2 "Req_Recover_Found Obstacle In Trajectory" 1 "Req_Recover_Door_Closed (all doors)" 0 "No Request" ;
VAL_ 388 AVP_VP_System_Info 31 "RD_info_Obtain Path failed" 30 "Reserved" 29 "Reserved" 28 "RD_info_Summon completed" 27 "RD_info_ESP handshaking failed" 26 "RD_info_EPS handshaking failed" 25 "RD_info_Power On failed" 24 "RD_info_Position unaviable" 23 "RD_info_AVP Unavailable" 22 "RD_info_Reserved15" 21 "RD_info_Reserved14" 20 "RD_info_Reserved13" 19 "RD_info_Reserved12" 18 "RD_info_Reserved11" 17 "RD_info_Reserved10" 16 "RD_info_Reserved9" 15 "RD_info_Reserved8" 14 "RD_info_Reserved7" 13 "RD_info_Reserved6" 12 "RD_info_Reserved5" 11 "RD_info_Reserved4" 10 "RD_info_Reserved3" 9 "RD_info_Reserved2" 8 "RD_info_Reserved1" 7 "RD_info_Close And Lock All Doors_Reserved（预留）" 6 "RD_info_No Person confirm" 5 "RD_info_Getting Off" 4 "Reserved" 3 "Reserved" 2 "Reserved" 1 "Reserved" 0 "No tex" ;
VAL_ 388 AVP_AebReqEna 1 "valid torque demand" 0 "no demand" ;
VAL_ 388 AVP_decFlg 1 "Yes" 0 "No" ;
VAL_ 388 AVP_AccReq_DrvOff 1 "demand" 0 "no demand" ;
VAL_ 388 AVP_AccReq_Standstill 1 "demand" 0 "no demand" ;
VAL_ 388 AVP_LogoLamp_Req 3 "Reserved" 2 "Request Colour2" 1 "Request Colour1" 0 "No request" ;
VAL_ 388 AVP_HighBeamLamp_Req 1 "ON" 0 "OFF" ;
VAL_ 388 AVP_LowBeamLamp_Req 1 "ON" 0 "OFF" ;
VAL_ 388 AVP_HazardLamp_Req 1 "ON" 0 "OFF" ;
VAL_ 388 AVP_TurnLeftLamp_Req 1 "ON" 0 "OFF" ;
VAL_ 388 AVP_TurnRightLamp_Req 1 "ON" 0 "OFF" ;
VAL_ 388 AVP_Horn_Req 1 "Request" 0 "No request" ;
VAL_ 388 AVP_Wiper_Req 1 "Request" 0 "No request" ;
VAL_ 388 AVP_WaterSpray_Req 1 "Request" 0 "No request" ;
VAL_ 388 AVP_PwrMode_Req 3 "Reserved" 2 "RPA On Request(PTready)" 1 "Power Off Request" 0 "No Request" ;
VAL_ 388 AVP_AccTrqReqEna 1 "valid torque demand" 0 "no demand" ;
VAL_ 388 AVP_FctSts 3 "AVP" 2 "HAVP" 1 "APA" 0 "No Request" ;
VAL_ 388 AVP_Runng 1 "Running" 0 "Not Running" ;
VAL_ 388 AVP_Acc_TgtAxReq 1 "demand" 0 "no demand" ;
VAL_ 388 AVP_Acc_Mode 7 "Failure mode" 6 "Standstill" 5 "Override" 4 "Brake-Only mode" 3 "Active-Control mode" 2 "Stand-By mode" 1 "Passive mode" 0 "OFF mode" ;
VAL_ 388 AVP_HAVP_Status 7 "learning path" 6 "Failure" 5 "Terminated" 4 "Completed" 3 "HAVP Active" 2 "Ready" 1 "Standby" 0 "Off" ;
VAL_ 388 AVP_VP_Status 7 "Reserved" 6 "Failure" 5 "Terminated" 4 "Completed" 3 "AVP Active" 2 "Ready" 1 "Standby" 0 "Off" ;
VAL_ 388 AVP_TrgtGearReq 7 "Invalid" 4 "Target gear D" 3 "Target gear N" 2 "Target gear R" 1 "Target gear P" 0 "No Request" ;
VAL_ 388 AVP_TrgtGearReqV 1 "valid" 0 "Invalid" ;
VAL_ 388 AVP_HAVP_StrtgEndgPointInfo 31 "Reserved" 30 "ending invailid（终点设置无效，功能退出，请确认路线类型）" 29 "Not supported D gear  for PI ending（入库路线，不支持D档入库车位）" 28 "Not supported R gear  for PO ending（不支持R档学习出库路线）" 27 "Not in parking space line for PO ending" 26 "System error for PO ending" 25 "Environment is abnormal for PO ending" 24 "Camera is blocked for PO ending" 23 "Front car is too close for PO ending" 22 "Too empty nnvironment for PO ending" 21 "Insufficient brightness for PO ending" 20 "Not in parking space line for PI ending" 19 "System error for PI ending" 18 "Environment is abnormal for PI ending" 17 "Camera is blocked for PI ending" 16 "Front car is too close for PI ending" 15 "Too empty nnvironment for PI ending" 14 "Insufficient brightness for PI ending" 13 "Not in parking space linefor PO starting" 12 "System error for for PO starting" 11 "Environment is abnormal for PO starting" 10 "Camera is blocked for PO starting" 9 "Front car is too close for PO starting" 8 "Too empty nnvironment for PO starting" 7 "Insufficient brightness for PO starting" 6 "System error for PI starting" 5 "Environment is abnormal for PI starting" 4 "Camera is blocked for PI starting" 3 "Front car is too close for PI starting" 2 "Too empty nnvironment for PI starting" 1 "Insufficient brightness for PI starting" 0 "No Request" ;
VAL_ 388 AVP_HAVP_Learning_Failed_Info 15 "Reserved" 14 "Reserved" 13 "Reserved" 12 "Reserved" 11 "Not supported R gear learning（不支持R档学习）；" 10 "Need to overscan a slot（入库学习，需要扫描过车位）；" 9 "Not supported Horizontal parking（不支持水平车位）--invalid；" 8 "Slope beyond limit 15%（坡度超限）精度受影响、控制难度、障碍物检测精度不好等" 7 "System error" 6 "Environment is abnormal" 5 "Camera is blocked" 4 "Front car is too close" 3 "Too empty nnvironment" 2 "Insufficient brightness" 1 "Learning time exceed 60mins" 0 "No text" ;
VAL_ 388 AVP_HAVP_Learning_Process_Info 31 "Reserved" 30 "Reserved" 29 "Reserved" 28 "Reserved" 27 "Reserved" 26 "Reserved" 25 "Reserved" 24 "Configurate failure（未配置功能或配置错误）" 23 "Request to choose path type(请选择路线类型)" 22 "function off（功能退出）" 21 "Remaining memory exceed limit（内存超限，学习终止）" 20 "Req_delate path Memory is full （需求删除路径再学习）" 19 "Speed higher than 20km/h and quit" 18 "Speed higher than 15km/h" 17 "Learning path failed" 16 "Ending point invalid" 15 "Setting path ending" 14 "Keep drving to ending" 13 "Learning finished" 12 "Fixed or random parking lot" 11 "Learning path valid_Reserved" 10 "Setting path name" 9 "Learning path invalid_Reserved" 8 "Saving path" 7 "Automatic parking in" 6 "Exceed learning distance limit" 5 "Distance limit" 4 "Continue driving" 3 "Starting point invalid" 2 "Speed high" 1 "Set path starting point" 0 "No text" ;
VAL_ 388 AVP_Learning_PathType1 3 "Parking out type" 2 "Trace tracking type" 1 "Parking in type" 0 "Invalid" ;
VAL_ 388 AVP_Learning_LotType1 3 "Reserved" 2 "Random parking lot" 1 "Fixed parking lot" 0 "Invalid" ;
VAL_ 388 AVP_HAVP_Path_Status1 3 "Backstage Learnning" 2 "Learning Inprocess Path" 1 "Valid Path" 0 "No comment" ;
VAL_ 388 AVP_Learning_PathType2 3 "Parking out type" 2 "Trace tracking type" 1 "Parking in type" 0 "Invalid" ;
VAL_ 388 AVP_Learning_LotType2 3 "Reserved" 2 "Random parking lot" 1 "Fixed parking lot" 0 "Invalid" ;
VAL_ 388 AVP_HAVP_Path_Status2 3 "Backstage Learnning" 2 "Learning Inprocess Path" 1 "Valid Path" 0 "No comment" ;
VAL_ 388 AVP_Learning_PathType3 3 "Parking out type" 2 "Trace tracking type" 1 "Parking in type" 0 "Invalid" ;
VAL_ 388 AVP_Learning_LotType3 3 "Reserved" 2 "Random parking lot" 1 "Fixed parking lot" 0 "Invalid" ;
VAL_ 388 AVP_HAVP_Path_Status3 3 "Backstage Learnning" 2 "Learning Inprocess Path" 1 "Valid Path" 0 "No comment" ;
VAL_ 388 AVP_Learning_PathType4 3 "Parking out type" 2 "Trace tracking type" 1 "Parking in type" 0 "Invalid" ;
VAL_ 388 AVP_Learning_LotType4 3 "Reserved" 2 "Random parking lot" 1 "Fixed parking lot" 0 "Invalid" ;
VAL_ 388 AVP_HAVP_Path_Status4 3 "Backstage Learnning" 2 "Learning Inprocess Path" 1 "Valid Path" 0 "No comment" ;
VAL_ 388 AVP_Learning_PathType5 3 "Parking out type" 2 "Trace tracking type" 1 "Parking in type" 0 "Invalid" ;
VAL_ 388 AVP_Learning_LotType5 3 "Reserved" 2 "Random parking lot" 1 "Fixed parking lot" 0 "Invalid" ;
VAL_ 388 AVP_HAVP_Path_Status5 3 "Backstage Learnning" 2 "Learning Inprocess Path" 1 "Valid Path" 0 "No comment" ;
VAL_ 388 AVP_HAVP_DrvrReq 31 "Reserved" 30 "Reserved" 29 "Reserved" 28 "Reserved" 27 "Reserved" 26 "Reserved" 25 "Reserved" 24 "Reserved" 23 "Reserved" 22 "Reserved" 21 "Reserved" 20 "Vehicle not stand still" 19 "Again Matching path" 18 "Straighten the steering wheel（请回正方向盘）" 17 "Time out （等待超时退出）" 16 "In a parking space（入库路线，已经在车位内）" 15 "parking inactive（功能不可用）" 14 "function off（功能退出）" 13 "Parking space found start park（车位已找到，开始入库）" 12 "Req_Find another parking slot（泊车失败，重新寻找车位）" 11 "Path ending arrived （出库路线，已经在终点）" 10 "Req_Confirm_Press DM Switch（请点击开始泊车）" 9 "Req_Release_BrakePedal（请释放刹车）" 8 "Req_Fasten_Safty_belt" 7 "Req_PowerOFF" 6 "Req_Update_Path（匹配失败，请重新学习）" 5 "Req_Drive_Path_Scope（匹配失败 ，请行驶至起点区域内）" 4 "Req_Gear_P" 3 "Req_stop （请停车后使用功能）" 2 "Req_Power_On_PTReady" 1 "Req_Close_Door_all doors" 0 "No text" ;
VAL_ 388 AVP_FrntCamCalSts 7 "reserved" 6 "reserved" 5 "reserved" 4 "reserved" 3 "calibrated" 2 "partially calibrated" 1 "calibrated error" 0 "not calibrated" ;
VAL_ 388 AVP_LrngDst_LeOver 1023 "Invalid" ;
VAL_ 115 VCU_Actl_MotorTorqueV 1 "Valid" 0 "Invalid" ;
VAL_ 115 VCU_EparkSysSta 1 "Epark fault" 0 "no fault" ;
VAL_ 115 VCU_VhclSpeedFastWarn 1 "Vspeed fast" 0 "no warning" ;
VAL_ 115 VCU_DrvReq_MotorTorqV 1 "Valid" 0 "Invalid" ;
VAL_ 115 VCU_Actl_MotorRotateSpdV 1 "Valid" 0 "Invalid" ;
VAL_ 115 VCU_EPKActlStatusHMI 7 "reserved" 6 "UnParked Stalled" 5 "reserved" 4 "UnParking" 3 "Park Stalled" 2 "reserved" 1 "Parking" 0 "Off" ;
VAL_ 116 VCU_PwrRecupMaxAvlbMotorTorqSta 2 "Faulty" 1 "Normal" 0 "Not Intialized" ;
VAL_ 116 VCU_MAAAvail 1 "Available" 0 "Not Available" ;
VAL_ 116 VCU_PwrRecupActlMotorTorqSta 2 "Faulty" 1 "Normal" 0 "Not Intialized" ;
VAL_ 116 VCU_MAA_ActvFdbk 3 "Reserved" 2 "Active" 1 "Supress" 0 "Not active" ;
VAL_ 116 VCU_BrakePwrRecupActlMotorTorqSt 3 "reserved" 2 "Faulty" 1 "Normal" 0 "Not Intialized" ;
VAL_ 274 VCU_BrkPedalSnsrPosV_Reserved 3 "Value faulty" 2 "Value estimated" 1 "Value ok" 0 "Value not availabe" ;
VAL_ 274 VCU_MotPumpSta_reserved 1 "Pump on" 0 "Pump off" ;
VAL_ 274 VCU_PCUWaterPumpSta 1 "Pump on" 0 "Pump off" ;
VAL_ 274 VCU_VacmPumpSta 1 "Pump on" 0 "Pump off" ;
VAL_ 274 VCU_DrvReqTorqOverrideESC 1 "Active" 0 "Inactive" ;
VAL_ 274 VCU_HighVolInterlockSta 3 "Measurement error" 2 "Interlock not ok (opened)" 1 "Interlock ok (closed)" 0 "No value available" ;
VAL_ 274 VCU_AcclPedalPosSnsrSta 3 "Value faulty" 2 "Value estimated" 1 "Value ok" 0 "Value not availabe" ;
VAL_ 281 BCM_CruiseDistanceIncre 1 "Pressed" 0 "Not Pressed" ;
VAL_ 281 BCM_CruiseDistanceDecre 1 "Pressed" 0 "Not Pressed" ;
VAL_ 281 BCM_CruiseModeCancel 1 "Pressed" 0 "Not Pressed" ;
VAL_ 281 BCM_CruiseRES 1 "Pressed" 0 "Not Pressed" ;
VAL_ 281 BCM_CruiseSET 1 "Pressed" 0 "Not Pressed" ;
VAL_ 281 BCM_CruiseModeChange 1 "Pressed" 0 "Not Pressed" ;
VAL_ 281 BCM_CruiseRES_Valid 1 "Valid" 0 "Invalid" ;
VAL_ 281 BCM_CruiseMainSwitch 1 "Pressed" 0 "Not Pressed" ;
VAL_ 281 BCM_SysPwrModeV 1 "Valid" 0 "Invalid" ;
VAL_ 281 BCM_SysPwrMode 3 "START_Reserved" 2 "ON" 1 "ACC_Reserved" 0 "OFF" ;
VAL_ 281 BCM_Cruise_limit_reserved 1 "Pressed" 0 "Not Pressed" ;
VAL_ 281 BCM_HighBeamSwSta 1 "ON" 0 "OFF" ;
VAL_ 281 BCM_HMASta 1 "ON" 0 "OFF" ;
VAL_ 281 BCM_SysPowerSts 7 "Invalid" 6 "reserved" 5 "OTA_1" 4 "RPA" 3 "OTA" 2 "远程" 1 "本地" 0 "PS_OFF" ;
VAL_ 281 BCM_StartReq 3 "Reserved" 2 "No Request" 1 "Request" 0 "No Command" ;
VAL_ 281 BCM_ThermRunawayWarn 3 "Reserved" 2 "Reserved" 1 "Warnning Level 1" 0 "NO Warnnig" ;
VAL_ 281 BCM_vSetDis 127 "no command" 126 "Invalid" 125 "Invalid" 124 "Invalid" 123 "Invalid" 122 "Invalid" 121 "Invalid" 120 "Invalid" 119 "Invalid" 118 "Invalid" 117 "Invalid" 116 "Invalid" 115 "Invalid" 114 "Invalid" 113 "Invalid" 112 "Invalid" 111 "Invalid" 110 "Invalid" 109 "Invalid" 108 "Invalid" 107 "Invalid" 106 "Invalid" 105 "Invalid" 104 "Invalid" 103 "Invalid" 102 "Invalid" 101 "Invalid" ;
VAL_ 281 BCM_ThermRunawaySnsrFlt 1 "Fault" 0 "Normal" ;
VAL_ 288 ESC_DTC_ActiveSts 1 "Active" 0 "Inactive" ;
VAL_ 288 ESC_BrakeTempOverHeat 1 "Abnormal" 0 "Normal" ;
VAL_ 288 ESC_NoBrakeForce 1 "No Brake Force" 0 "Exist Brake Force" ;
VAL_ 288 ESC_ABP_AvailableSta 1 "Available" 0 "Not Available" ;
VAL_ 288 ESC_ABP_ActiveSta 1 "Active" 0 "Inactive" ;
VAL_ 288 ESC_AEB_ActiveSta 1 "Active" 0 "Inactive" ;
VAL_ 288 ESC_AEB_AvailableSta 1 "Available" 0 "Not Available" ;
VAL_ 288 ESC_AWB_ActiveSta 1 "Active" 0 "Inactive" ;
VAL_ 288 ESC_AWB_AvailableSta 1 "Available" 0 "Not Available" ;
VAL_ 288 ESC_ABA_ActiveSta 1 "Active" 0 "Inactive" ;
VAL_ 288 ESC_ABA_AvailableSta 1 "Available" 0 "Not Available" ;
VAL_ 288 ESC_VhclStandstillSta 3 "Reserved" 2 "Invalid" 1 "Standstill" 0 "Not Standstill" ;
VAL_ 288 ESC_RCTB_AvailableSta 1 "Available" 0 "Not Available" ;
VAL_ 288 ESC_RCTB_ActiveSta 1 "Active" 0 "Inactive" ;
VAL_ 288 ESC_HMI_WarningOn 3 "reserved" 2 "Red Lamp" 1 "Yellow Lamp" 0 "No warning lamp" ;
VAL_ 288 ESC_ParkPawlRequest 1 "P Gear request" 0 "No request" ;
VAL_ 288 ESC_ParkPawlRequestV 1 "valid" 0 "invalid" ;
VAL_ 288 ESC_LSMHldActv 1 "active" 0 "not active" ;
VAL_ 288 ESC_LSMSSMSta 1 "standstill" 0 "not standstill" ;
VAL_ 288 YRS_LateralSensorState 3 "Initializing" 2 "Reserved" 1 "Invalid" 0 "Valid" ;
VAL_ 288 YRS_YawRateSensorState 3 "Initializing" 2 "Reserved" 1 "Invalid" 0 "Valid" ;
VAL_ 288 YRS_LongitSensorState 3 "Initializing" 2 "Reserved" 1 "Invalid" 0 "Valid" ;
VAL_ 288 ESC_MotorTorqDecReqActive 1 "Active" 0 "Inactive" ;
VAL_ 288 ESC_MotorTorqIncReqActive 1 "Active" 0 "Inactive" ;
VAL_ 288 ESC_PwrRecupTrgtMotorTorqSta 7 "reversed" 6 "reversed" 5 "reversed" 4 "reversed" 3 "Faulty" 2 "Normal active" 1 "Availble and not active" 0 "Not Intitialized" ;
VAL_ 288 ESC_CDDAvailable 1 "CDD interface available" 0 "CDD interface not available" ;
VAL_ 288 ESC_CDDActive 1 "CDD controller active" 0 "CDD controller not active" ;
VAL_ 288 ESC_VLCAPMotorTorqReqActive 1 "Active" 0 "Inactive" ;
VAL_ 288 ESC_CDDTempOff 0 "not high" 1 "temp too high" ;
VAL_ 288 ESC_Cruisecontrolshutdown 1 "Switch of ACC/CC" 0 "Not Switch of ACC/CC" ;
VAL_ 288 ESC_WheelSpeedKphV_FL 1 "Valid" 0 "Invalid" ;
VAL_ 288 ESC_WheelDirection_FL 3 "Invalid" 2 "Backward" 1 "Forward" 0 "Standstill" ;
VAL_ 288 ESC_WheelSpeedKph_FL 8191 "invalid" ;
VAL_ 288 ESC_WheelSpeedKphV_FR 1 "Valid" 0 "Invalid" ;
VAL_ 288 ESC_WheelDirection_FR 3 "Invalid" 2 "Backward" 1 "Forward" 0 "Standstill" ;
VAL_ 288 ESC_WheelSpeedKph_FR 8191 "invalid" ;
VAL_ 288 ESC_MasterCylinderPresrV 1 "Valid" 0 "Invalid" ;
VAL_ 288 ESC_WheelSpeedKphV_RL 1 "Valid" 0 "Invalid" ;
VAL_ 288 ESC_WheelDirection_RL 3 "Invalid" 2 "Backward" 1 "Forward" 0 "Standstill" ;
VAL_ 288 ESC_WheelSpeedKph_RL 8191 "invalid" ;
VAL_ 288 ESC_WheelSpeedKphV_RR 1 "Valid" 0 "Invalid" ;
VAL_ 288 ESC_WheelDirection_RR 3 "Invalid" 2 "Backward" 1 "Forward" 0 "Standstill" ;
VAL_ 288 ESC_WheelSpeedKph_RR 8191 "invalid" ;
VAL_ 288 ESC_WheelSpeedRCSts_RR 1 "Valid" 0 "Invalid" ;
VAL_ 288 ESC_WheelSpeedRCSts_RL 1 "Valid" 0 "Invalid" ;
VAL_ 288 ESC_WheelSpeedRCSts_FR 1 "Valid" 0 "Invalid" ;
VAL_ 288 ESC_WheelSpeedRCSts_FL 1 "Valid" 0 "Invalid" ;
VAL_ 288 ESC_ABSActiveSta 1 "Active" 0 "Inactive" ;
VAL_ 288 ESC_ESCorTCSFailed 1 "ESC/TCS Failed" 0 "ESC/TCSNormal" ;
VAL_ 288 ESC_EBDFailed 1 "EBD Failed" 0 "EBD Normal" ;
VAL_ 288 ESC_ABSFailed 1 "ABS Failed" 0 "ABS Normal" ;
VAL_ 288 ESC_TCSActiveSta 1 "TCS Active" 0 "TCS Inactive" ;
VAL_ 288 ESC_ESPActiveSta 1 "ESC Active" 0 "ESC Inactive" ;
VAL_ 288 ESC_VehicleSpeedV 1 "Valid" 0 "Invalid" ;
VAL_ 288 ESC_ReqBrakeLightOn 1 "Active" 0 "Inactive" ;
VAL_ 288 ESC_VehicleSpeed 8191 "invalid" ;
VAL_ 288 ESC_HAZActive 1 "Emergency brake light on" 0 "Emergency brake light off" ;
VAL_ 288 ESC_HBB_Intervention 1 "Active" 0 "Inactive" ;
VAL_ 288 ESC_HBB_Sts 3 "HBB_Disabled" 2 "HBB_FailedBoostBackup" 1 "HBB_FailedBoost / Reduced" 0 "HBB_Normal Mode" ;
VAL_ 288 ESC_AVH_Sts 3 "Error" 2 "Stand by" 1 "Intervention" 0 "Off" ;
VAL_ 288 ESC_BrakePedalSwV 1 "Valid" 0 "Invalid" ;
VAL_ 288 ESC_BrakePedalSwSta 1 "Pressed" 0 "Not pressed" ;
VAL_ 288 ESC_PALAResponse 3 "Sport Mode" 2 "Normal" 1 "OFF" 0 "No Command" ;
VAL_ 288 ESC_AVH_ICUPrompt 7 "No prompting" 6 "CloseDoorFastenBeltPTReady" 5 "FastenSafetyBelt,PT ready" 4 "close door and power PT ready" 3 "close door ,fasten safety belt" 2 "power PT ready" 1 "fasten safety belt" 0 "close door" ;
VAL_ 288 ESC_HHC_ActiveSta 1 "Active" 0 "Inactive" ;
VAL_ 288 ESC_HHC_FailSta 1 "Error" 0 "No error" ;
VAL_ 288 ESC_HDC_WorkSts 3 "Invalid" 2 "Active" 1 "Standby" 0 "OFF" ;
VAL_ 288 ESC_TrgtGearReqV 1 "valid" 0 "Invalid" ;
VAL_ 288 ESC_TrgtGearReq 7 "Invalid" 4 "Target gear D" 3 "Target gear N" 2 "Target gear R" 1 "Target gear P" 0 "No Request" ;
VAL_ 352 ESC_EPB_ParkLampSta 3 "Reserved" 2 "Blinking" 1 "ON" 0 "OFF" ;
VAL_ 352 ESC_EPB_WarnLampSta 3 "Reserved" 2 "Blinking" 1 "ON" 0 "OFF" ;
VAL_ 352 ESC_EPB_SwitchSta 3 "invalid" 2 "Apply" 1 "Release" 0 "Neutral" ;
VAL_ 352 ESC_EPB_ActuatorSt_R 7 "reversed" 6 "Hold" 5 "Unknown" 4 "Completely Released" 3 "Brake Applying" 2 "Brake Released" 1 "Brake Applied" 0 "Brake Releasing" ;
VAL_ 352 ESC_EPB_ActuatorSt_L 7 "reversed" 6 "Hold" 5 "Unknown" 4 "Completely Released" 3 "Brake Applying" 2 "Brake Released" 1 "Brake Applied" 0 "Brake Releasing" ;
VAL_ 352 ESC_EPB_DynamicApplySta 3 "reversed" 2 "Degrade Apply" 1 "RWU active" 0 "Not Active" ;
VAL_ 352 ESC_EPB_DisplayMsgID 15 "reversed" 14 "reversed" 13 "reversed" 12 "reversed" 11 "reversed" 10 "reversed" 9 "reversed" 8 "reversed" 7 "reversed" 6 "reversed" 5 "reversed" 4 "after roll reapply,still roll" 3 "slpoe too steep" 2 "push brake pedal" 1 "Fasten seatbelt & FL Door" 0 "off" ;
VAL_ 352 ESC_EPB_SystemState 7 "reversed" 6 "reversed" 5 "reversed" 4 "Brake Releasing" 3 "Brake Applying" 2 "Brake Applied" 1 "Brake Released" 0 "Not Initialized" ;
VAL_ 352 ESC_IB11_AccStabAvail 3 "Reserved" 2 "SignalAvailability_Full" 1 "SignalAvailability_Fault" 0 "SignalAvailability_NotInitialized" ;
VAL_ 352 ESC_IB11_YawRateStabAvailability 3 "Reserved" 2 "SignalAvailability_Full" 1 "SignalAvailability_Fault" 0 "SignalAvailability_NotInitialized" ;
VAL_ 352 ESC_IB11_DecStabCpblty 3 "DecelerationStabilizationCapability_Full" 2 "DecelerationStabilizationCapability_NoDragTorqueControl" 1 "DecelerationStabilizationCapability_Reduced" 0 "DecelerationStabilizationCapability_None" ;
VAL_ 352 ESC_IB11_DecStabCpbltyForDrvr 3 "DecelerationStabilizationCapability_Full" 2 "DecelerationStabilizationCapability_NoDragTorqueControl" 1 "DecelerationStabilizationCapability_Reduced" 0 "DecelerationStabilizationCapability_None" ;
VAL_ 352 ESC_PresrMCVirtualQ 3 "reserved" 2 "pMcVirtual_Faulty" 1 "pMcVirtual_Normal" 0 "pMcVirtual_NotInitialized" ;
VAL_ 352 ESC_ForceBlendingActive 3 "reserved" 2 "PFC_Active" 1 "PFC_Hold" 0 "PFC_Inactive" ;
VAL_ 352 ESC_PresrForceBlendingMCQ 3 "reserved" 2 "pForceBlendingMC_Faulty" 1 "pForceBlendingMC_Normal" 0 "pForceBlendingMC_NotInitialized" ;
VAL_ 352 ESC_ReqTargetExternalQ 3 "reserved" 2 "qTarget_EBREmergencyBA" 1 "qTarget_EBR" 0 "qTarget_Off" ;
VAL_ 352 ESC_LSMPosLongACapbl 3 "reversed" 2 "AxCapbl_VehBlocked" 1 "reversed" 0 "AxCapbl_Full" ;
VAL_ 352 ESC_LSMSubMTReqAvailable 1 "ture" 0 "false" ;
VAL_ 352 ESC_LSMSubMTLevelEcho 3 "MTLevel_Reserved" 2 "MTLevel_23_RPA" 1 "MTLevel_12_APA" 0 "MTLevel_None" ;
VAL_ 352 ESC_LSMSubMTLongEcho 3 "MTLong_Reserved" 2 "MTLong_Emergency" 1 "MTLong_Comfort" 0 "MTLong_None" ;
VAL_ 352 ESC_LSMSubMTReqEcho 3 "MTLong_Reserved" 2 "MTReq_LSM" 1 "MTReq_Drive" 0 "MTReq_None" ;
VAL_ 352 ESC_Lsm12ComfortAvl 3 "Enum3_Available" 2 "Enum3_FailureDetectedFullyAvl" 1 "Enum3_FailureDetectedReducedAvl" 0 "Enum3_NotAvailable" ;
VAL_ 352 ESC_Lsm12EmergencyAvl 3 "Enum3_Available" 2 "Enum3_FailureDetectedFullyAvl" 1 "Enum3_FailureDetectedReducedAvl" 0 "Enum3_NotAvailable" ;
VAL_ 352 ESC_Lsm23Avl 3 "Enum3_Available" 2 "Enum3_FailureDetectedFullyAvl" 1 "Enum3_FailureDetectedReducedAvl" 0 "Enum3_NotAvailable" ;
VAL_ 352 ESC_EBDActiveSta 1 "Active" 0 "Inactive" ;
VAL_ 352 ESC_HBC_ActiveSta 1 "Active" 0 "Inactive" ;
VAL_ 352 ESC_HBC_Available 1 "Available" 0 "Not Available" ;
VAL_ 352 ESC_HBAActiveSta 1 "Active" 0 "Inactive" ;
VAL_ 352 ESC_HBA_Available 1 "Available" 0 "Not Available" ;
VAL_ 352 ESC_DTC_Available 1 "Available" 0 "Not Available" ;
VAL_ 352 ESC_CDP_ActiveSta 1 "Available" 0 "Not Available" ;
VAL_ 352 ESC_CDP_Available 1 "Available" 0 "Not Available" ;
VAL_ 352 ESC_CMMotionSrvReq 7 "reversed" 6 "reversed" 5 "reversed" 4 "SrvReq_LsmLvl23Emergency" 3 "SrvReq_LsmLvl23Comfort" 2 "SrvReq_LsmLvl12Emergency" 1 "SrvReq_LsmLvl12Comfort" 0 "SrvReq_None" ;
VAL_ 352 ESC_VmcActLongPrimaryAvailable 3 "VmcDsmAvailability_Available" 2 "VmcDsmAvailability_AvailableWithFault" 1 "VmcDsmAvailability_Fault" 0 "VmcDsmAvailability_NotAvailable" ;
VAL_ 352 ESC_IGNOn 1 "on" 0 "false" ;
VAL_ 352 ESC_LSMabortfeedback 15 "Reserved" 14 "Reserved" 13 "Reserved" 12 "time over the range" 11 "speed limition too small" 10 "APA control signal failure" 9 "communication error with APA" 8 "Acc pedal" 7 "Ibooster failure" 6 "communication failure with IB" 5 "vehicle block" 4 "ESC internal failure" 3 "unexpected gear" 2 "slope over the range" 1 "high speed" 0 "none" ;
VAL_ 352 ESC_VmcVseYawRateOffset 65535 "Invalid" ;
VAL_ 352 ESC_StabilityMarginQualifier 3 "reversed" 2 "Faulty" 1 "Normal" 0 "Not Initialed" ;
VAL_ 352 ESC_VmcVseSasOffset 16383 "Invalid" ;
VAL_ 352 ESC_VmcVseYawRateAvlCpby 7 "SspBufferSt7" 6 "SspBufferSt6" 5 "SspBufferSt5" 4 "AvlCpbyHi" 3 "AvlCpbyMid" 2 "AvlCpbyLo" 1 "Fault" 0 "NotAvl" ;
VAL_ 352 ESC_VmcVseAxOvrGrnd 32767 "Invalid" ;
VAL_ 352 ESC_VmcVsevVeh 65535 "Invalid" ;
VAL_ 352 ESC_VmcVseSasAvlCpby 7 "SspBufferSt7" 6 "SspBufferSt6" 5 "SspBufferSt5" 4 "AvlCpbyHi" 3 "AvlCpbyMid" 2 "AvlCpbyLo" 1 "Fault" 0 "NotAvl" ;
VAL_ 352 ESC_VmcVseStandstill 1 "Vehicle is in standstill" 0 "Vehicle is not in standstill" ;
VAL_ 352 ESC_VmcVSeSlope 2047 "Invalid" ;
VAL_ 352 ESC_VmcVseLgtPrimSrvAvlCpby 7 "SspBufferSt7" 6 "SspBufferSt6" 5 "SspBufferSt5" 4 "AvlCpbyHi" 3 "AvlCpbyMid" 2 "AvlCpbyLo" 1 "Fault" 0 "NotAvl" ;
VAL_ 352 ESC_IB11_usedChannel 3 "usedChannel_Instance2Com2" 2 "usedChannel_Instance2Com1" 1 "usedChannel_Instance1Com2" 0 "usedChannel_Instance1Com1" ;
VAL_ 352 ESC_IB11_BrakeFxCapability 3 "reversed" 2 "BrakeFx_FullPerformance" 1 "BrakeFx_ReducedPerformance" 0 "BrakeFx_None" ;
VAL_ 352 ESC_IB11_BrakeFxAvailability 2 "SignalAvailability_Full" 1 "SignalAvailability_Fault" 0 "SignalAvailability_NotInitialized" ;
VAL_ 352 ESC_IB12_BrkDiscTempStatus 3 "BrakeDiscTemperature_WarningLevel3" 2 "BrakeDiscTemperature_WarningLevel2" 1 "BrakeDiscTemperature_WarningLevel1" 0 "BrakeDiscTemperature_NormalRange" ;
VAL_ 352 ESC_IB11_DecStabAvail 3 "reversed" 2 "SignalAvailability_Full" 1 "SignalAvailability_Fault" 0 "SignalAvailability_NotInitialized" ;
VAL_ 352 ESC_IB11_isBrkFctReqFxBrkDomin 1 "Dominate" 0 "Not dominate" ;
VAL_ 352 ESC_IB11_DecStabAvailForDriver 3 "reversed" 2 "SignalAvailability_Full" 1 "SignalAvailability_Fault" 0 "SignalAvailability_NotInitialized" ;
VAL_ 352 ESC_IB11_DecStabActivity 3 "reversed" 2 "DecelerationStabilizationActivity_AtAllWheels" 1 "DecelerationStabilizationActivity_AtLeastOneWheel" 0 "DecelerationStabilizationActivity_None" ;
VAL_ 352 ESC_IB11_AccStabActivity 1 "StabilizationActivity_Active" 0 "StabilizationActivity_None" ;
VAL_ 352 ESC_IB11_YawRateStabActivity 1 "StabilizationActivity_Active" 0 "StabilizationActivity_None" ;
VAL_ 352 ESC_IB11_ParkBrakeCapability 3 "reversed" 2 "BrakeCapability_Full" 1 "BrakeCapability_Reduced" 0 "BrakeCapability_None" ;
VAL_ 352 ESC_IB11_ParkBrakeAvailability 3 "ParkBrakeAvailability_Full" 2 "ParkBrakeAvailability_FullNoDriverRelease" 1 "ParkBrakeAvailability_Fault" 0 "ParkBrakeAvailability_NotInitialized" ;
VAL_ 352 ESC_IB12_BrkDiscTempStatusAvail 3 "reversed" 2 "SignalAvailability_Full" 1 "SignalAvailability_Fault" 0 "SignalAvailability_NotInitialized" ;
VAL_ 352 ESC_IB11_ParkBrakeState 7 "reversed" 6 "reversed" 5 "reversed" 4 "ParkBrakeState_Released" 3 "ParkBrakeState_Releasing" 2 "ParkBrakeState_Applied" 1 "ParkBrakeState_Applying" 0 "ParkBrakeState_Unknown" ;
VAL_ 352 ESC_IB11_ParkBrakeSupportRequest 1 "ParkSupport_ActiveRequest" 0 "ParkSupport_NoRequest" ;
VAL_ 352 ESC_IB11_DriveMain2BackupState 15 "reversed" 14 "reversed" 13 "reversed" 12 "reversed" 11 "Deactivation_Pending" 10 "Activated_RedundancyLost" 9 "Activated_FailOperation" 8 "Activated_FullAvailable" 7 "Activation_PendingFailOperation" 6 "Activation_PendingRedundancyLost" 5 "Activation_Pending" 4 "Activation_Preparation" 3 "NotActivated_FullAvailable" 2 "NotAvailable_Permanent" 1 "NotAvailable_NotReleased" 0 "NotAvailable_Temporary" ;
VAL_ 352 ESC_IB11_StopMain2BackupState 15 "reversed" 14 "reversed" 13 "reversed" 12 "reversed" 11 "Deactivation_Pending" 10 "Activated_RedundancyLost" 9 "Activated_FailOperation" 8 "Activated_FullAvailable" 7 "Activation_PendingFailOperation" 6 "Activation_PendingRedundancyLost" 5 "Activation_Pending" 4 "Activation_Preparation" 3 "NotActivated_FullAvailable" 2 "NotAvailable_Permanent" 1 "NotAvailable_NotReleased" 0 "NotAvailable_Temporary" ;
VAL_ 352 ESC_IB11_isBrkFctReqPrkBrkDomin 1 "Dominate" 0 "Not dominate" ;
VAL_ 352 ESC_IB12_isDrvPressingBrakePedal 1 "Driver press brake pedal" 0 "Driver not press brake pedal" ;
VAL_ 352 ESC_IB12_DrvReqTarFxBrakeAvail 3 "reversed" 2 "SignalAvailability_Full" 1 "SignalAvailability_Fault" 0 "SignalAvailability_NotInitialized" ;
VAL_ 352 ESC_IB12_DrvPressBrakePedalAvail 3 "reversed" 2 "SignalAvailability_Full" 1 "SignalAvailability_Fault" 0 "SignalAvailability_NotInitialized" ;
VAL_ 352 ESC_IB12_DrvReqFxBrkDomAvail 3 "reversed" 2 "SignalAvailability_Full" 1 "SignalAvailability_Fault" 0 "SignalAvailability_NotInitialized" ;
VAL_ 352 ESC_IB12_isDrvReqFxBrakeDominant 1 "Dominate" 0 "Not dominate" ;
VAL_ 352 ESC_IB12_isDrvReqParkBrkDominant 1 "Dominate" 0 "Not dominate" ;
VAL_ 352 ESC_IB12_DrvReqParkBrakeAvail 3 "reversed" 2 "SignalAvailability_Full" 1 "SignalAvailability_Fault" 0 "SignalAvailability_NotInitialized" ;
VAL_ 352 ESC_IB12_DriverRequestParkBrake 3 "reversed" 2 "ParkBrake_Apply" 1 "ParkBrake_Release" 0 "ParkBrake_NoRequest" ;
VAL_ 352 ESC_VehicleSpeed2IB_Q 3 "reversed" 2 "Faulty" 1 "Normal" 0 "NotInitialized" ;
VAL_ 352 ESC_pMC1_Q 3 "reversed" 2 "Faulty" 1 "Normal" 0 "NotInitialized" ;
VAL_ 352 ESC_IBAbsActive 1 "Active" 0 "Inactive" ;
VAL_ 352 YRS_OriginalLongitSensorState 3 "Initializing" 2 "Reserved" 1 "Valid" 0 "Invalid" ;
VAL_ 352 YRS_OriginalLateralSensorState 3 "Initializing" 2 "Reserved" 1 "Valid" 0 "Invalid" ;
VAL_ 352 YRS_OriginalYawRateSensorState 3 "Initializing" 2 "Reserved" 1 "Valid" 0 "Invalid" ;
VAL_ 336 EPS_BasicElecSteerFailed 1 "Failed" 0 "Not failed" ;
VAL_ 336 EPS_ModeSetInhibitFb 1 "Inhibit" 0 "No inhibit" ;
VAL_ 336 EPS_ElecSteerModeSta 3 "Sport" 2 "Comfort" 1 "Standard" 0 "Advanced" ;
VAL_ 336 EPS_APA_Abortfeedback 15 "Reserved" 14 "Reserved" 13 "Reserved" 12 "Reserved" 11 "Reserved" 10 "Reserved" 9 "Reserved" 8 "Improper handshaking" 7 "EPS internal temperature too high" 6 "Vehicle speed exceeds limits when in control" 5 "EPS internal error" 4 "APA control signal timeout" 3 "StrWhlAng Speed out of limit" 2 "StrWhlAng out of limit" 1 "Maneuver terminated" 0 "No Abort" ;
VAL_ 336 EPS_APACtrlAvlbl 1 "Control Enable" 0 "Control Disable" ;
VAL_ 336 EPS_TorsionBarTorqueDir 1 "Negative" 0 "Positive" ;
VAL_ 336 EPS_TorsionBarTorqueValid 1 "Valid" 0 "Invalid" ;
VAL_ 336 EPS_APA_SysStatus 1 "Available" 0 "Not Available" ;
VAL_ 336 EPS_ElectPowerConsumption 255 "Invalid" ;
VAL_ 384 SRS_DrvSeatbeltBucklestatus 1 "Safety belt tied" 0 "Safety belt not tied" ;
VAL_ 384 SRS_PassSeatbeltBucklestatus 1 "Safety belt not tied" 0 "Safety belt tied" ;
VAL_ 384 SRS_SeatbeltBucklestatus_RL 1 "Safety belt not tied" 0 "Safety belt tied" ;
VAL_ 384 SRS_SeatbeltBucklestatus_RM 1 "Safety belt not tied" 0 "Safety belt tied" ;
VAL_ 384 SRS_SeatbeltBucklestatus_RR 1 "Safety belt not tied" 0 "Safety belt tied" ;
VAL_ 384 SRS_DrvSeatbeltBuckleValid 1 "Valid" 0 "Invalid" ;
VAL_ 384 SRS_PassSeatbeltBuckleValid 1 "Valid" 0 "Invalid" ;
VAL_ 384 SRS_PassengerAirbagSta_Rsvr 1 "PAB enable" 0 "PAB disable" ;
VAL_ 384 SRS_CrashOutputSts 7 "Reserved" 6 "Reserved" 5 "Rear crash" 4 "Right side crash" 2 "Left side crash" 1 "FrontAB and BT crash" 0 "No crash" ;
VAL_ 384 SRS_PassSeatOccupantSensorSts 3 "Reserved" 2 "Occupied" 1 "Empty" 0 "Reserved" ;
VAL_ 384 SRS_AirbagWarningLampSts 3 "Reserved" 2 "BLINK" 1 "ON" 0 "OFF" ;
VAL_ 403 CRRR_BSD_SetFb 1 "BSD and LCA On" 0 "BSD and LCA Off" ;
VAL_ 403 CRRR_BSD_Warn_Right 3 "Reserved" 2 "Level 2 Waring" 1 "Level 1 Waring" 0 "No Waring" ;
VAL_ 403 CRRR_BSD_Warn_Left 3 "Reserved" 2 "Level 2 Waring" 1 "Level 1 Waring" 0 "No Waring" ;
VAL_ 403 CRRR_RCTA_Warn_Right 3 "Reserved" 2 "Level 2 Waring" 1 "Level 1 Waring" 0 "No Waring" ;
VAL_ 403 CRRR_RCTA_SetFb 1 "RCTA On" 0 "RCTA Off" ;
VAL_ 403 CRRR_RCTA_Warn_Left 3 "Reserved" 2 "Level 2 Waring" 1 "Level 1 Waring" 0 "No Waring" ;
VAL_ 403 CRRR_DOW_Warn_Right 3 "reserved" 2 "warning level 2" 1 "warning level 1" 0 "no warning" ;
VAL_ 403 CRRR_RCW_Warning 3 "reserved" 2 "warning level 2" 1 "warning level 1" 0 "no warning" ;
VAL_ 403 CRRR_RCTBDecelaration 255 "Valid value" 254 "Valid value" 253 "Valid value" 252 "Valid value" 251 "Valid value" 250 "Valid value" 249 "Valid value" 248 "Valid value" 247 "Valid value" 246 "Valid value" 245 "Valid value" 244 "Valid value" 243 "Valid value" 242 "Valid value" 241 "Valid value" 240 "Valid value" 239 "Valid value" 238 "Valid value" 237 "Valid value" 236 "Valid value" 235 "Valid value" 234 "Valid value" 233 "Valid value" 232 "Valid value" 231 "Valid value" 230 "Valid value" 229 "Valid value" 228 "Valid value" 227 "Valid value" 226 "Valid value" 225 "Valid value" 224 "Valid value" 223 "Valid value" 222 "Valid value" 221 "Valid value" 220 "Valid value" 219 "Valid value" 218 "Valid value" 217 "Valid value" 216 "Valid value" 215 "Valid value" 214 "Valid value" 213 "Valid value" 212 "Valid value" 211 "Valid value" 210 "Valid value" 209 "Valid value" 208 "Valid value" 207 "Valid value" 206 "Valid value" 205 "Valid value" 204 "Valid value" 203 "Valid value" 202 "Valid value" 201 "Valid value" 200 "Valid value" 199 "Valid value" 198 "Valid value" 197 "Valid value" 196 "Valid value" 195 "Valid value" 194 "Valid value" 193 "Valid value" 192 "Valid value" 191 "Valid value" 190 "Valid value" 189 "Valid value" 188 "Valid value" 187 "Valid value" 186 "Valid value" 185 "Valid value" 184 "Valid value" 183 "Valid value" 182 "Valid value" 181 "Valid value" 180 "Valid value" 179 "Valid value" 178 "Valid value" 177 "Valid value" 176 "Valid value" 175 "Valid value" 174 "Valid value" 173 "Valid value" 172 "Valid value" 171 "Valid value" 170 "Valid value" 169 "Valid value" 168 "Valid value" 167 "Valid value" 166 "Valid value" 165 "Valid value" 164 "Valid value" 163 "Valid value" 162 "Valid value" 161 "Valid value" 160 "Valid value" 159 "Valid value" 158 "Valid value" 157 "Valid value" 156 "Valid value" 155 "Valid value" 154 "Valid value" 153 "Valid value" 152 "Valid value" 151 "Valid value" 150 "Valid value" 149 "Valid value" 148 "Valid value" 147 "Valid value" 146 "Valid value" 145 "Valid value" 144 "Valid value" 143 "Valid value" 142 "Valid value" 141 "Valid value" 140 "Valid value" 139 "Valid value" 138 "Valid value" 137 "Valid value" 136 "Valid value" 135 "Valid value" 134 "Valid value" 133 "Valid value" 132 "Valid value" 131 "Valid value" 130 "Valid value" 129 "Valid value" 128 "Valid value" 127 "Valid value" 126 "Valid value" 125 "Valid value" 124 "Valid value" 123 "Valid value" 122 "Valid value" 121 "Valid value" 120 "Valid value" 119 "Valid value" 118 "Valid value" 117 "Valid value" 116 "Valid value" 115 "Valid value" 114 "Valid value" 113 "Valid value" 112 "Valid value" 111 "Valid value" 110 "Valid value" 109 "Valid value" 108 "Valid value" 107 "Valid value" 106 "Valid value" 105 "Valid value" 104 "Valid value" 103 "Valid value" 102 "Valid value" 101 "Valid value" 100 "Valid value" 99 "Valid value" 98 "Valid value" 97 "Valid value" 96 "Valid value" 95 "Valid value" 94 "Valid value" 93 "Valid value" 92 "Valid value" 91 "Valid value" 90 "Valid value" 89 "Valid value" 88 "Valid value" 87 "Valid value" 86 "Valid value" 85 "Valid value" 84 "Valid value" 83 "Valid value" 82 "Valid value" 81 "Valid value" 80 "Valid value" 79 "Valid value" 78 "Valid value" 77 "Valid value" 76 "Valid value" 75 "Valid value" 74 "Valid value" 73 "Valid value" 72 "Valid value" 71 "Valid value" 70 "Valid value" 69 "Valid value" 68 "Valid value" 67 "Valid value" 66 "Valid value" 65 "Valid value" 64 "Valid value" 63 "Valid value" 62 "Valid value" 61 "Valid value" 60 "Valid value" 59 "Valid value" 58 "Valid value" 57 "Valid value" 56 "Valid value" 55 "Valid value" 54 "Valid value" 53 "Valid value" 52 "Valid value" 51 "Valid value" 50 "Valid value" 49 "Valid value" 48 "Valid value" 47 "Valid value" 46 "Valid value" 45 "Valid value" 44 "Valid value" 43 "Valid value" 42 "Valid value" 41 "Valid value" 40 "Valid value" 39 "Valid value" 38 "Valid value" 37 "Valid value" 36 "Valid value" 35 "Valid value" 34 "Valid value" 33 "Valid value" 32 "Valid value" 31 "Valid value" 30 "Valid value" 29 "Valid value" 28 "Valid value" 27 "Valid value" 26 "Valid value" 25 "Valid value" 24 "Valid value" 23 "Valid value" 22 "Valid value" 21 "Valid value" 20 "Valid value" 19 "Valid value" 18 "Valid value" 17 "Valid value" 16 "Valid value" 15 "Valid value" 14 "Valid value" 13 "Valid value" 12 "Valid value" 11 "Valid value" 10 "Valid value" 9 "Valid value" 8 "Valid value" 7 "Valid value" 6 "Valid value" 5 "Valid value" 4 "Valid value" 3 "Valid value" 2 "Valid value" 1 "Valid value" 0 "Valid value" ;
VAL_ 403 CRRR_DOWSetFb 1 "DOW On" 0 "DOW Off" ;
VAL_ 403 CRRR_RCTBReq 1 "demand" 0 "no demand" ;
VAL_ 403 CRRR_RCTB_BrkgVld 1 "Invalid" 0 "Valid" ;
VAL_ 403 CRRR_RCW_SetFb 1 "RCW On" 0 "RCW Off" ;
VAL_ 403 CRRR_DOW_Warn_Left 3 "reserved" 2 "warning level 2" 1 "warning level 1" 0 "no warning" ;
VAL_ 403 CRRR_RearCornerFailure 3 "Left and Right Failure" 2 "Rear Right Failure" 1 "Rear Left Failure" 0 "No Failure" ;
VAL_ 403 CRRR_RearCornerBlindness 3 "Left and Right Blindness" 2 "Rear Right Blindness" 1 "Rear Left Blindness" 0 "No Blindness" ;
VAL_ 403 CRRR_FOVChangeSetFb 3 "RL_RR Long-Distance" 2 "RL_Normal RR_Long-Distance" 1 "RL_Long-Distance RR_Normal" 0 "RL_RR Normal" ;
VAL_ 403 CRRR_ObjDirY_Left_00 255 "Invalid" ;
VAL_ 403 CRRR_ObjDirX_Left_00 255 "Invalid" ;
VAL_ 403 CRRR_ObjDirY_Left_01 255 "Invalid" ;
VAL_ 403 CRRR_ObjDirX_Left_01 255 "Invalid" ;
VAL_ 403 CRRR_ObjDirY_Right_00 255 "Invalid" ;
VAL_ 403 CRRR_ObjDirX_Right_00 255 "Invalid" ;
VAL_ 403 CRRR_ObjDirY_Right_01 255 "Invalid" ;
VAL_ 403 CRRR_ObjDirX_Right_01 255 "Invalid" ;
VAL_ 403 CRRR_ObjDirY_Rear_00 255 "Invalid" ;
VAL_ 403 CRRR_ObjDirX_Rear_00 255 "Invalid" ;
VAL_ 403 CRRR_ObjDirY_Rear_01 255 "Invalid" ;
VAL_ 403 CRRR_ObjDirX_Rear_01 255 "Invalid" ;
VAL_ 404 CRFR_FCTB_AEBReqRight 1 "demand" 0 "no demand" ;
VAL_ 404 CRFR_FCTB_EBAReqRight 1 "demand" 0 "no demand" ;
VAL_ 404 CRFR_FCTB_ABALevelRight 7 "reversed" 6 "reversed" 5 "reversed" 4 "reversed" 3 "level 3" 2 "level 2" 1 "level 1" 0 "level 0" ;
VAL_ 404 CRFR_FCTB_ABAReqRight 1 "demand" 0 "no demand" ;
VAL_ 404 CRFR_FCTB_ABPReqRight 1 "demand" 0 "no demand" ;
VAL_ 404 CRFR_FCTA_SetFb 1 "FCTA On" 0 "FCTA Off" ;
VAL_ 404 CRFR_FrontCornerFailure 3 "Left and Right Failure" 2 "Front Right Failure" 1 "Front Left Failure" 0 "No Failure" ;
VAL_ 404 CRFR_FrontCornerBlindness 3 "Left and Right Blindness" 2 "Front Right Blindness" 1 "Front Left Blindness" 0 "No Blindness" ;
VAL_ 404 CRFR_FCTA_Warn_Left 1 "warning" 0 "no warning" ;
VAL_ 404 CRFR_FCTA_Warn_Right 1 "warning" 0 "no warning" ;
VAL_ 404 CRFR_ObjDirY_Left_00 255 "Invalid" ;
VAL_ 404 CRFR_ObjDirX_Left_00 255 "Invalid" ;
VAL_ 404 CRFR_ObjDirY_Left_01 255 "Invalid" ;
VAL_ 404 CRFR_ObjDirX_Left_01 255 "Invalid" ;
VAL_ 404 CRFR_ObjDirY_Right_00 255 "Invalid" ;
VAL_ 404 CRFR_ObjDirX_Right_00 255 "Invalid" ;
VAL_ 404 CRFR_ObjDirY_Right_01 255 "Invalid" ;
VAL_ 404 CRFR_ObjDirX_Right_01 255 "Invalid" ;
VAL_ 404 CRFR_ObjDirY_Front_00 255 "Invalid" ;
VAL_ 404 CRFR_ObjDirX_Front_00 255 "Invalid" ;
VAL_ 404 CRFR_ObjDirY_Front_01 255 "Invalid" ;
VAL_ 404 CRFR_ObjDirX_Front_01 255 "Invalid" ;
VAL_ 416 FRM_AEB_Req 1 "demand" 0 "no demand" ;
VAL_ 416 FRM_ABP_Req 1 "demand" 0 "no demand" ;
VAL_ 458 VCU_VhclActlGearPos 15 "reversed" 14 "reversed" 13 "reversed" 12 "reversed" 11 "reversed" 10 "reversed" 9 "reversed" 8 "reversed" 7 "invalid" 6 "reserved" 5 "reserved" 4 "reserved" 3 "R reverse" 2 "D Drive" 1 "N Neutral" 0 "P Park" ;
VAL_ 458 VCU_PTActlOprtMode 7 "reserved" 6 "reserved" 5 "reserved" 4 "reserved" 3 "Emergency shutdown" 2 "PT Ready" 1 "Standby (high voltage normal)" 0 "OFF" ;
VAL_ 458 VCU_LimpHomeSta 1 "Limp home" 0 "Normal" ;
VAL_ 458 VCU_BrkAPARqst 1 "Break off" 0 "No Break off" ;
VAL_ 458 VCU_VehActlDrvMode 3 "invalid" 2 "SPORT" 1 "ECO" 0 "Nomal" ;
VAL_ 458 VCU_VhclActlGearPosV 1 "valid" 0 "invalid" ;
VAL_ 458 VCU_BrkAPARqstV 1 "Valid" 0 "Invalid" ;
VAL_ 458 VCU_GearShiftInhibited 1 "Inhibit" 0 "Enable" ;
VAL_ 458 VCU_PCUFailSta 1 "Error" 0 "No Error" ;
VAL_ 458 VCU_StrgRecupReqBrkLampOn 1 "Active" 0 "Inactive" ;
VAL_ 458 VCU_PeristalsisModeFb 1 "Peristalsis closed" 0 "Peristalsis opened" ;
VAL_ 458 VCU_QECACC 1 "Error" 0 "No Error" ;
VAL_ 458 VCU_VhclPGearError 1 "P Gear error" 0 "No error" ;
VAL_ 458 VCU_12VBatLowVolSta 3 "reserved" 2 "low SOH warning" 1 "low voltage warning" 0 "no warning" ;
VAL_ 565 BCM_TurnLampSta_Left 1 "ON" 0 "OFF" ;
VAL_ 565 BCM_TurnLampSta_Right 1 "ON" 0 "OFF" ;
VAL_ 565 BCM_FogLampSta_Rear 1 "ON" 0 "OFF" ;
VAL_ 565 BCM_PosLampSta_Left 1 "ON" 0 "OFF" ;
VAL_ 565 BCM_PosLampSta_Right 1 "ON" 0 "OFF" ;
VAL_ 565 BCM_AjarSta_Hood 1 "Open" 0 "Close" ;
VAL_ 565 BCM_AjarSta_Trunk 1 "Open" 0 "Close" ;
VAL_ 565 BCM_DoorAjarSta_FL 1 "Open" 0 "Close" ;
VAL_ 565 BCM_DoorAjarSta_FR 1 "Open" 0 "Close" ;
VAL_ 565 BCM_DoorAjarSta_RL 1 "Open" 0 "Close" ;
VAL_ 565 BCM_DoorAjarSta_RR 1 "Open" 0 "Close" ;
VAL_ 565 BCM_ChrgAjarSta_Fast 1 "Open" 0 "Close" ;
VAL_ 565 BCM_ChrgAjarSta_Slow 1 "Open" 0 "Close" ;
VAL_ 565 BCM_FuelAjarSta_Reserved 1 "Open" 0 "Close" ;
VAL_ 565 BCM_DoorsLockLatchOverHeat 1 "Over Heat" 0 "Normal" ;
VAL_ 565 BCM_LightLeftOnRemind 1 "ON" 0 "OFF" ;
VAL_ 565 BCM_ATWSLightOnReq_PT 1 "Active" 0 "Inactive" ;
VAL_ 565 BCM_ChildLockSta_RL 1 "Locked" 0 "Unlocked" ;
VAL_ 565 BCM_DoorLockSta_FL 1 "Locked" 0 "Unlocked" ;
VAL_ 565 BCM_DoorLockSta_FR_RL_RR 1 "Locked" 0 "Unlocked" ;
VAL_ 565 BCM_AjarStaV_Hood 1 "Valid" 0 "Invalid" ;
VAL_ 565 BCM_HazardLampSts 1 "ON" 0 "OFF" ;
VAL_ 565 BCM_TrunkSwSts_Drv 1 "Pressed" 0 "Not pressed" ;
VAL_ 565 BCM_HighBeamSta 1 "ON" 0 "OFF" ;
VAL_ 565 BCM_LowBeamSta 1 "ON" 0 "OFF" ;
VAL_ 565 BCM_AutoLampStatus 1 "ON" 0 "OFF" ;
VAL_ 565 BCM_FogLampSta_Front 1 "ON" 0 "OFF" ;
VAL_ 565 BCM_TopLampModeFb 1 "Relate to door" 0 "Default" ;
VAL_ 565 BCM_DayRunLightReq 1 "ON" 0 "OFF" ;
VAL_ 565 BCM_BrakeLampSta 1 "ON" 0 "OFF" ;
VAL_ 565 BCM_ReverseLampSta 1 "ON" 0 "OFF" ;
VAL_ 565 BCM_NozzleHeatSta 1 "ON" 0 "OFF" ;
VAL_ 565 BCM_ChildLockSta_RR 1 "Locked" 0 "Unlocked" ;
VAL_ 565 BCM_PDU_Forbidden 1 "Forbidden" 0 "Not Forbidden" ;
VAL_ 565 BCM_BeamLampOpenWarn 1 "Alarm" 0 "No Alarm" ;
VAL_ 565 BCM_BrakePadelSta 1 "Pressed" 0 "Not Pressed" ;
VAL_ 565 BCM_FuelLidSts 3 "Reserved" 2 "default" 1 "On" 0 "Off" ;
VAL_ 565 BCM_SSBSwSta 1 "Press" 0 "No Press" ;
VAL_ 565 BCM_KeyInCarSta 1 "In Car" 0 "Not In Car" ;
VAL_ 565 BCM_BodyWarnSts 3 "Partially Armed" 2 "Alarm" 1 "Armed" 0 "Disarmed" ;
VAL_ 565 BCM_WiperCtrl_Rear 3 "Reserved" 2 "Rear Wiper Interval active" 1 "Rear Wiper spd low active" 0 "Rear Wiping off" ;
VAL_ 565 BCM_HeavyRainInd 1 "On" 0 "Off" ;
VAL_ 565 BCM_WiperCtrl_Front 5 "Front Auto wiping active" 4 "Interval wipe active" 3 "Front Mist wiping active" 2 "Front Wiper spd high active" 1 "Front Wiper spd low active" 0 "Front Wiping off" ;
VAL_ 565 BCM_PTGUnlockCmd 15 "Reserved" 14 "Unlocking Condition Discontent" 13 "Reserved" 12 "Foot Sensor Trigger" 11 "RKE Stop" 10 "RKE Open" 9 "RKE Close" 8 "Reserved" 7 "Tailgate Switch Trigger" 6 "TBOX Open" 5 "TBOX Close" 4 "IP Close SW Presss Reserved" 3 "IP Close SW Release Reserved" 2 "IP Switch Open" 1 "IP Switch Close" 0 "No command" ;
VAL_ 601 SCM_AutoLightSW_StsInvalid 1 "Valid" 0 "Invalid" ;
VAL_ 601 SCM_AutoLightSW_Sts 1 "ON" 0 "OFF" ;
VAL_ 601 SCM_FrontWasherSW_StsInvalid 1 "Valid" 0 "Invalid" ;
VAL_ 601 SCM_FrontWasherSW_Sts 1 "Washer Spray" 0 "Washer OFF" ;
VAL_ 601 SCM_LowBeamSW_StsInvalid 1 "Valid" 0 "Invalid" ;
VAL_ 601 SCM_LowBeamSW_Sts 1 "ON" 0 "OFF" ;
VAL_ 601 SCM_HighBeamSW_StsInvalid 1 "Valid" 0 "Invalid" ;
VAL_ 601 SCM_HighBeamSW_Sts 1 "Pressed" 0 "Not pressed" ;
VAL_ 601 SCM_PositionLightSW_StsInvalid 1 "Valid" 0 "Invalid" ;
VAL_ 601 SCM_PositionLightSW_Sts 1 "ON" 0 "OFF" ;
VAL_ 601 SCM_FlashLightSW_StsInvalid 1 "Valid" 0 "Invalid" ;
VAL_ 601 SCM_FlashLightSW_Sts 1 "Pressed" 0 "Not pressed" ;
VAL_ 601 SCM_TurnLightLeverSta 3 "Invalid" 2 "Turn Right" 1 "Turn Left" 0 "Default" ;
VAL_ 601 SCM_TripSW_Sts 3 "Invalid" 2 "Reserved" 1 "Press" 0 "No Press" ;
VAL_ 601 SCM_RearFogLightSW_StsInvalid 1 "Valid" 0 "Invalid" ;
VAL_ 601 SCM_RearFogLightSW_Sts 1 "ON" 0 "OFF" ;
VAL_ 601 SCM_FrontFogLightSW_StsInvalid 1 "Valid" 0 "Invalid" ;
VAL_ 601 SCM_FrontFogLightSW_Sts 1 "ON" 0 "OFF" ;
VAL_ 601 SCM_RearWasherSwStsV 1 "Valid" 0 "Invalid" ;
VAL_ 601 SCM_RearWasherSwSts 1 "Washer Spray" 0 "Washer OFF" ;
VAL_ 601 SCM_FrontWipingIntervalSW_Sts 7 "Reserved" 6 "Sensitivity 7" 5 "Sensitivity 6" 4 "Sensitivity 5" 3 "Sensitivity 4" 2 "Sensitivity3" 1 "Sensitivity 2" 0 "Sensitivity 1(most insensitive)" ;
VAL_ 601 SCM_FrontWipingMode 7 "Invalid" 6 "Reserved" 5 "Reserved" 4 "Front Auto/Interval wipe active" 3 "Front Mist wiping active" 2 "Front Wiper spd high active" 1 "Front Wiper spd low active" 0 "Front Wiping off" ;
VAL_ 601 SCM_RearWipingMode 3 "Invalid" 2 "Rear Wiper Interval" 1 "Rear Wiper uniformity speed" 0 "RearWiping off" ;
VAL_ 622 HU_ICU_ICUTotalOdometer 16777215 "invalid" ;
VAL_ 753 AC_EnvirTempV 1 "Valid" 0 "Invalid" ;
VAL_ 753 AC_BatPumpFailSta 1 "error" 0 "no error" ;
VAL_ 753 AC_HVHFailSta_HVAC 1 "Error" 0 "No Error" ;
VAL_ 753 AC_HVHActlOprtMode_HVAC 3 "HV air heat emergency shutdown" 2 "HV air heatingr running" 1 "HV air heating standby" 0 "HV air heating off" ;
VAL_ 753 AC_FailSta 1 "Error" 0 "No Error" ;
VAL_ 753 AC_ActlOprtMode 3 "Ventilate" 2 "Economy" 1 "Comfort" 0 "Off" ;
VAL_ 753 AC_RefrgHiPressureV 1 "Valid" 0 "Invalid" ;
VAL_ 162 EPS_SteerWheelAngle 7800 "Invalid" ;
VAL_ 162 EPS_SteerWheelAngleValid 1 "Valid" 0 "Not valid" ;
VAL_ 162 EPS_RotSpeed 32767 "invalid" ;
VAL_ 162 EPS_SteerWheelAngleCalibrated 1 "Calibrated" 0 "Not calibrated" ;
VAL_ 162 EPS_SteerWheelAngleFailure 1 "Failure" 0 "No failure" ;
VAL_ 162 EPS_ElectricPowerSta 3 "internal error" 2 "assisting" 1 "waiting" 0 "self test" ;
VAL_ 163 EPS_LatDrvLvl12SrvAvl 3 "Reserved" 2 "Available" 1 "FailureDetected" 0 "NotAvailable" ;
VAL_ 163 EPS_LatMCHptcWrnSrvAvl 3 "Reserved" 2 "Available" 1 "FailureDetected" 0 "NotAvailable" ;
VAL_ 163 EPS_LatMCSteerTqActive 1 "Steering Torque service is active" 0 "Steering Torque service is not active" ;
VAL_ 163 EPS_PSCMIntRPCMaxTrq 2047 "Invalid" ;
VAL_ 163 EPS_TorsionBarTorqueQF 3 "The data is calculated with the specified accuracy" 2 "The accuracy of the data is not within specification" 1 "Data is temporarily undefinable, evaluation in progress" 0 "The accuracy of the data is undefinable" ;
VAL_ 163 EPS_LatMCHptcWrnActive 1 "Haptic Warning service is active" 0 "Haptic Warning service is not active" ;
VAL_ 163 EPS_PSCMIntRPCMinTrq 2047 "Invalid" ;
VAL_ 668 IPM_RearFogLampStatus 1 "ON" 0 "OFF" ;
VAL_ 668 IPM_FoldingMirrorPosStatus 3 "Output low level" 2 "Reserve" 1 "Output high level" 0 "Default" ;
VAL_ 668 IPM_DRLStatus 1 "ON" 0 "OFF" ;
VAL_ 389 APA_SafeDrvrHandoverReq 1 "Requested" 0 "No Request" ;
VAL_ 389 APA_ReqReleaseEPB 1 "request to release" 0 "no request" ;
VAL_ 389 APA_ReqReleaseEPBV 1 "valid" 0 "invalid" ;
VAL_ 389 APA_LSMSubMTReq 3 "Reserved" 2 "LSM" 1 "drive" 0 "none" ;
VAL_ 389 APA_LSMSubMTLevel 3 "reserved" 2 "Level 23_RPA" 1 "Level 12_APA" 0 "none" ;
VAL_ 389 APA_LSMSubMTLong 3 "reserved" 2 "emergency" 1 "comfort" 0 "none" ;
VAL_ 389 APA_LSMBrakeEmgcyPrep 1 "Request" 0 "No Request" ;
VAL_ 389 APA_DrvPresenceExt 1 "True" 0 "False" ;
VAL_ 389 APA_LSMComfBrakeReq 3 "Reserved" 2 "ComfBrakeReq_Type2" 1 "ComfBrakeReq_Type1" 0 "ComfBrakeReq_NoReq" ;
VAL_ 389 APA_EPS_SetSteeringWheelAng 7800 "Invalid" ;
VAL_ 389 APA_DrvReq 31 "Reserved" 30 "Reserved" 29 "Reserved" 28 "Reserved" 27 "Req_RPA_Confirm" 26 "Req_EPB_Released" 25 "Req_Parking_Inactive" 24 "Req_Parking_Active" 23 "Req_Gear_RND_Reserved" 22 "Req_POC Direction Select" 21 "Req_Function off" 20 "Req_Process bar" 19 "Req_Release Brake" 18 "Req_Confirm_Press DM Switch" 17 "Req_Press Brake Pedal" 16 "Req_Surround_View" 15 "Req_Buckle Seat Belt" 14 "Req_Close Door_all doors" 13 "Req_Close Engine Front Door_Reserved" 12 "Req_Close Trunk_Reserved" 11 "Req_Leave_Car" 10 "Req EPB_Applied" 9 "Req_Connect_Phone" 8 "Req_Function Select_RPA_APA_Reserved" 7 "Req_Turn_lever_Reserved" 6 "Req_PS_ID_Selection" 5 "Req_Stop" 4 "Req_SearchingProcess" 3 "Req_Slow_Down" 2 "Req_Gear_D" 1 "Req_Function Select" 0 "No Request" ;
VAL_ 389 APA_RPA_status 1 "Running" 0 "none" ;
VAL_ 389 APA_EPS_Control_Request 3 "Reserved" 2 "Active" 1 "Request control EPS" 0 "No Request" ;
VAL_ 389 APA_Status 7 "Reserved" 6 "Terminated" 5 "Failure" 4 "Completed" 3 "Guidance active" 2 "Searching" 1 "Standby" 0 "Off" ;
VAL_ 389 APA_RPA_AvailSts 1 "Available" 0 "Not Available" ;
VAL_ 448 ADC_TextInfoACCTJA 15 "Reserved" 14 "Reserved" 13 "Reserved" 12 "TJA_ICA Unable to Active" 11 "TJA_ICA emergency exit" 10 "TJA_ICA normal exit" 9 "TJA_ICA error" 8 "ACC error" 7 "ACC exit" 6 "HDC on" 5 "ESP off" 4 "EPB apply" 3 "No forward gear" 2 "Driver seat belt unfastened" 1 "Door open" 0 "no display" ;
VAL_ 448 ADC_AccTrqReqEna 1 "valid torque demand" 0 "no demand" ;
VAL_ 448 ADC_Acc_TgtAxReq 1 "demand" 0 "no demand" ;
VAL_ 448 ADC_Acc_Mode 7 "Failure mode" 6 "Standstill" 5 "Override" 4 "Brake-Only mode" 3 "Active-Control mode" 2 "Stand-By mode" 1 "Passive mode" 0 "OFF mode" ;
VAL_ 448 ADC_AccReq_DriveOff 1 "demand" 0 "no demand" ;
VAL_ 448 ADC_AccReq_Standstill 1 "demand" 0 "no demand" ;
VAL_ 448 ADC_SteerTqReq 4095 "invalid" ;
VAL_ 448 ADC_SteerTqReqActive 3 "Reserved" 2 "Reserved" 1 "Steering Torque request is active" 0 "Steering Torque request is not active" ;
VAL_ 448 ADC_ActDrvAsstSts 7 "Reserved" 6 "Reserved" 5 "Reserved" 4 "TJA_ICA failure" 3 "TJA_ICA Passive" 2 "TJA_ICA Active" 1 "TJA_ICA Standby" 0 "TJA_ICA Off" ;
VAL_ 448 ADC_DA_EPSModeReq 1 "Request Advanced Mode" 0 "Not Request" ;
